VERSION ""

NS_ :

BS_:

BU_: HCM IPMA_ADAS PSCM ABS_ESC PCM ECM_HEV VDM CMR_DSMC SOBDMC_HPCM GWM _delete AWD_DLCM GENERIC TSTR

BO_ 985 IPMA_Data2: 8 IPMA_ADAS
 SG_ LongCtrlBrk_D_Rq : 25|2@0+ (1,0) [0|3] "SED"  SOBDMC_HPCM,PCM,ECM_HEV,GWM
 SG_ LongCtrlEnblDRq_No_Cs : 63|8@0+ (1,0) [0|255] "Unitless"  SOBDMC_HPCM,ECM_HEV,GWM,PCM
 SG_ LongCtrlEnblDRq_No_Cnt : 29|4@0+ (1,0) [0|15] "Unitless"  SOBDMC_HPCM,ECM_HEV,GWM,PCM
 SG_ AdbDrvSide_B_Stat : 35|1@0+ (1,0) [0|1] "SED"  GWM,HCM
 SG_ LcwaMsgTxt_D_Stat : 37|2@0+ (1,0) [0|3] "SED"  GWM
 SG_ AdbDividedRoad_B_Stat : 30|1@0+ (1,0) [0|1] "SED"  HCM,GWM
 SG_ IsaVLimUnit_D_Rq : 15|2@0+ (1,0) [0|3] "SED"  ECM_HEV,GWM,PCM
 SG_ SblmYieldScnr_B_Stat : 31|1@0+ (1,0) [0|1] "SED"  HCM,GWM
 SG_ SblmStopScnr_B_Stat : 8|1@0+ (1,0) [0|1] "SED"  HCM,GWM
 SG_ IsaVLim_D_Rq : 7|8@0+ (1,0) [0|255] "SED"  ECM_HEV,GWM,PCM
 SG_ IaccVLimUnit_D_Rq : 11|2@0+ (1,0) [0|3] "SED"  ECM_HEV,GWM,PCM
 SG_ IaccVLim_D_Rq : 23|8@0+ (1,0) [0|255] "SED"  ECM_HEV,GWM,PCM
 SG_ DasAlrtInfo_D_Dsply : 13|2@0+ (1,0) [0|3] "SED"  GWM
 SG_ SblmRndAbtScnr_B_Stat : 9|1@0+ (1,0) [0|1] "SED"  HCM,GWM
 SG_ PwSustnAdas_B_Rq : 48|1@0+ (1,0) [0|1] "SED"  GWM
 SG_ ClrExitAsstMsgTxt_D_Rq : 52|4@0+ (1,0) [0|15] "SED"  GWM
 SG_ ClrExitAsstChime_D_Rq : 55|3@0+ (1,0) [0|7] "SED"  GWM
 SG_ LongCtrlEnbl_D_Rq : 42|3@0+ (1,0) [0|7] "SED"  SOBDMC_HPCM,GWM,ECM_HEV,PCM
 SG_ SblmPedCrossScnr_B_Stat : 33|1@0+ (1,0) [0|1] "SED"  GWM,HCM
 SG_ TsrRegionTxt_D_Stat : 47|5@0+ (1,0) [0|31] "SED"  GWM
 SG_ LdwChime_B_Rq : 34|1@0+ (1,0) [0|1] "SED"  GWM
 SG_ ClrExitAsst_D_Stat : 39|2@0+ (1,0) [0|3] "SED"  GWM

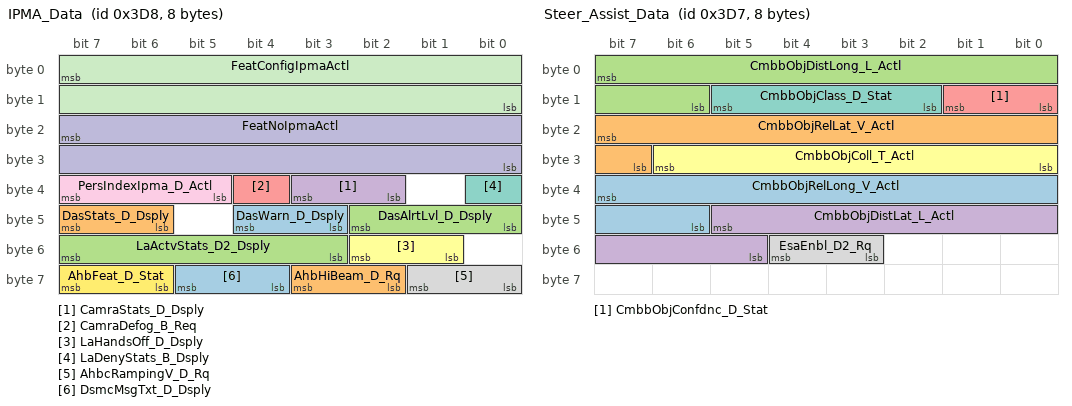
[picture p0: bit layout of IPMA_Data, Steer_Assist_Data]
BO_ 984 IPMA_Data: 8 IPMA_ADAS
 SG_ DasWarn_D_Dsply : 44|2@0+ (1,0) [0|3] "SED"  GWM
 SG_ DasStats_D_Dsply : 47|2@0+ (1,0) [0|3] "SED"  GWM
 SG_ DasAlrtLvl_D_Dsply : 42|3@0+ (1,0) [0|7] "SED"  GWM
 SG_ CamraStats_D_Dsply : 35|2@0+ (1,0) [0|3] "SED"  GWM
 SG_ CamraDefog_B_Req : 36|1@0+ (1,0) [0|1] "SED"  GWM
 SG_ LaHandsOff_D_Dsply : 50|2@0+ (1,0) [0|3] "SED"  GWM
 SG_ LaDenyStats_B_Dsply : 32|1@0+ (1,0) [0|1] "SED"  GWM
 SG_ AhbcRampingV_D_Rq : 57|2@0+ (1,0) [0|3] "SED"  HCM,GWM
 SG_ PersIndexIpma_D_Actl : 39|3@0+ (1,0) [0|7] "SED"  GWM
 SG_ FeatNoIpmaActl : 23|16@0+ (1,0) [0|65535] "Number"  GWM
 SG_ FeatConfigIpmaActl : 7|16@0+ (1,0) [0|65535] "Undefined"  GWM
 SG_ AhbFeat_D_Stat : 63|2@0+ (1,0) [0|3] "SED"  GWM
 SG_ DsmcMsgTxt_D_Dsply : 61|2@0+ (1,0) [0|3] "SED"  GWM
 SG_ AhbHiBeam_D_Rq : 59|2@0+ (1,0) [0|3] "SED"  HCM,GWM
 SG_ LaActvStats_D2_Dsply : 55|5@0+ (1,0) [0|31] "SED"  GWM

BO_ 983 Steer_Assist_Data: 8 IPMA_ADAS
 SG_ CmbbObjRelLong_V_Actl : 39|10@0+ (0.1,-102.1) [-102.1|0] "meters/sec"  PSCM
 SG_ CmbbObjRelLat_V_Actl : 23|9@0+ (0.1,-25.5) [-25.5|25.4] "meters/sec"  PSCM
 SG_ CmbbObjDistLong_L_Actl : 7|10@0+ (0.1,0) [0|102.1] "meter"  PSCM
 SG_ CmbbObjDistLat_L_Actl : 45|9@0+ (0.1,-25.5) [-25.5|25.4] "meter"  PSCM
 SG_ CmbbObjConfdnc_D_Stat : 9|2@0+ (1,0) [0|3] "SED"  PSCM
 SG_ CmbbObjColl_T_Actl : 30|7@0+ (0.05,0) [0|6.25] "second"  PSCM
 SG_ CmbbObjClass_D_Stat : 13|4@0+ (1,0) [0|15] "SED"  PSCM
 SG_ EsaEnbl_D2_Rq : 52|2@0+ (1,0) [0|3] "SED"  PSCM

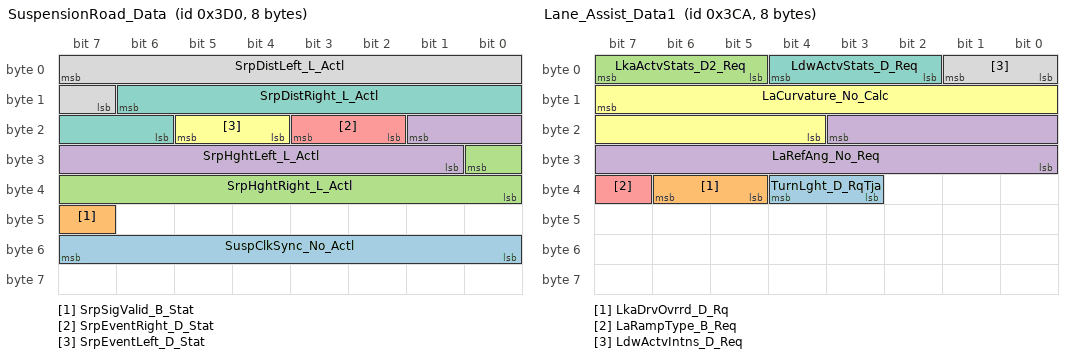
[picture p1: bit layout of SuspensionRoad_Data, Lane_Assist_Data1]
BO_ 976 SuspensionRoad_Data: 8 IPMA_ADAS
 SG_ SuspClkSync_No_Actl : 55|8@0+ (1,0) [0|253] "unitless"  GWM
 SG_ SrpSigValid_B_Stat : 47|1@0+ (1,0) [0|1] "SED"  GWM
 SG_ SrpHghtRight_L_Actl : 24|9@0+ (0.000625,-0.16) [-0.16|0.158125] "meter"  GWM
 SG_ SrpHghtLeft_L_Actl : 17|9@0+ (0.000625,-0.16) [-0.16|0.158125] "meter"  GWM
 SG_ SrpEventRight_D_Stat : 19|2@0+ (1,0) [0|3] "SED"  GWM
 SG_ SrpEventLeft_D_Stat : 21|2@0+ (1,0) [0|3] "SED"  GWM
 SG_ SrpDistRight_L_Actl : 14|9@0+ (0.02,0) [0|10.18] "meter"  GWM
 SG_ SrpDistLeft_L_Actl : 7|9@0+ (0.02,0) [0|10.18] "meter"  GWM

BO_ 973 Traffic_RecognitnData: 8 IPMA_ADAS
 SG_ PersCtaSplitView_D_Stat : 12|2@0+ (1,0) [0|3] "SED"  GWM
 SG_ TsrVl2PrmntMsgTxt_D_Rq : 60|2@0+ (1,0) [0|3] "SED"  GWM
 SG_ TsrVl1PrmntMsgTxt_D_Rq : 41|2@0+ (1,0) [0|3] "SED"  GWM
 SG_ TsrVl2RstrcMsgTxt2_D_Rq : 63|3@0+ (1,0) [0|7] "SED"  GWM
 SG_ TsrVl1RstrcMsgTxt2_D_Rq : 51|3@0+ (1,0) [0|7] "SED"  GWM
 SG_ TsrOvtkMsgTxt2_D_Rq : 55|4@0+ (1,0) [0|15] "SED"  GWM
 SG_ WwaWarn_B_Rq : 48|1@0+ (1,0) [0|1] "SED"  GWM
 SG_ TsrVlUnitMsgTxt_D_Rq : 43|2@0+ (1,0) [0|3] "SED"  GWM
 SG_ TsrVLim2MsgTxt_D_Rq : 39|8@0+ (1,0) [0|255] "SED"  GWM
 SG_ TsrVLim1MsgTxt_D_Rq : 31|8@0+ (1,0) [0|255] "SED"  GWM
 SG_ TsrVl2StatMsgTxt_D_Rq : 47|2@0+ (1,0) [0|3] "SED"  GWM
 SG_ TsrVl2RstrcMsgTxt_D_Rq : 17|2@0+ (1,0) [0|3] "SED"  GWM
 SG_ TsrVl1StatMsgTxt_D_Rq : 21|2@0+ (1,0) [0|3] "SED"  GWM
 SG_ TsrVl1RstrcMsgTxt_D_Rq : 23|2@0+ (1,0) [0|3] "SED"  GWM
 SG_ TsrStatMsgTxt_D_Rq : 10|3@0+ (1,0) [0|7] "SED"  GWM
 SG_ TsrOvtkStatMsgTxt_D_Rq : 1|2@0+ (1,0) [0|3] "SED"  GWM
 SG_ TsrOvtkMsgTxt_D_Rq : 15|3@0+ (1,0) [0|7] "SED"  GWM
 SG_ TsrOswWarnMsgTxt_D_Rq : 3|2@0+ (1,0) [0|3] "SED"  GWM
 SG_ TsrMsgTxt_D_Rq : 7|4@0+ (1,0) [0|15] "SED"  GWM
 SG_ LaSysOffStat_D_Dsply : 58|2@0+ (1,0) [0|3] "SED"  GWM

BO_ 970 Lane_Assist_Data1: 8 IPMA_ADAS
 SG_ TurnLght_D_RqTja : 36|2@0+ (1,0) [0|3] "SED"  GWM
 SG_ LkaDrvOvrrd_D_Rq : 38|2@0+ (1,0) [0|3] "SED"  PSCM
 SG_ LkaActvStats_D2_Req : 7|3@0+ (1,0) [0|7] "SED"  PSCM
 SG_ LaRefAng_No_Req : 19|12@0+ (0.05,-102.4) [-102.4|102.3] "mrad"  PSCM
 SG_ LaRampType_B_Req : 39|1@0+ (1,0) [0|1] "SED"  PSCM
 SG_ LaCurvature_No_Calc : 15|12@0+ (5E-006,-0.01024) [-0.01024|0.01023] "1/m"  PSCM
 SG_ LdwActvStats_D_Req : 4|3@0+ (1,0) [0|7] "SED"  PSCM
 SG_ LdwActvIntns_D_Req : 1|2@0+ (1,0) [0|3] "SED"  PSCM

BO_ 394 ACCDATA_3: 8 IPMA_ADAS
 SG_ AccTrgDist2_D_Dsply : 27|4@0+ (1,0) [0|15] "SED"  GWM
 SG_ AccStopRes_B_Dsply : 54|1@0+ (1,0) [0|1] "SED"  GWM
 SG_ TjaWarn_D_Rq : 50|3@0+ (1,0) [0|7] "SED"  GWM
 SG_ Tja_D_Stat : 44|3@0+ (1,0) [0|7] "SED"  CMR_DSMC,GWM
 SG_ TjaMsgTxt_D_Dsply : 53|3@0+ (1,0) [0|7] "SED"  GWM
 SG_ IaccLamp_D_Rq : 46|2@0+ (1,0) [0|3] "SED"  GWM
 SG_ AccMsgTxt_D2_Rq : 31|4@0+ (1,0) [0|15] "SED"  GWM
 SG_ FcwDeny_B_Dsply : 10|1@0+ (1,0) [0|1] "SED"  GWM
 SG_ FcwMemStat_B_Actl : 13|1@0+ (1,0) [0|1] "SED"  GWM
 SG_ AccTGap_B_Dsply : 35|1@0+ (1,0) [0|1] "SED"  GWM
 SG_ CadsAlignIncplt_B_Actl : 11|1@0+ (1,0) [0|1] "SED"  GWM
 SG_ AccFllwMde_B_Dsply : 17|1@0+ (1,0) [0|1] "SED"  GWM
 SG_ CadsRadrBlck_B_Actl : 22|1@0+ (1,0) [0|1] "SED"  GWM
 SG_ CmbbPostEvnt_B_Dsply : 15|1@0+ (1,0) [0|1] "SED"  GWM
 SG_ AccStopMde_B_Dsply : 0|1@0+ (1,0) [0|1] "SED"  GWM
 SG_ FcwMemSens_D_Actl : 20|2@0+ (1,0) [0|3] "SED"  GWM
 SG_ FcwMsgTxt_D_Rq : 7|3@0+ (1,0) [0|7] "SED"  GWM
 SG_ AccWarn_D_Dsply : 39|2@0+ (1,0) [0|3] "SED"  GWM
 SG_ FcwVisblWarn_B_Rq : 47|1@0+ (1,0) [0|1] "SED"  GWM
 SG_ FcwAudioWarn_B_Rq : 8|1@0+ (1,0) [0|1] "SED"  GWM
 SG_ AccTGap_D_Dsply : 34|3@0+ (1,0) [0|7] "SED"  GWM
 SG_ AccMemEnbl_B_RqDrv : 36|1@0+ (1,0) [0|1] "SED"  GWM
 SG_ AccStopStat_D_Dsply : 41|2@0+ (1,0) [0|3] "SED"  GWM
 SG_ HaDsply_No_Cs : 63|8@0+ (1,0) [0|255] "Unitless"  GWM
 SG_ HaDsply_No_Cnt : 4|4@0+ (1,0) [0|15] "Unitless"  GWM

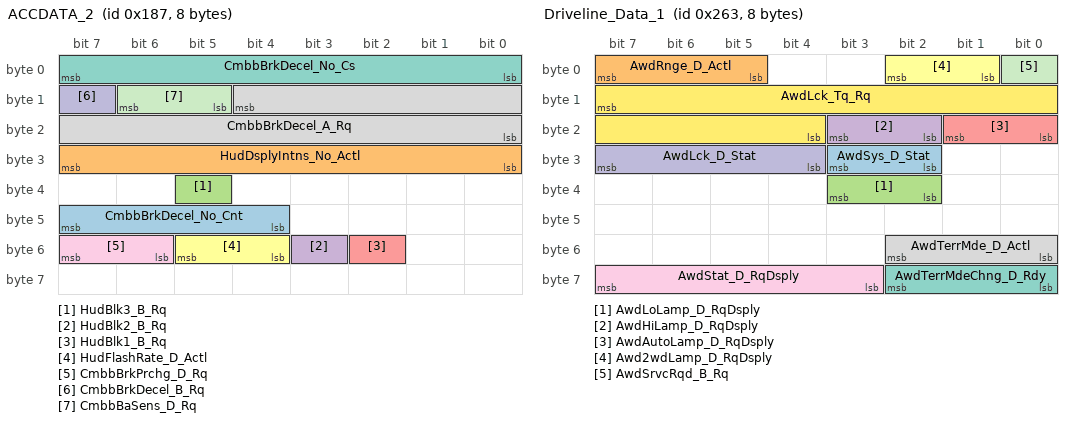
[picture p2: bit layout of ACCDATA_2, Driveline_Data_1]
BO_ 391 ACCDATA_2: 8 IPMA_ADAS
 SG_ CmbbBrkDecel_No_Cnt : 47|4@0+ (1,0) [0|15] "Unitless"  ABS_ESC
 SG_ HudDsplyIntns_No_Actl : 31|8@0+ (0.5,0) [0|100] "%"  GWM
 SG_ HudBlk3_B_Rq : 37|1@0+ (1,0) [0|1] "SED"  GWM
 SG_ HudBlk2_B_Rq : 51|1@0+ (1,0) [0|1] "SED"  GWM
 SG_ HudBlk1_B_Rq : 50|1@0+ (1,0) [0|1] "SED"  GWM
 SG_ HudFlashRate_D_Actl : 53|2@0+ (1,0) [0|3] "SED"  GWM
 SG_ CmbbBrkDecel_No_Cs : 7|8@0+ (1,0) [0|255] "Unitless"  ABS_ESC
 SG_ CmbbBrkDecel_A_Rq : 12|13@0+ (0.0039,-20) [-20|11.9449] "m/s^2"  ABS_ESC,GWM
 SG_ CmbbBrkPrchg_D_Rq : 55|2@0+ (1,0) [0|3] "SED"  ABS_ESC,GWM
 SG_ CmbbBrkDecel_B_Rq : 15|1@0+ (1,0) [0|1] "SED"  ABS_ESC,GWM,CMR_DSMC
 SG_ CmbbBaSens_D_Rq : 14|2@0+ (1,0) [0|3] "SED"  ABS_ESC,GWM

BO_ 390 ACCDATA: 8 IPMA_ADAS
 SG_ AccBrkTot_A_Rq : 4|13@0+ (0.0039,-20) [-20|11.9449] "m/s^2"  ABS_ESC
 SG_ AccPrpl_A_Pred : 17|10@0+ (0.01,-5) [-5|5.23] "m/s^2"  ECM_HEV,PCM
 SG_ AccVeh_V_Trg : 32|9@0+ (0.5,0) [0|255.5] "kph"  PCM
 SG_ AccBrkPrkEl_B_Rq : 38|1@0+ (1,0) [0|1] "SED"  ABS_ESC
 SG_ Cmbb_B_Enbl : 50|1@0+ (1,0) [0|1] "SED"  GWM
 SG_ CmbbOvrrd_B_RqDrv : 51|1@0+ (1,0) [0|1] "SED"  GWM
 SG_ CmbbDeny_B_Actl : 37|1@0+ (1,0) [0|1] "SED"  SOBDMC_HPCM,GWM,ABS_ESC
 SG_ CmbbEngTqMn_B_Rq : 52|1@0+ (1,0) [0|1] "SED"  SOBDMC_HPCM,ECM_HEV,PCM,GWM
 SG_ AccPrpl_A_Rq : 49|10@0+ (0.01,-5) [-5|5.23] "m/s^2"  ECM_HEV,PCM
 SG_ AccDeny_B_Rq : 53|1@0+ (1,0) [0|1] "SED"  ECM_HEV,PCM
 SG_ AccResumEnbl_B_Rq : 33|1@0+ (1,0) [0|1] "SED"  ECM_HEV,PCM
 SG_ AccCancl_B_Rq : 39|1@0+ (1,0) [0|1] "SED"  ECM_HEV,PCM
 SG_ AccBrkPrchg_B_Rq : 54|1@0+ (1,0) [0|1] "SED"  ABS_ESC
 SG_ AccBrkDecel_B_Rq : 55|1@0+ (1,0) [0|1] "SED"  ABS_ESC
 SG_ AccStopStat_B_Rq : 34|1@0+ (1,0) [0|1] "SED"  ECM_HEV,PCM,ABS_ESC
 SG_ AccAutoResum_D_Rq : 7|2@0+ (1,0) [0|3] "SED"  ECM_HEV,PCM
 SG_ AccBrkPulse_B_Rq : 36|1@0+ (1,0) [0|1] "SED"  GWM,ABS_ESC

BO_ 611 Driveline_Data_1: 8 AWD_DLCM
 SG_ AwdSys_D_Stat : 27|2@0+ (1,0) [0|3] "SED"  GWM
 SG_ AwdRnge_D_Actl : 7|3@0+ (1,0) [0|7] "SED"  GWM
 SG_ AwdLoLamp_D_RqDsply : 35|2@0+ (1,0) [0|3] "SED"  GWM
 SG_ AwdHiLamp_D_RqDsply : 19|2@0+ (1,0) [0|3] "SED"  GWM
 SG_ AwdAutoLamp_D_RqDsply : 17|2@0+ (1,0) [0|3] "SED"  GWM
 SG_ Awd2wdLamp_D_RqDsply : 2|2@0+ (1,0) [0|3] "SED"  GWM
 SG_ AwdTerrMdeChng_D_Rdy : 58|3@0+ (1,0) [0|7] "SED"  GWM
 SG_ AwdTerrMde_D_Actl : 50|3@0+ (1,0) [0|7] "SED"  GWM
 SG_ AwdStat_D_RqDsply : 63|5@0+ (1,0) [0|31] "SED"  ABS_ESC,GWM
 SG_ AwdLck_D_Stat : 31|4@0+ (1,0) [0|15] "SED"  ABS_ESC,PSCM,GWM,PCM
 SG_ AwdSrvcRqd_B_Rq : 0|1@0+ (1,0) [0|1] "SED"  ABS_ESC,GWM
 SG_ AwdLck_Tq_Rq : 15|12@0+ (1,0) [0|4093] "Nm"  ABS_ESC,GWM

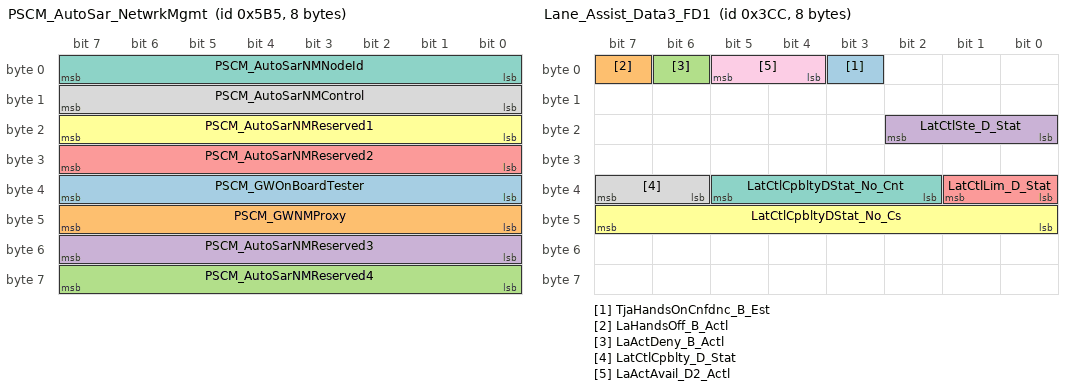
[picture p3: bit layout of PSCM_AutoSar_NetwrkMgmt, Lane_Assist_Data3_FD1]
BO_ 1461 PSCM_AutoSar_NetwrkMgmt: 8 PSCM
 SG_ PSCM_GWOnBoardTester : 39|8@0+ (1,0) [0|255] "unitless"  GENERIC,ABS_ESC
 SG_ PSCM_GWNMProxy : 47|8@0+ (1,0) [0|255] "unitless"  GENERIC,ABS_ESC
 SG_ PSCM_AutoSarNMReserved4 : 63|8@0+ (1,0) [0|255] "unitless"  GENERIC,ABS_ESC
 SG_ PSCM_AutoSarNMReserved3 : 55|8@0+ (1,0) [0|255] "unitless"  GENERIC,ABS_ESC
 SG_ PSCM_AutoSarNMReserved2 : 31|8@0+ (1,0) [0|255] "unitless"  ABS_ESC,GENERIC
 SG_ PSCM_AutoSarNMReserved1 : 23|8@0+ (1,0) [0|255] "unitless"  ABS_ESC,GENERIC
 SG_ PSCM_AutoSarNMNodeId : 7|8@0+ (1,0) [0|255] "unitless"  ABS_ESC,GENERIC
 SG_ PSCM_AutoSarNMControl : 15|8@0+ (1,0) [0|255] "unitless"  ABS_ESC,GENERIC

BO_ 1047 TrailerAid_Data2: 8 PSCM
 SG_ EsaOn_B_Stat : 23|1@0+ (1,0) [0|1] "SED"  GWM
 SG_ SelDrvMdeSte_D_Stat : 17|2@0+ (1,0) [0|3] "SED"  ABS_ESC

BO_ 972 Lane_Assist_Data3_FD1: 8 PSCM
 SG_ TjaHandsOnCnfdnc_B_Est : 3|1@0+ (1,0) [0|1] "SED"  GWM,IPMA_ADAS
 SG_ LaHandsOff_B_Actl : 7|1@0+ (1,0) [0|1] "SED"  IPMA_ADAS,GWM
 SG_ LaActDeny_B_Actl : 6|1@0+ (1,0) [0|1] "SED"  IPMA_ADAS,GWM
 SG_ LatCtlSte_D_Stat : 18|3@0+ (1,0) [0|7] "SED"  IPMA_ADAS,GWM
 SG_ LatCtlLim_D_Stat : 33|2@0+ (1,0) [0|3] "SED"  IPMA_ADAS,GWM
 SG_ LatCtlCpbltyDStat_No_Cs : 47|8@0+ (1,0) [0|255] "Unitless"  GWM,IPMA_ADAS
 SG_ LatCtlCpbltyDStat_No_Cnt : 37|4@0+ (1,0) [0|15] "Unitless"  GWM,IPMA_ADAS
 SG_ LatCtlCpblty_D_Stat : 39|2@0+ (1,0) [0|3] "SED"  GWM,IPMA_ADAS
 SG_ LaActAvail_D2_Actl : 5|2@0+ (1,0) [0|3] "SED"  IPMA_ADAS,GWM

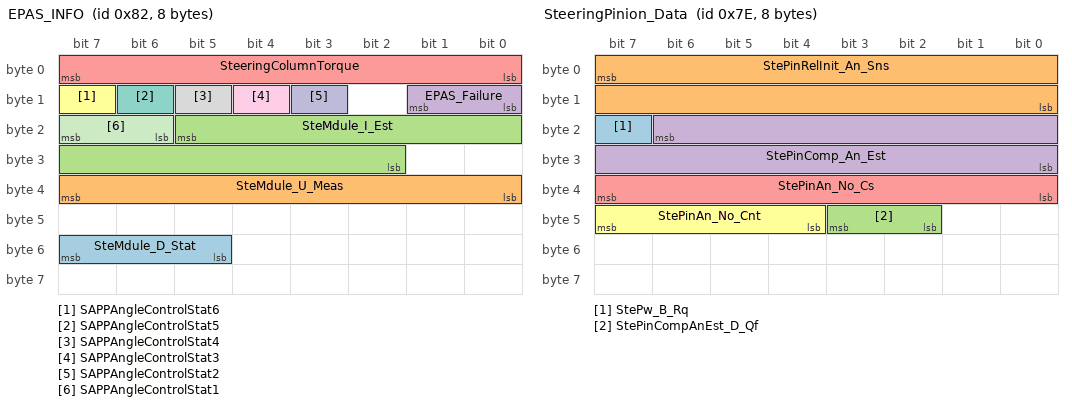
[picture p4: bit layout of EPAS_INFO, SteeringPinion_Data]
BO_ 130 EPAS_INFO: 8 PSCM
 SG_ SteMdule_D_Stat : 55|3@0+ (1,0) [0|7] "SED"  GWM
 SG_ SteMdule_U_Meas : 39|8@0+ (0.05,6) [6|18.7] "Volts"  GWM
 SG_ SteMdule_I_Est : 21|12@0+ (0.05,-64) [-64|140.7] "Amps"  GWM
 SG_ EPAS_Failure : 9|2@0+ (1,0) [0|3] "SED"  IPMA_ADAS,GWM
 SG_ SteeringColumnTorque : 7|8@0+ (0.0625,-8) [-8|7.8125] "Nm"  IPMA_ADAS
 SG_ SAPPAngleControlStat6 : 15|1@0+ (1,0) [0|1] "SED"  IPMA_ADAS
 SG_ SAPPAngleControlStat5 : 14|1@0+ (1,0) [0|1] "SED"  IPMA_ADAS
 SG_ SAPPAngleControlStat4 : 13|1@0+ (1,0) [0|1] "SED"  IPMA_ADAS
 SG_ SAPPAngleControlStat3 : 12|1@0+ (1,0) [0|1] "SED"  IPMA_ADAS
 SG_ SAPPAngleControlStat2 : 11|1@0+ (1,0) [0|1] "SED"  IPMA_ADAS
 SG_ SAPPAngleControlStat1 : 23|2@0+ (1,0) [0|3] "SED"  IPMA_ADAS

BO_ 126 SteeringPinion_Data: 8 PSCM
 SG_ StePw_B_Rq : 23|1@0+ (1,0) [0|1] "SED"  PCM,GWM,ECM_HEV
 SG_ StePinRelInit_An_Sns : 7|16@0+ (0.1,-3200) [-3200|3353.3] "degrees"  PCM,VDM,IPMA_ADAS,GWM,ECM_HEV,ABS_ESC
 SG_ StePinCompAnEst_D_Qf : 43|2@0+ (1,0) [0|3] "SED"  PCM,CMR_DSMC,VDM,SOBDMC_HPCM,HCM,IPMA_ADAS,ECM_HEV,ABS_ESC,AWD_DLCM,GWM
 SG_ StePinComp_An_Est : 22|15@0+ (0.1,-1600) [-1600|1676.7] "degrees"  PCM,CMR_DSMC,VDM,SOBDMC_HPCM,HCM,IPMA_ADAS,ECM_HEV,ABS_ESC,AWD_DLCM,GWM
 SG_ StePinAn_No_Cs : 39|8@0+ (1,0) [0|255] "Unitless"  VDM,ABS_ESC,GWM
 SG_ StePinAn_No_Cnt : 47|4@0+ (1,0) [0|15] "unitless"  VDM,GWM,ABS_ESC

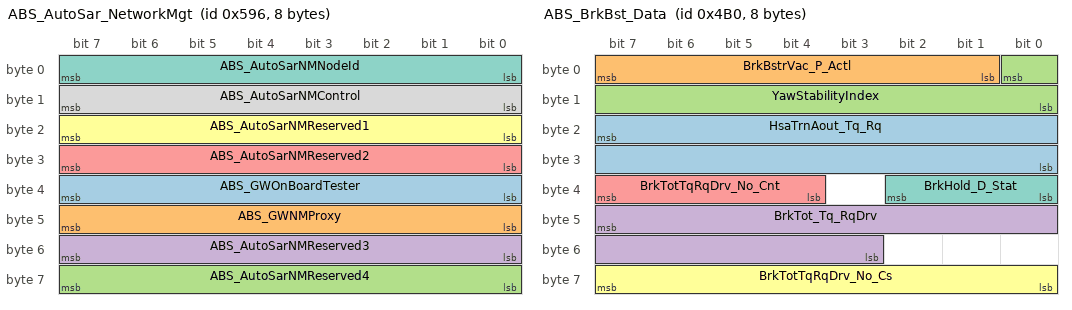
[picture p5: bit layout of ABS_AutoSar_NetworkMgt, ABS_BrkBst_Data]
BO_ 1430 ABS_AutoSar_NetworkMgt: 8 ABS_ESC
 SG_ ABS_GWOnBoardTester : 39|8@0+ (1,0) [0|255] "unitless"  GENERIC
 SG_ ABS_GWNMProxy : 47|8@0+ (1,0) [0|255] "unitless"  GENERIC
 SG_ ABS_AutoSarNMReserved4 : 63|8@0+ (1,0) [0|255] "unitless"  GENERIC
 SG_ ABS_AutoSarNMReserved3 : 55|8@0+ (1,0) [0|255] "unitless"  GENERIC
 SG_ ABS_AutoSarNMReserved2 : 31|8@0+ (1,0) [0|255] "unitless"  GENERIC
 SG_ ABS_AutoSarNMReserved1 : 23|8@0+ (1,0) [0|255] "unitless"  GENERIC
 SG_ ABS_AutoSarNMNodeId : 7|8@0+ (1,0) [0|255] "unitless"  GENERIC
 SG_ ABS_AutoSarNMControl : 15|8@0+ (1,0) [0|255] "unitless"  GENERIC

BO_ 1200 ABS_BrkBst_Data: 8 ABS_ESC
 SG_ HsaTrnAout_Tq_Rq : 23|16@0+ (4,-131072) [-131072|131060] "Nm"  GWM
 SG_ BrkBstrVac_P_Actl : 7|7@0+ (8,0) [0|1008] "Millibar"  ECM_HEV,PCM,GWM
 SG_ YawStabilityIndex : 0|9@0+ (1,-256) [-256|255] "%"  IPMA_ADAS,PSCM,GWM,VDM
 SG_ BrkTot_Tq_RqDrv : 47|13@0+ (4,0) [0|32760] "Nm"  SOBDMC_HPCM,IPMA_ADAS,ECM_HEV,PCM,GWM,AWD_DLCM
 SG_ BrkTotTqRqDrv_No_Cnt : 39|4@0+ (1,0) [0|15] "unitless"  ECM_HEV,PCM,GWM
 SG_ BrkTotTqRqDrv_No_Cs : 63|8@0+ (1,0) [0|255] "unitless"  ECM_HEV,PCM,GWM
 SG_ BrkHold_D_Stat : 34|3@0+ (1,0) [0|7] "SED"  ECM_HEV,IPMA_ADAS,PCM,SOBDMC_HPCM,GWM

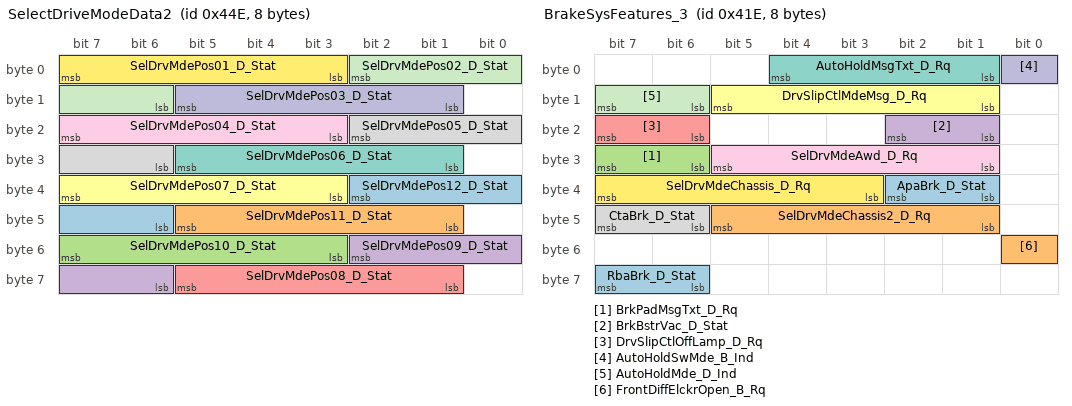
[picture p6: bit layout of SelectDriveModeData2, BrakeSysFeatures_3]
BO_ 1102 SelectDriveModeData2: 8 ABS_ESC
 SG_ SelDrvMdePos12_D_Stat : 34|5@0+ (1,0) [0|31] "SED"  GWM
 SG_ SelDrvMdePos11_D_Stat : 45|5@0+ (1,0) [0|31] "SED"  GWM
 SG_ SelDrvMdePos10_D_Stat : 55|5@0+ (1,0) [0|31] "SED"  GWM
 SG_ SelDrvMdePos09_D_Stat : 50|5@0+ (1,0) [0|31] "SED"  GWM
 SG_ SelDrvMdePos08_D_Stat : 61|5@0+ (1,0) [0|31] "SED"  GWM
 SG_ SelDrvMdePos07_D_Stat : 39|5@0+ (1,0) [0|31] "SED"  GWM
 SG_ SelDrvMdePos06_D_Stat : 29|5@0+ (1,0) [0|31] "SED"  GWM
 SG_ SelDrvMdePos05_D_Stat : 18|5@0+ (1,0) [0|31] "SED"  GWM
 SG_ SelDrvMdePos04_D_Stat : 23|5@0+ (1,0) [0|31] "SED"  GWM
 SG_ SelDrvMdePos03_D_Stat : 13|5@0+ (1,0) [0|31] "SED"  GWM
 SG_ SelDrvMdePos02_D_Stat : 2|5@0+ (1,0) [0|31] "SED"  GWM
 SG_ SelDrvMdePos01_D_Stat : 7|5@0+ (1,0) [0|31] "SED"  GWM

BO_ 1056 SelectDriveModeData: 8 ABS_ESC
 SG_ VehVActlBrk_No_Corr : 0|8@1+ (0.001,0.9) [0.9|1.153] "unitless"  PCM,GWM,ECM_HEV
 SG_ SelDrvMdePos12_B_Avail : 54|1@0+ (1,0) [0|1] "SED"  GWM
 SG_ SelDrvMdePos11_B_Avail : 55|1@0+ (1,0) [0|1] "SED"  GWM
 SG_ SelDrvMdePos10_B_Avail : 40|1@0+ (1,0) [0|1] "SED"  GWM
 SG_ SelDrvMdePos09_B_Avail : 41|1@0+ (1,0) [0|1] "SED"  GWM
 SG_ SelDrvMdePos08_B_Avail : 42|1@0+ (1,0) [0|1] "SED"  GWM
 SG_ SelDrvMdePos07_B_Avail : 43|1@0+ (1,0) [0|1] "SED"  GWM
 SG_ SelDrvMdePos06_B_Avail : 44|1@0+ (1,0) [0|1] "SED"  GWM
 SG_ SelDrvMdePos05_B_Avail : 45|1@0+ (1,0) [0|1] "SED"  GWM
 SG_ SelDrvMdePos04_B_Avail : 46|1@0+ (1,0) [0|1] "SED"  GWM
 SG_ SelDrvMdePos03_B_Avail : 47|1@0+ (1,0) [0|1] "SED"  GWM
 SG_ SelDrvMdePos02_B_Avail : 32|1@0+ (1,0) [0|1] "SED"  GWM
 SG_ SelDrvMdePos01_B_Avail : 24|1@0+ (1,0) [0|1] "SED"  GWM
 SG_ ActvDrvMde_D2_Stat : 53|5@0+ (1,0) [0|31] "SED"  IPMA_ADAS,GWM
 SG_ SelDrvMde_D2_Rq : 63|5@0+ (1,0) [0|31] "SED"  GWM
 SG_ SelDrvMdePt_D_Rq : 31|5@0+ (1,0) [0|31] "SED"  SOBDMC_HPCM,ECM_HEV,PCM,GWM
 SG_ SelDrvMdeMsgTxt_D_Rq : 19|4@0+ (1,0) [0|15] "SED"  AWD_DLCM,GWM
 SG_ SelDrvMde_D_Stat : 26|2@0+ (1,0) [0|3] "SED"  GWM
 SG_ AwdMde_D_RqBrk : 35|3@0+ (1,0) [0|7] "SED"  GWM
 SG_ SelDrvMdeMsgTxt2_D_Rq : 23|4@0+ (1,0) [0|15] "SED"  GWM
 SG_ SelDrvMdeHmi03_D_Rq : 12|5@0+ (1,0) [0|31] "SED"  GWM

BO_ 1054 BrakeSysFeatures_3: 8 ABS_ESC
 SG_ RbaBrk_D_Stat : 63|2@0+ (1,0) [0|3] "SED"  IPMA_ADAS,GWM
 SG_ SelDrvMdeChassis2_D_Rq : 45|5@0+ (1,0) [0|31] "SED"  PSCM,GWM
 SG_ BrkPadMsgTxt_D_Rq : 31|2@0+ (1,0) [0|3] "SED"  GWM
 SG_ BrkBstrVac_D_Stat : 18|2@0+ (1,0) [0|3] "SED"  PCM,GWM
 SG_ DrvSlipCtlOffLamp_D_Rq : 23|2@0+ (1,0) [0|3] "SED"  GWM
 SG_ DrvSlipCtlMdeMsg_D_Rq : 13|5@0+ (1,0) [0|31] "SED"  GWM
 SG_ AutoHoldMsgTxt_D_Rq : 4|4@0+ (1,0) [0|15] "SED"  GWM
 SG_ CtaBrk_D_Stat : 47|2@0+ (1,0) [0|3] "SED"  GWM,IPMA_ADAS
 SG_ SelDrvMdeAwd_D_Rq : 29|5@0+ (1,0) [0|31] "SED"  AWD_DLCM,ECM_HEV,GWM,PCM
 SG_ AutoHoldSwMde_B_Ind : 0|1@0+ (1,0) [0|1] "SED"  GWM
 SG_ AutoHoldMde_D_Ind : 15|2@0+ (1,0) [0|3] "SED"  GWM
 SG_ SelDrvMdeChassis_D_Rq : 39|5@0+ (1,0) [0|31] "SED"  GWM,VDM
 SG_ ApaBrk_D_Stat : 34|2@0+ (1,0) [0|3] "SED"  ECM_HEV,IPMA_ADAS,PCM,GWM
 SG_ FrontDiffElckrOpen_B_Rq : 48|1@0+ (1,0) [0|1] "SED"  GWM

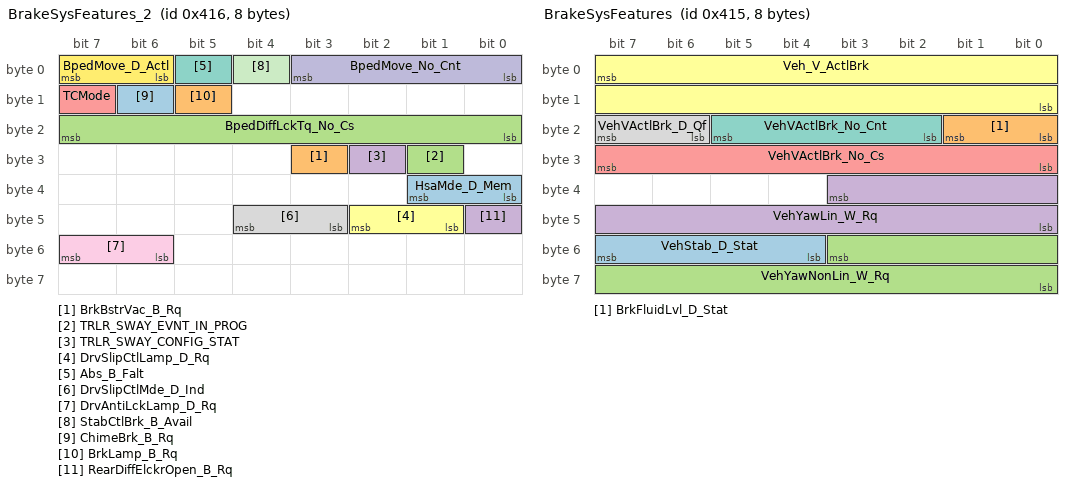
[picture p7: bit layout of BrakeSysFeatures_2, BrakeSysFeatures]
BO_ 1046 BrakeSysFeatures_2: 8 ABS_ESC
 SG_ HsaMde_D_Mem : 33|2@0+ (1,0) [0|3] "SED"  GWM
 SG_ BrkBstrVac_B_Rq : 27|1@0+ (1,0) [0|1] "Discrete"  ECM_HEV,SOBDMC_HPCM,PCM,GWM
 SG_ TRLR_SWAY_EVNT_IN_PROG : 25|1@0+ (1,0) [0|1] "SED"  GWM
 SG_ TRLR_SWAY_CONFIG_STAT : 26|1@0+ (1,0) [0|1] "SED"  GWM
 SG_ TCMode : 15|1@0+ (1,0) [0|1] "SED"  SOBDMC_HPCM,IPMA_ADAS,ECM_HEV,PCM,VDM,GWM,AWD_DLCM
 SG_ DrvSlipCtlLamp_D_Rq : 42|2@0+ (1,0) [0|3] "SED"  IPMA_ADAS,ECM_HEV,PCM,GWM,VDM,AWD_DLCM
 SG_ Abs_B_Falt : 5|1@0+ (1,0) [0|1] "SED"  SOBDMC_HPCM,ECM_HEV,PCM,GWM
 SG_ DrvSlipCtlMde_D_Ind : 44|2@0+ (1,0) [0|3] "SED"  SOBDMC_HPCM,IPMA_ADAS,ECM_HEV,PCM,GWM,AWD_DLCM
 SG_ DrvAntiLckLamp_D_Rq : 55|2@0+ (1,0) [0|3] "SED"  GWM,IPMA_ADAS
 SG_ BpedMove_No_Cnt : 3|4@0+ (1,0) [0|15] "Unitless"  SOBDMC_HPCM,GWM
 SG_ StabCtlBrk_B_Avail : 4|1@0+ (1,0) [0|1] "SED"  GWM,VDM,AWD_DLCM
 SG_ BpedMove_D_Actl : 7|2@0+ (1,0) [0|3] "SED"  SOBDMC_HPCM,GWM
 SG_ ChimeBrk_B_Rq : 14|1@0+ (1,0) [0|1] "SED"  GWM
 SG_ BrkLamp_B_Rq : 13|1@0+ (1,0) [0|1] "SED"  GWM
 SG_ BpedDiffLckTq_No_Cs : 23|8@0+ (1,0) [0|255] "Unitless"  SOBDMC_HPCM,GWM
 SG_ RearDiffElckrOpen_B_Rq : 40|1@0+ (1,0) [0|1] "SED"  GWM

BO_ 1045 BrakeSysFeatures: 8 ABS_ESC
 SG_ VehStab_D_Stat : 55|4@0+ (1,0) [0|15] "SED"  HCM,SOBDMC_HPCM,PCM,ECM_HEV,GWM,AWD_DLCM
 SG_ BrkFluidLvl_D_Stat : 17|2@0+ (1,0) [0|3] "SED"  GWM
 SG_ VehYawNonLin_W_Rq : 51|12@0+ (0.03663,-75) [-75|74.92659] "deg/s"  SOBDMC_HPCM,GWM,AWD_DLCM
 SG_ VehYawLin_W_Rq : 35|12@0+ (0.03663,-75) [-75|74.92659] "deg/s"  SOBDMC_HPCM,GWM,AWD_DLCM
 SG_ VehVActlBrk_No_Cs : 31|8@0+ (1,0) [0|255] "Unitless"  VDM,SOBDMC_HPCM,ECM_HEV,PCM,PSCM,GWM,CMR_DSMC,IPMA_ADAS
 SG_ Veh_V_ActlBrk : 7|16@0+ (0.01,0) [0|655.35] "kph"  VDM,SOBDMC_HPCM,IPMA_ADAS,ECM_HEV,PCM,PSCM,GWM,AWD_DLCM,CMR_DSMC
 SG_ VehVActlBrk_No_Cnt : 21|4@0+ (1,0) [0|15] "Unitless"  VDM,SOBDMC_HPCM,ECM_HEV,PCM,PSCM,GWM,CMR_DSMC,IPMA_ADAS
 SG_ VehVActlBrk_D_Qf : 23|2@0+ (1,0) [0|3] "SED"  SOBDMC_HPCM,IPMA_ADAS,ECM_HEV,PCM,PSCM,GWM,AWD_DLCM,CMR_DSMC,VDM

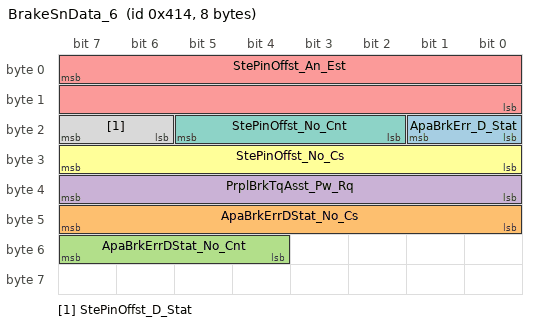
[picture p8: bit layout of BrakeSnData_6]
BO_ 1044 BrakeSnData_6: 8 ABS_ESC
 SG_ ApaBrkErr_D_Stat : 17|2@0+ (1,0) [0|3] "SED"  GWM,PCM,SOBDMC_HPCM
 SG_ ApaBrkErrDStat_No_Cs : 47|8@0+ (1,0) [0|255] "Unitless"  GWM,PCM,SOBDMC_HPCM
 SG_ ApaBrkErrDStat_No_Cnt : 55|4@0+ (1,0) [0|15] "Unitless"  GWM,PCM,SOBDMC_HPCM
 SG_ PrplBrkTqAsst_Pw_Rq : 39|8@0+ (100,0) [0|25500] "watts"  SOBDMC_HPCM,GWM
 SG_ StePinOffst_An_Est : 7|16@0+ (0.1,-3200) [-3200|3353.3] "degrees"  GWM,PSCM
 SG_ StePinOffst_No_Cs : 31|8@0+ (1,0) [0|255] "Unitless"  GWM,PSCM
 SG_ StePinOffst_No_Cnt : 21|4@0+ (1,0) [0|15] "unitless"  GWM,PSCM
 SG_ StePinOffst_D_Stat : 23|2@0+ (1,0) [0|3] "SED"  GWM,PSCM

BO_ 1042 TrailerBrakeData: 8 ABS_ESC
 SG_ VehRol_An_Dsply : 31|7@0+ (1,-64) [-64|61] "degrees"  GWM
 SG_ VehPtch_An_Dsply : 23|7@0+ (1,-64) [-64|61] "degrees"  GWM

BO_TX_BU_ 611 : SOBDMC_HPCM,AWD_DLCM;
CM_ SG_ 985 LongCtrlEnblDRq_No_Cs "Signal not transmitted on gas and diesel variants.";
CM_ SG_ 985 LongCtrlEnblDRq_No_Cnt "Signal not transmitted on gas and diesel variants.";
CM_ SG_ 394 HaDsply_No_Cs "Signal not transmitted on gas variants.";
CM_ SG_ 394 HaDsply_No_Cnt "Signal not transmitted on gas variants.";
CM_ SG_ 390 AccPrpl_A_Rq "PCMGenSigTimeoutTime=1000";
CM_ BO_ 611 "Used on Applications with 4x4 supplied by Motorola.";
CM_ SG_ 611 AwdStat_D_RqDsply "Signal not transmitted on programs that do not have AWD.";
CM_ SG_ 611 AwdSrvcRqd_B_Rq "Signal not transmitted on programs that do not have AWD.";
CM_ SG_ 611 AwdLck_Tq_Rq "Signal not transmitted on programs that do not have AWD.";
CM_ BO_ 130 "drecker 10/23/09 Need SAPP in sync w/Strg Torque for proper PAM interpretation, else fault msg's displayed FP@20ms IPC needs EPAS_Failure for msg to driver.  Not map w/Lane Assist FP@30s FP), save bandwidth if feature not on vehicle ";
CM_ SG_ 130 SteMdule_U_Meas "DCR 1745  to update Tx from GWM to EP100ms. SteMdule_I_Est & SteMdule_U_Meas are used by BMS system & filtered. The filter uses standard periodic rate & changing to EP would adversely affect the filter.(jweinfur)";
CM_ SG_ 130 SteMdule_I_Est "DCR 1745  to update Tx from GWM to EP100ms. SteMdule_I_Est & SteMdule_U_Meas are used by BMS system & filtered. The filter uses standard periodic rate & changing to EP would adversely affect the filter.(jweinfur)";
CM_ SG_ 126 StePinRelInit_An_Sns "SASM will transmit these signals on vehicles with SASM and without PSCM.  SCCM will not Tx this signal when SASM is present.";
CM_ SG_ 126 StePinAn_No_Cs "Signal not transmitted on gas variants.";
CM_ SG_ 1200 BrkTot_Tq_RqDrv "DCR 1836 to update Tx from GWM to EP100ms rejected due MPS6 TCM requires BrkTot_Tq_RqDrv at 20ms (bshu1).";
CM_ SG_ 1046 TCMode "Signal data set to 0x0 for ABS only vehicle option content";
CM_ SG_ 1046 DrvAntiLckLamp_D_Rq "update value table v8.34, not align w/GSDB, need etracker.  ABS & IPC implemented as updated.";
CM_ SG_ 1044 StePinOffst_An_Est "SASM will transmit these signals on vehicles with SASM and without PSCM.  SCCM will not Tx this signal when SASM is present.";
CM_ SG_ 1044 StePinOffst_No_Cs "Signal not transmitted on gas variants.";
BA_DEF_ SG_  "U_CDX706_MY2023_Tx" ENUM  "No","Yes";
BA_DEF_ SG_  "U_CDX706_MY2023_Rx" ENUM  "No","Yes";
BA_DEF_ BO_  "AuthFreshnessCounterSyncAttempt" INT 0 2;
BA_DEF_ BO_  "VFrameFormat" ENUM  "StandardCAN","ExtendedCAN","reserved","reserved","reserved","reserved","reserved","reserved","reserved","reserved","reserved","reserved","reserved","reserved","StandardCAN_FD","ExtendedCAN_FD";
BA_DEF_ SG_  "GenSigSendType" ENUM  "Cyclic","OnWrite","vector_leerstring","OnChange","vector_leerstring","IfActive","vector_leerstring","NoSigSendType";
BA_DEF_ SG_  "GenSigInactiveValue" INT 0 100000;
BA_DEF_ SG_  "WakeupSignal" ENUM  "No","Yes";
BA_DEF_ SG_  "UsedOnPgmDBC" ENUM  "No","Yes";
BA_DEF_ SG_  "GenSigStartValueInteger" INT 0 1000000000;
BA_DEF_ SG_  "ContentDependant" ENUM  "No","Yes";
BA_DEF_ SG_  "MetaData" ENUM  "No","Yes";
BA_DEF_ SG_  "GenSigStartValue" HEX 0 268435455;
BA_DEF_ SG_  "U_CX727_MY2021_Rx" ENUM  "No","Yes";
BA_DEF_ SG_  "U_P702_MY2021_Rx" ENUM  "No","Yes";
BA_DEF_ SG_  "U_T6_MCA_MY2020_Rx" ENUM  "No","Yes";
BA_DEF_ SG_  "ECGUsedRxSignal" ENUM  "No","Yes";
BA_DEF_ SG_  "U_CD542_MY2021_Rx" ENUM  "No","Yes";
BA_DEF_ SG_  "U_U55X_MY2022_Rx" ENUM  "No","Yes";
BA_DEF_ SG_  "U_CD764_MY2022_Rx" ENUM  "No","Yes";
BA_DEF_ SG_  "U_CX727_MY2021_Tx" ENUM  "No","Yes";
BA_DEF_ SG_  "U_P702_MY2021_Tx" ENUM  "No","Yes";
BA_DEF_ SG_  "U_T6_MCA_MY2020_Tx" ENUM  "No","Yes";
BA_DEF_ SG_  "ECGUsedTxSignal" ENUM  "No","Yes";
BA_DEF_ SG_  "U_CD542_MY2021_Tx" ENUM  "No","Yes";
BA_DEF_ SG_  "U_U55X_MY2022_Tx" ENUM  "No","Yes";
BA_DEF_ SG_  "U_CD764_MY2022_Tx" ENUM  "No","Yes";
BA_DEF_ BO_  "GenMsgILSupport" ENUM  "No","Yes";
BA_DEF_ BO_  "DiagResponse" ENUM  "No","Yes";
BA_DEF_ BO_  "DiagRequest" ENUM  "No","Yes";
BA_DEF_ BO_  "TpTxIndex" INT 0 536870911;
BA_DEF_ BO_  "DiagState" ENUM  "No","Yes";
BA_DEF_ BO_  "TpApplType" STRING ;
BA_DEF_ BO_  "NmAsrMessage" ENUM  "No","Yes";
BA_DEF_ BO_  "SCP_AuthInfoTxLength" INT 0 512;
BA_DEF_ BO_  "SCP_FreshnessValueTxLength" INT 0 512;
BA_DEF_ BO_  "SCP_FreshnessValueLength" INT 0 512;
BA_DEF_ BO_  "OvtpPushApplication" ENUM  "FALSE","TRUE";
BA_DEF_ BO_  "GenMsgSendType" ENUM  "FixedPeriodic","Event","EnabledPeriodic","NotUsed","NotUsed","EventPeriodic","NotUsed","NotUsed","NoMsgSendType";
BA_DEF_ BO_  "GenMsgCycleTime" INT 0 100000;
BA_DEF_ BO_  "GenMsgDelayTime" INT 0 1000;
BA_DEF_ BO_  "GenMsgNrOfRepetition" INT 0 100;
BA_DEF_ BO_  "GenMsgStartDelayTime" INT 0 10000;
BA_DEF_ BO_  "EventRateOfChange" INT 10 10000;
BA_DEF_ BO_  "FrameGatewayId" HEX 0 1407;
BA_DEF_ BO_  "NetworkInitialization" ENUM  "No","Yes";
BA_DEF_ BO_  "FrameGatewayNetwork" STRING ;
BA_DEF_ BO_  "FrameRouting" STRING ;
BA_DEF_DEF_  "U_CDX706_MY2023_Tx" "No";
BA_DEF_DEF_  "U_CDX706_MY2023_Rx" "No";
BA_DEF_DEF_  "AuthFreshnessCounterSyncAttempt" 2;
BA_DEF_DEF_  "VFrameFormat" "ExtendedCAN_FD";
BA_DEF_DEF_  "GenSigSendType" "NoSigSendType";
BA_DEF_DEF_  "GenSigInactiveValue" 0;
BA_DEF_DEF_  "WakeupSignal" "No";
BA_DEF_DEF_  "UsedOnPgmDBC" "Yes";
BA_DEF_DEF_  "GenSigStartValueInteger" 0;
BA_DEF_DEF_  "ContentDependant" "No";
BA_DEF_DEF_  "MetaData" "No";
BA_DEF_DEF_  "GenSigStartValue" 0;
BA_DEF_DEF_  "U_CX727_MY2021_Rx" "No";
BA_DEF_DEF_  "U_P702_MY2021_Rx" "No";
BA_DEF_DEF_  "U_T6_MCA_MY2020_Rx" "No";
BA_DEF_DEF_  "ECGUsedRxSignal" "No";
BA_DEF_DEF_  "U_CD542_MY2021_Rx" "No";
BA_DEF_DEF_  "U_U55X_MY2022_Rx" "No";
BA_DEF_DEF_  "U_CD764_MY2022_Rx" "No";
BA_DEF_DEF_  "U_CX727_MY2021_Tx" "No";
BA_DEF_DEF_  "U_P702_MY2021_Tx" "No";
BA_DEF_DEF_  "U_T6_MCA_MY2020_Tx" "No";
BA_DEF_DEF_  "ECGUsedTxSignal" "No";
BA_DEF_DEF_  "U_CD542_MY2021_Tx" "No";
BA_DEF_DEF_  "U_U55X_MY2022_Tx" "No";
BA_DEF_DEF_  "U_CD764_MY2022_Tx" "No";
BA_DEF_DEF_  "GenMsgILSupport" "Yes";
BA_DEF_DEF_  "DiagResponse" "No";
BA_DEF_DEF_  "DiagRequest" "No";
BA_DEF_DEF_  "TpTxIndex" 0;
BA_DEF_DEF_  "DiagState" "No";
BA_DEF_DEF_  "TpApplType" "";
BA_DEF_DEF_  "NmAsrMessage" "No";
BA_DEF_DEF_  "SCP_AuthInfoTxLength" 53;
BA_DEF_DEF_  "SCP_FreshnessValueTxLength" 11;
BA_DEF_DEF_  "SCP_FreshnessValueLength" 64;
BA_DEF_DEF_  "OvtpPushApplication" "FALSE";
BA_DEF_DEF_  "GenMsgSendType" "NoMsgSendType";
BA_DEF_DEF_  "GenMsgCycleTime" 0;
BA_DEF_DEF_  "GenMsgDelayTime" 20;
BA_DEF_DEF_  "GenMsgNrOfRepetition" 1;
BA_DEF_DEF_  "GenMsgStartDelayTime" 0;
BA_DEF_DEF_  "EventRateOfChange" 10000;
BA_DEF_DEF_  "FrameGatewayId" 0;
BA_DEF_DEF_  "NetworkInitialization" "Yes";
BA_DEF_DEF_  "FrameGatewayNetwork" "NONE";
BA_DEF_DEF_  "FrameRouting" "";
BA_ "GenMsgSendType" BO_ 985 5;
BA_ "GenMsgCycleTime" BO_ 985 60;
BA_ "VFrameFormat" BO_ 985 14;
BA_ "GenMsgSendType" BO_ 984 5;
BA_ "GenMsgCycleTime" BO_ 984 1000;
BA_ "VFrameFormat" BO_ 984 14;
BA_ "GenMsgSendType" BO_ 983 0;
BA_ "GenMsgCycleTime" BO_ 983 50;
BA_ "VFrameFormat" BO_ 983 14;
BA_ "GenMsgSendType" BO_ 976 0;
BA_ "GenMsgCycleTime" BO_ 976 20;
BA_ "GenMsgDelayTime" BO_ 976 10;
BA_ "VFrameFormat" BO_ 976 14;
BA_ "GenMsgSendType" BO_ 973 5;
BA_ "GenMsgCycleTime" BO_ 973 1000;
BA_ "VFrameFormat" BO_ 973 14;
BA_ "GenMsgSendType" BO_ 970 0;
BA_ "GenMsgCycleTime" BO_ 970 30;
BA_ "GenMsgDelayTime" BO_ 970 10;
BA_ "VFrameFormat" BO_ 970 14;
BA_ "GenMsgSendType" BO_ 394 5;
BA_ "GenMsgCycleTime" BO_ 394 200;
BA_ "VFrameFormat" BO_ 394 14;
BA_ "GenMsgSendType" BO_ 391 0;
BA_ "GenMsgCycleTime" BO_ 391 20;
BA_ "GenMsgDelayTime" BO_ 391 10;
BA_ "VFrameFormat" BO_ 391 14;
BA_ "GenMsgSendType" BO_ 390 0;
BA_ "GenMsgCycleTime" BO_ 390 20;
BA_ "GenMsgDelayTime" BO_ 390 10;
BA_ "VFrameFormat" BO_ 390 14;
BA_ "GenMsgSendType" BO_ 611 0;
BA_ "GenMsgCycleTime" BO_ 611 100;
BA_ "VFrameFormat" BO_ 611 14;
BA_ "GenMsgILSupport" BO_ 1461 0;
BA_ "NmAsrMessage" BO_ 1461 1;
BA_ "GenMsgSendType" BO_ 1461 0;
BA_ "GenMsgCycleTime" BO_ 1461 1000;
BA_ "NetworkInitialization" BO_ 1461 0;
BA_ "VFrameFormat" BO_ 1461 14;
BA_ "GenMsgSendType" BO_ 1047 5;
BA_ "GenMsgCycleTime" BO_ 1047 1000;
BA_ "VFrameFormat" BO_ 1047 14;
BA_ "GenMsgSendType" BO_ 972 0;
BA_ "GenMsgCycleTime" BO_ 972 30;
BA_ "GenMsgDelayTime" BO_ 972 10;
BA_ "VFrameFormat" BO_ 972 14;
BA_ "GenMsgSendType" BO_ 130 0;
BA_ "GenMsgCycleTime" BO_ 130 20;
BA_ "GenMsgDelayTime" BO_ 130 10;
BA_ "VFrameFormat" BO_ 130 14;
BA_ "GenMsgSendType" BO_ 126 0;
BA_ "GenMsgCycleTime" BO_ 126 10;
BA_ "GenMsgDelayTime" BO_ 126 0;
BA_ "VFrameFormat" BO_ 126 14;
BA_ "GenMsgILSupport" BO_ 1430 0;
BA_ "NmAsrMessage" BO_ 1430 1;
BA_ "GenMsgSendType" BO_ 1430 0;
BA_ "GenMsgCycleTime" BO_ 1430 1000;
BA_ "NetworkInitialization" BO_ 1430 0;
BA_ "VFrameFormat" BO_ 1430 14;
BA_ "GenMsgSendType" BO_ 1200 0;
BA_ "GenMsgCycleTime" BO_ 1200 20;
BA_ "GenMsgDelayTime" BO_ 1200 10;
BA_ "VFrameFormat" BO_ 1200 14;
BA_ "GenMsgSendType" BO_ 1102 5;
BA_ "GenMsgCycleTime" BO_ 1102 100000;
BA_ "GenMsgStartDelayTime" BO_ 1102 1130;
BA_ "VFrameFormat" BO_ 1102 14;
BA_ "GenMsgSendType" BO_ 1056 5;
BA_ "GenMsgCycleTime" BO_ 1056 1000;
BA_ "VFrameFormat" BO_ 1056 14;
BA_ "GenMsgSendType" BO_ 1054 5;
BA_ "GenMsgCycleTime" BO_ 1054 1000;
BA_ "VFrameFormat" BO_ 1054 14;
BA_ "GenMsgSendType" BO_ 1046 0;
BA_ "GenMsgCycleTime" BO_ 1046 100;
BA_ "VFrameFormat" BO_ 1046 14;
BA_ "GenMsgSendType" BO_ 1045 0;
BA_ "GenMsgCycleTime" BO_ 1045 20;
BA_ "GenMsgDelayTime" BO_ 1045 10;
BA_ "VFrameFormat" BO_ 1045 14;
BA_ "GenMsgSendType" BO_ 1044 0;
BA_ "GenMsgCycleTime" BO_ 1044 100;
BA_ "VFrameFormat" BO_ 1044 14;
BA_ "GenMsgSendType" BO_ 1042 0;
BA_ "GenMsgCycleTime" BO_ 1042 50;
BA_ "VFrameFormat" BO_ 1042 14;
BA_ "GenSigSendType" SG_ 985 LongCtrlBrk_D_Rq 3;
BA_ "U_CD764_MY2022_Tx" SG_ 985 LongCtrlBrk_D_Rq 1;
BA_ "ContentDependant" SG_ 985 LongCtrlEnblDRq_No_Cs 1;
BA_ "MetaData" SG_ 985 LongCtrlEnblDRq_No_Cs 1;
BA_ "U_U55X_MY2022_Tx" SG_ 985 LongCtrlEnblDRq_No_Cs 1;
BA_ "U_CD764_MY2022_Tx" SG_ 985 LongCtrlEnblDRq_No_Cs 1;
BA_ "ContentDependant" SG_ 985 LongCtrlEnblDRq_No_Cnt 1;
BA_ "MetaData" SG_ 985 LongCtrlEnblDRq_No_Cnt 1;
BA_ "U_U55X_MY2022_Tx" SG_ 985 LongCtrlEnblDRq_No_Cnt 1;
BA_ "U_CD764_MY2022_Tx" SG_ 985 LongCtrlEnblDRq_No_Cnt 1;
BA_ "GenSigSendType" SG_ 985 AdbDrvSide_B_Stat 3;
BA_ "U_U55X_MY2022_Rx" SG_ 985 AdbDrvSide_B_Stat 1;
BA_ "U_CD764_MY2022_Rx" SG_ 985 AdbDrvSide_B_Stat 1;
BA_ "U_T6_MCA_MY2020_Tx" SG_ 985 AdbDrvSide_B_Stat 1;
BA_ "U_CD542_MY2021_Tx" SG_ 985 AdbDrvSide_B_Stat 1;
BA_ "U_U55X_MY2022_Tx" SG_ 985 AdbDrvSide_B_Stat 1;
BA_ "U_CD764_MY2022_Tx" SG_ 985 AdbDrvSide_B_Stat 1;
BA_ "GenSigSendType" SG_ 985 LcwaMsgTxt_D_Stat 3;
BA_ "U_T6_MCA_MY2020_Tx" SG_ 985 LcwaMsgTxt_D_Stat 1;
BA_ "U_CD542_MY2021_Tx" SG_ 985 LcwaMsgTxt_D_Stat 1;
BA_ "U_U55X_MY2022_Tx" SG_ 985 LcwaMsgTxt_D_Stat 1;
BA_ "U_CD764_MY2022_Tx" SG_ 985 LcwaMsgTxt_D_Stat 1;
BA_ "GenSigSendType" SG_ 985 AdbDividedRoad_B_Stat 3;
BA_ "U_CX727_MY2021_Rx" SG_ 985 AdbDividedRoad_B_Stat 1;
BA_ "U_P702_MY2021_Rx" SG_ 985 AdbDividedRoad_B_Stat 1;
BA_ "U_U55X_MY2022_Rx" SG_ 985 AdbDividedRoad_B_Stat 1;
BA_ "U_CD764_MY2022_Rx" SG_ 985 AdbDividedRoad_B_Stat 1;
BA_ "U_T6_MCA_MY2020_Tx" SG_ 985 AdbDividedRoad_B_Stat 1;
BA_ "U_CD542_MY2021_Tx" SG_ 985 AdbDividedRoad_B_Stat 1;
BA_ "U_U55X_MY2022_Tx" SG_ 985 AdbDividedRoad_B_Stat 1;
BA_ "U_CD764_MY2022_Tx" SG_ 985 AdbDividedRoad_B_Stat 1;
BA_ "GenSigSendType" SG_ 985 IsaVLimUnit_D_Rq 3;
BA_ "U_P702_MY2021_Rx" SG_ 985 IsaVLimUnit_D_Rq 1;
BA_ "U_T6_MCA_MY2020_Rx" SG_ 985 IsaVLimUnit_D_Rq 1;
BA_ "U_CD542_MY2021_Rx" SG_ 985 IsaVLimUnit_D_Rq 1;
BA_ "U_CD764_MY2022_Rx" SG_ 985 IsaVLimUnit_D_Rq 1;
BA_ "U_T6_MCA_MY2020_Tx" SG_ 985 IsaVLimUnit_D_Rq 1;
BA_ "U_CD542_MY2021_Tx" SG_ 985 IsaVLimUnit_D_Rq 1;
BA_ "U_U55X_MY2022_Tx" SG_ 985 IsaVLimUnit_D_Rq 1;
BA_ "U_CD764_MY2022_Tx" SG_ 985 IsaVLimUnit_D_Rq 1;
BA_ "GenSigSendType" SG_ 985 SblmYieldScnr_B_Stat 3;
BA_ "U_CX727_MY2021_Rx" SG_ 985 SblmYieldScnr_B_Stat 1;
BA_ "U_P702_MY2021_Rx" SG_ 985 SblmYieldScnr_B_Stat 1;
BA_ "U_U55X_MY2022_Rx" SG_ 985 SblmYieldScnr_B_Stat 1;
BA_ "U_CD764_MY2022_Rx" SG_ 985 SblmYieldScnr_B_Stat 1;
BA_ "U_T6_MCA_MY2020_Tx" SG_ 985 SblmYieldScnr_B_Stat 1;
BA_ "U_CD542_MY2021_Tx" SG_ 985 SblmYieldScnr_B_Stat 1;
BA_ "U_U55X_MY2022_Tx" SG_ 985 SblmYieldScnr_B_Stat 1;
BA_ "U_CD764_MY2022_Tx" SG_ 985 SblmYieldScnr_B_Stat 1;
BA_ "GenSigSendType" SG_ 985 SblmStopScnr_B_Stat 3;
BA_ "U_CX727_MY2021_Rx" SG_ 985 SblmStopScnr_B_Stat 1;
BA_ "U_P702_MY2021_Rx" SG_ 985 SblmStopScnr_B_Stat 1;
BA_ "U_U55X_MY2022_Rx" SG_ 985 SblmStopScnr_B_Stat 1;
BA_ "U_CD764_MY2022_Rx" SG_ 985 SblmStopScnr_B_Stat 1;
BA_ "U_T6_MCA_MY2020_Tx" SG_ 985 SblmStopScnr_B_Stat 1;
BA_ "U_CD542_MY2021_Tx" SG_ 985 SblmStopScnr_B_Stat 1;
BA_ "U_U55X_MY2022_Tx" SG_ 985 SblmStopScnr_B_Stat 1;
BA_ "U_CD764_MY2022_Tx" SG_ 985 SblmStopScnr_B_Stat 1;
BA_ "GenSigSendType" SG_ 985 IsaVLim_D_Rq 3;
BA_ "GenSigStartValueInteger" SG_ 985 IsaVLim_D_Rq 254;
BA_ "GenSigStartValue" SG_ 985 IsaVLim_D_Rq 254;
BA_ "U_P702_MY2021_Rx" SG_ 985 IsaVLim_D_Rq 1;
BA_ "U_T6_MCA_MY2020_Rx" SG_ 985 IsaVLim_D_Rq 1;
BA_ "U_CD542_MY2021_Rx" SG_ 985 IsaVLim_D_Rq 1;
BA_ "U_CD764_MY2022_Rx" SG_ 985 IsaVLim_D_Rq 1;
BA_ "U_T6_MCA_MY2020_Tx" SG_ 985 IsaVLim_D_Rq 1;
BA_ "U_CD542_MY2021_Tx" SG_ 985 IsaVLim_D_Rq 1;
BA_ "U_U55X_MY2022_Tx" SG_ 985 IsaVLim_D_Rq 1;
BA_ "U_CD764_MY2022_Tx" SG_ 985 IsaVLim_D_Rq 1;
BA_ "GenSigSendType" SG_ 985 IaccVLimUnit_D_Rq 3;
BA_ "GenSigStartValueInteger" SG_ 985 IaccVLimUnit_D_Rq 3;
BA_ "GenSigStartValue" SG_ 985 IaccVLimUnit_D_Rq 3;
BA_ "U_P702_MY2021_Rx" SG_ 985 IaccVLimUnit_D_Rq 1;
BA_ "U_T6_MCA_MY2020_Rx" SG_ 985 IaccVLimUnit_D_Rq 1;
BA_ "U_CD542_MY2021_Rx" SG_ 985 IaccVLimUnit_D_Rq 1;
BA_ "U_CD764_MY2022_Rx" SG_ 985 IaccVLimUnit_D_Rq 1;
BA_ "U_T6_MCA_MY2020_Tx" SG_ 985 IaccVLimUnit_D_Rq 1;
BA_ "U_CD542_MY2021_Tx" SG_ 985 IaccVLimUnit_D_Rq 1;
BA_ "U_U55X_MY2022_Tx" SG_ 985 IaccVLimUnit_D_Rq 1;
BA_ "U_CD764_MY2022_Tx" SG_ 985 IaccVLimUnit_D_Rq 1;
BA_ "GenSigSendType" SG_ 985 IaccVLim_D_Rq 3;
BA_ "GenSigStartValueInteger" SG_ 985 IaccVLim_D_Rq 254;
BA_ "GenSigStartValue" SG_ 985 IaccVLim_D_Rq 254;
BA_ "U_P702_MY2021_Rx" SG_ 985 IaccVLim_D_Rq 1;
BA_ "U_T6_MCA_MY2020_Rx" SG_ 985 IaccVLim_D_Rq 1;
BA_ "U_CD542_MY2021_Rx" SG_ 985 IaccVLim_D_Rq 1;
BA_ "U_CD764_MY2022_Rx" SG_ 985 IaccVLim_D_Rq 1;
BA_ "U_T6_MCA_MY2020_Tx" SG_ 985 IaccVLim_D_Rq 1;
BA_ "U_CD542_MY2021_Tx" SG_ 985 IaccVLim_D_Rq 1;
BA_ "U_U55X_MY2022_Tx" SG_ 985 IaccVLim_D_Rq 1;
BA_ "U_CD764_MY2022_Tx" SG_ 985 IaccVLim_D_Rq 1;
BA_ "GenSigSendType" SG_ 985 DasAlrtInfo_D_Dsply 3;
BA_ "U_T6_MCA_MY2020_Tx" SG_ 985 DasAlrtInfo_D_Dsply 1;
BA_ "U_CD542_MY2021_Tx" SG_ 985 DasAlrtInfo_D_Dsply 1;
BA_ "U_U55X_MY2022_Tx" SG_ 985 DasAlrtInfo_D_Dsply 1;
BA_ "U_CD764_MY2022_Tx" SG_ 985 DasAlrtInfo_D_Dsply 1;
BA_ "GenSigSendType" SG_ 985 SblmRndAbtScnr_B_Stat 3;
BA_ "U_CX727_MY2021_Rx" SG_ 985 SblmRndAbtScnr_B_Stat 1;
BA_ "U_P702_MY2021_Rx" SG_ 985 SblmRndAbtScnr_B_Stat 1;
BA_ "U_U55X_MY2022_Rx" SG_ 985 SblmRndAbtScnr_B_Stat 1;
BA_ "U_CD764_MY2022_Rx" SG_ 985 SblmRndAbtScnr_B_Stat 1;
BA_ "U_T6_MCA_MY2020_Tx" SG_ 985 SblmRndAbtScnr_B_Stat 1;
BA_ "U_CD542_MY2021_Tx" SG_ 985 SblmRndAbtScnr_B_Stat 1;
BA_ "U_U55X_MY2022_Tx" SG_ 985 SblmRndAbtScnr_B_Stat 1;
BA_ "U_CD764_MY2022_Tx" SG_ 985 SblmRndAbtScnr_B_Stat 1;
BA_ "GenSigSendType" SG_ 985 PwSustnAdas_B_Rq 3;
BA_ "U_U55X_MY2022_Tx" SG_ 985 PwSustnAdas_B_Rq 1;
BA_ "GenSigSendType" SG_ 985 ClrExitAsstMsgTxt_D_Rq 3;
BA_ "U_U55X_MY2022_Tx" SG_ 985 ClrExitAsstMsgTxt_D_Rq 1;
BA_ "U_CD764_MY2022_Tx" SG_ 985 ClrExitAsstMsgTxt_D_Rq 1;
BA_ "GenSigSendType" SG_ 985 ClrExitAsstChime_D_Rq 3;
BA_ "U_U55X_MY2022_Tx" SG_ 985 ClrExitAsstChime_D_Rq 1;
BA_ "U_CD764_MY2022_Tx" SG_ 985 ClrExitAsstChime_D_Rq 1;
BA_ "GenSigSendType" SG_ 985 LongCtrlEnbl_D_Rq 3;
BA_ "U_T6_MCA_MY2020_Rx" SG_ 985 LongCtrlEnbl_D_Rq 1;
BA_ "U_T6_MCA_MY2020_Tx" SG_ 985 LongCtrlEnbl_D_Rq 1;
BA_ "U_CD542_MY2021_Tx" SG_ 985 LongCtrlEnbl_D_Rq 1;
BA_ "U_U55X_MY2022_Tx" SG_ 985 LongCtrlEnbl_D_Rq 1;
BA_ "U_CD764_MY2022_Tx" SG_ 985 LongCtrlEnbl_D_Rq 1;
BA_ "GenSigSendType" SG_ 985 SblmPedCrossScnr_B_Stat 3;
BA_ "U_U55X_MY2022_Rx" SG_ 985 SblmPedCrossScnr_B_Stat 1;
BA_ "U_CD764_MY2022_Rx" SG_ 985 SblmPedCrossScnr_B_Stat 1;
BA_ "U_T6_MCA_MY2020_Tx" SG_ 985 SblmPedCrossScnr_B_Stat 1;
BA_ "U_CD542_MY2021_Tx" SG_ 985 SblmPedCrossScnr_B_Stat 1;
BA_ "U_U55X_MY2022_Tx" SG_ 985 SblmPedCrossScnr_B_Stat 1;
BA_ "U_CD764_MY2022_Tx" SG_ 985 SblmPedCrossScnr_B_Stat 1;
BA_ "GenSigSendType" SG_ 985 TsrRegionTxt_D_Stat 3;
BA_ "U_T6_MCA_MY2020_Tx" SG_ 985 TsrRegionTxt_D_Stat 1;
BA_ "U_CD542_MY2021_Tx" SG_ 985 TsrRegionTxt_D_Stat 1;
BA_ "U_U55X_MY2022_Tx" SG_ 985 TsrRegionTxt_D_Stat 1;
BA_ "U_CD764_MY2022_Tx" SG_ 985 TsrRegionTxt_D_Stat 1;
BA_ "GenSigSendType" SG_ 985 LdwChime_B_Rq 3;
BA_ "U_T6_MCA_MY2020_Tx" SG_ 985 LdwChime_B_Rq 1;
BA_ "U_CD542_MY2021_Tx" SG_ 985 LdwChime_B_Rq 1;
BA_ "U_U55X_MY2022_Tx" SG_ 985 LdwChime_B_Rq 1;
BA_ "U_CD764_MY2022_Tx" SG_ 985 LdwChime_B_Rq 1;
BA_ "GenSigSendType" SG_ 985 ClrExitAsst_D_Stat 3;
BA_ "U_U55X_MY2022_Tx" SG_ 985 ClrExitAsst_D_Stat 1;
BA_ "U_CD764_MY2022_Tx" SG_ 985 ClrExitAsst_D_Stat 1;
BA_ "GenSigSendType" SG_ 984 DasWarn_D_Dsply 3;
BA_ "U_T6_MCA_MY2020_Tx" SG_ 984 DasWarn_D_Dsply 1;
BA_ "U_CD542_MY2021_Tx" SG_ 984 DasWarn_D_Dsply 1;
BA_ "U_U55X_MY2022_Tx" SG_ 984 DasWarn_D_Dsply 1;
BA_ "U_CD764_MY2022_Tx" SG_ 984 DasWarn_D_Dsply 1;
BA_ "GenSigSendType" SG_ 984 DasStats_D_Dsply 3;
BA_ "U_T6_MCA_MY2020_Tx" SG_ 984 DasStats_D_Dsply 1;
BA_ "U_CD542_MY2021_Tx" SG_ 984 DasStats_D_Dsply 1;
BA_ "U_U55X_MY2022_Tx" SG_ 984 DasStats_D_Dsply 1;
BA_ "U_CD764_MY2022_Tx" SG_ 984 DasStats_D_Dsply 1;
BA_ "GenSigSendType" SG_ 984 DasAlrtLvl_D_Dsply 3;
BA_ "U_T6_MCA_MY2020_Tx" SG_ 984 DasAlrtLvl_D_Dsply 1;
BA_ "U_CD542_MY2021_Tx" SG_ 984 DasAlrtLvl_D_Dsply 1;
BA_ "U_U55X_MY2022_Tx" SG_ 984 DasAlrtLvl_D_Dsply 1;
BA_ "U_CD764_MY2022_Tx" SG_ 984 DasAlrtLvl_D_Dsply 1;
BA_ "GenSigSendType" SG_ 984 CamraStats_D_Dsply 3;
BA_ "U_T6_MCA_MY2020_Tx" SG_ 984 CamraStats_D_Dsply 1;
BA_ "U_CD542_MY2021_Tx" SG_ 984 CamraStats_D_Dsply 1;
BA_ "U_U55X_MY2022_Tx" SG_ 984 CamraStats_D_Dsply 1;
BA_ "U_CD764_MY2022_Tx" SG_ 984 CamraStats_D_Dsply 1;
BA_ "GenSigSendType" SG_ 984 CamraDefog_B_Req 3;
BA_ "U_T6_MCA_MY2020_Tx" SG_ 984 CamraDefog_B_Req 1;
BA_ "U_CD542_MY2021_Tx" SG_ 984 CamraDefog_B_Req 1;
BA_ "U_U55X_MY2022_Tx" SG_ 984 CamraDefog_B_Req 1;
BA_ "U_CD764_MY2022_Tx" SG_ 984 CamraDefog_B_Req 1;
BA_ "GenSigSendType" SG_ 984 LaHandsOff_D_Dsply 3;
BA_ "U_T6_MCA_MY2020_Tx" SG_ 984 LaHandsOff_D_Dsply 1;
BA_ "U_CD542_MY2021_Tx" SG_ 984 LaHandsOff_D_Dsply 1;
BA_ "U_U55X_MY2022_Tx" SG_ 984 LaHandsOff_D_Dsply 1;
BA_ "U_CD764_MY2022_Tx" SG_ 984 LaHandsOff_D_Dsply 1;
BA_ "GenSigSendType" SG_ 984 LaDenyStats_B_Dsply 3;
BA_ "U_T6_MCA_MY2020_Tx" SG_ 984 LaDenyStats_B_Dsply 1;
BA_ "U_CD542_MY2021_Tx" SG_ 984 LaDenyStats_B_Dsply 1;
BA_ "U_U55X_MY2022_Tx" SG_ 984 LaDenyStats_B_Dsply 1;
BA_ "U_CD764_MY2022_Tx" SG_ 984 LaDenyStats_B_Dsply 1;
BA_ "GenSigSendType" SG_ 984 AhbcRampingV_D_Rq 3;
BA_ "U_CX727_MY2021_Rx" SG_ 984 AhbcRampingV_D_Rq 1;
BA_ "U_P702_MY2021_Rx" SG_ 984 AhbcRampingV_D_Rq 1;
BA_ "U_U55X_MY2022_Rx" SG_ 984 AhbcRampingV_D_Rq 1;
BA_ "U_CD764_MY2022_Rx" SG_ 984 AhbcRampingV_D_Rq 1;
BA_ "U_T6_MCA_MY2020_Tx" SG_ 984 AhbcRampingV_D_Rq 1;
BA_ "U_CD542_MY2021_Tx" SG_ 984 AhbcRampingV_D_Rq 1;
BA_ "U_U55X_MY2022_Tx" SG_ 984 AhbcRampingV_D_Rq 1;
BA_ "U_CD764_MY2022_Tx" SG_ 984 AhbcRampingV_D_Rq 1;
BA_ "GenSigSendType" SG_ 984 PersIndexIpma_D_Actl 3;
BA_ "GenSigStartValueInteger" SG_ 984 PersIndexIpma_D_Actl 4;
BA_ "GenSigStartValue" SG_ 984 PersIndexIpma_D_Actl 4;
BA_ "U_T6_MCA_MY2020_Tx" SG_ 984 PersIndexIpma_D_Actl 1;
BA_ "U_CD542_MY2021_Tx" SG_ 984 PersIndexIpma_D_Actl 1;
BA_ "U_U55X_MY2022_Tx" SG_ 984 PersIndexIpma_D_Actl 1;
BA_ "U_CD764_MY2022_Tx" SG_ 984 PersIndexIpma_D_Actl 1;
BA_ "GenSigSendType" SG_ 984 FeatNoIpmaActl 3;
BA_ "U_T6_MCA_MY2020_Tx" SG_ 984 FeatNoIpmaActl 1;
BA_ "U_CD542_MY2021_Tx" SG_ 984 FeatNoIpmaActl 1;
BA_ "U_U55X_MY2022_Tx" SG_ 984 FeatNoIpmaActl 1;
BA_ "U_CD764_MY2022_Tx" SG_ 984 FeatNoIpmaActl 1;
BA_ "GenSigSendType" SG_ 984 FeatConfigIpmaActl 3;
BA_ "U_T6_MCA_MY2020_Tx" SG_ 984 FeatConfigIpmaActl 1;
BA_ "U_CD542_MY2021_Tx" SG_ 984 FeatConfigIpmaActl 1;
BA_ "U_U55X_MY2022_Tx" SG_ 984 FeatConfigIpmaActl 1;
BA_ "U_CD764_MY2022_Tx" SG_ 984 FeatConfigIpmaActl 1;
BA_ "GenSigSendType" SG_ 984 AhbFeat_D_Stat 3;
BA_ "GenSigSendType" SG_ 984 DsmcMsgTxt_D_Dsply 3;
BA_ "U_T6_MCA_MY2020_Tx" SG_ 984 DsmcMsgTxt_D_Dsply 1;
BA_ "U_U55X_MY2022_Tx" SG_ 984 DsmcMsgTxt_D_Dsply 1;
BA_ "GenSigSendType" SG_ 984 AhbHiBeam_D_Rq 3;
BA_ "U_T6_MCA_MY2020_Tx" SG_ 984 AhbHiBeam_D_Rq 1;
BA_ "U_U55X_MY2022_Tx" SG_ 984 AhbHiBeam_D_Rq 1;
BA_ "U_CD764_MY2022_Tx" SG_ 984 AhbHiBeam_D_Rq 1;
BA_ "GenSigSendType" SG_ 984 LaActvStats_D2_Dsply 3;
BA_ "GenSigStartValueInteger" SG_ 983 CmbbObjRelLong_V_Actl 1022;
BA_ "U_CX727_MY2021_Rx" SG_ 983 CmbbObjRelLong_V_Actl 1;
BA_ "U_P702_MY2021_Rx" SG_ 983 CmbbObjRelLong_V_Actl 1;
BA_ "U_T6_MCA_MY2020_Rx" SG_ 983 CmbbObjRelLong_V_Actl 1;
BA_ "U_CD542_MY2021_Rx" SG_ 983 CmbbObjRelLong_V_Actl 1;
BA_ "U_U55X_MY2022_Rx" SG_ 983 CmbbObjRelLong_V_Actl 1;
BA_ "U_CD764_MY2022_Rx" SG_ 983 CmbbObjRelLong_V_Actl 1;
BA_ "U_T6_MCA_MY2020_Tx" SG_ 983 CmbbObjRelLong_V_Actl 1;
BA_ "U_CD542_MY2021_Tx" SG_ 983 CmbbObjRelLong_V_Actl 1;
BA_ "U_U55X_MY2022_Tx" SG_ 983 CmbbObjRelLong_V_Actl 1;
BA_ "U_CD764_MY2022_Tx" SG_ 983 CmbbObjRelLong_V_Actl 1;
BA_ "GenSigStartValueInteger" SG_ 983 CmbbObjRelLat_V_Actl 510;
BA_ "GenSigStartValue" SG_ 983 CmbbObjRelLat_V_Actl 510;
BA_ "U_CX727_MY2021_Rx" SG_ 983 CmbbObjRelLat_V_Actl 1;
BA_ "U_P702_MY2021_Rx" SG_ 983 CmbbObjRelLat_V_Actl 1;
BA_ "U_T6_MCA_MY2020_Rx" SG_ 983 CmbbObjRelLat_V_Actl 1;
BA_ "U_CD542_MY2021_Rx" SG_ 983 CmbbObjRelLat_V_Actl 1;
BA_ "U_U55X_MY2022_Rx" SG_ 983 CmbbObjRelLat_V_Actl 1;
BA_ "U_CD764_MY2022_Rx" SG_ 983 CmbbObjRelLat_V_Actl 1;
BA_ "U_T6_MCA_MY2020_Tx" SG_ 983 CmbbObjRelLat_V_Actl 1;
BA_ "U_CD542_MY2021_Tx" SG_ 983 CmbbObjRelLat_V_Actl 1;
BA_ "U_U55X_MY2022_Tx" SG_ 983 CmbbObjRelLat_V_Actl 1;
BA_ "U_CD764_MY2022_Tx" SG_ 983 CmbbObjRelLat_V_Actl 1;
BA_ "GenSigStartValueInteger" SG_ 983 CmbbObjDistLong_L_Actl 1022;
BA_ "GenSigStartValue" SG_ 983 CmbbObjDistLong_L_Actl 1022;
BA_ "U_CX727_MY2021_Rx" SG_ 983 CmbbObjDistLong_L_Actl 1;
BA_ "U_P702_MY2021_Rx" SG_ 983 CmbbObjDistLong_L_Actl 1;
BA_ "U_T6_MCA_MY2020_Rx" SG_ 983 CmbbObjDistLong_L_Actl 1;
BA_ "U_CD542_MY2021_Rx" SG_ 983 CmbbObjDistLong_L_Actl 1;
BA_ "U_U55X_MY2022_Rx" SG_ 983 CmbbObjDistLong_L_Actl 1;
BA_ "U_CD764_MY2022_Rx" SG_ 983 CmbbObjDistLong_L_Actl 1;
BA_ "U_T6_MCA_MY2020_Tx" SG_ 983 CmbbObjDistLong_L_Actl 1;
BA_ "U_CD542_MY2021_Tx" SG_ 983 CmbbObjDistLong_L_Actl 1;
BA_ "U_U55X_MY2022_Tx" SG_ 983 CmbbObjDistLong_L_Actl 1;
BA_ "U_CD764_MY2022_Tx" SG_ 983 CmbbObjDistLong_L_Actl 1;
BA_ "GenSigStartValueInteger" SG_ 983 CmbbObjDistLat_L_Actl 510;
BA_ "GenSigStartValue" SG_ 983 CmbbObjDistLat_L_Actl 510;
BA_ "U_CX727_MY2021_Rx" SG_ 983 CmbbObjDistLat_L_Actl 1;
BA_ "U_P702_MY2021_Rx" SG_ 983 CmbbObjDistLat_L_Actl 1;
BA_ "U_T6_MCA_MY2020_Rx" SG_ 983 CmbbObjDistLat_L_Actl 1;
BA_ "U_CD542_MY2021_Rx" SG_ 983 CmbbObjDistLat_L_Actl 1;
BA_ "U_U55X_MY2022_Rx" SG_ 983 CmbbObjDistLat_L_Actl 1;
BA_ "U_CD764_MY2022_Rx" SG_ 983 CmbbObjDistLat_L_Actl 1;
BA_ "U_T6_MCA_MY2020_Tx" SG_ 983 CmbbObjDistLat_L_Actl 1;
BA_ "U_CD542_MY2021_Tx" SG_ 983 CmbbObjDistLat_L_Actl 1;
BA_ "U_U55X_MY2022_Tx" SG_ 983 CmbbObjDistLat_L_Actl 1;
BA_ "U_CD764_MY2022_Tx" SG_ 983 CmbbObjDistLat_L_Actl 1;
BA_ "U_CX727_MY2021_Rx" SG_ 983 CmbbObjConfdnc_D_Stat 1;
BA_ "U_P702_MY2021_Rx" SG_ 983 CmbbObjConfdnc_D_Stat 1;
BA_ "U_T6_MCA_MY2020_Rx" SG_ 983 CmbbObjConfdnc_D_Stat 1;
BA_ "U_CD542_MY2021_Rx" SG_ 983 CmbbObjConfdnc_D_Stat 1;
BA_ "U_U55X_MY2022_Rx" SG_ 983 CmbbObjConfdnc_D_Stat 1;
BA_ "U_CD764_MY2022_Rx" SG_ 983 CmbbObjConfdnc_D_Stat 1;
BA_ "U_T6_MCA_MY2020_Tx" SG_ 983 CmbbObjConfdnc_D_Stat 1;
BA_ "U_CD542_MY2021_Tx" SG_ 983 CmbbObjConfdnc_D_Stat 1;
BA_ "U_U55X_MY2022_Tx" SG_ 983 CmbbObjConfdnc_D_Stat 1;
BA_ "U_CD764_MY2022_Tx" SG_ 983 CmbbObjConfdnc_D_Stat 1;
BA_ "GenSigStartValueInteger" SG_ 983 CmbbObjColl_T_Actl 126;
BA_ "GenSigStartValue" SG_ 983 CmbbObjColl_T_Actl 125;
BA_ "U_CX727_MY2021_Rx" SG_ 983 CmbbObjColl_T_Actl 1;
BA_ "U_P702_MY2021_Rx" SG_ 983 CmbbObjColl_T_Actl 1;
BA_ "U_T6_MCA_MY2020_Rx" SG_ 983 CmbbObjColl_T_Actl 1;
BA_ "U_CD542_MY2021_Rx" SG_ 983 CmbbObjColl_T_Actl 1;
BA_ "U_U55X_MY2022_Rx" SG_ 983 CmbbObjColl_T_Actl 1;
BA_ "U_CD764_MY2022_Rx" SG_ 983 CmbbObjColl_T_Actl 1;
BA_ "U_T6_MCA_MY2020_Tx" SG_ 983 CmbbObjColl_T_Actl 1;
BA_ "U_CD542_MY2021_Tx" SG_ 983 CmbbObjColl_T_Actl 1;
BA_ "U_U55X_MY2022_Tx" SG_ 983 CmbbObjColl_T_Actl 1;
BA_ "U_CD764_MY2022_Tx" SG_ 983 CmbbObjColl_T_Actl 1;
BA_ "U_CX727_MY2021_Rx" SG_ 983 CmbbObjClass_D_Stat 1;
BA_ "U_P702_MY2021_Rx" SG_ 983 CmbbObjClass_D_Stat 1;
BA_ "U_T6_MCA_MY2020_Rx" SG_ 983 CmbbObjClass_D_Stat 1;
BA_ "U_CD542_MY2021_Rx" SG_ 983 CmbbObjClass_D_Stat 1;
BA_ "U_U55X_MY2022_Rx" SG_ 983 CmbbObjClass_D_Stat 1;
BA_ "U_CD764_MY2022_Rx" SG_ 983 CmbbObjClass_D_Stat 1;
BA_ "U_T6_MCA_MY2020_Tx" SG_ 983 CmbbObjClass_D_Stat 1;
BA_ "U_CD542_MY2021_Tx" SG_ 983 CmbbObjClass_D_Stat 1;
BA_ "U_U55X_MY2022_Tx" SG_ 983 CmbbObjClass_D_Stat 1;
BA_ "U_CD764_MY2022_Tx" SG_ 983 CmbbObjClass_D_Stat 1;
BA_ "U_CX727_MY2021_Rx" SG_ 983 EsaEnbl_D2_Rq 1;
BA_ "U_P702_MY2021_Rx" SG_ 983 EsaEnbl_D2_Rq 1;
BA_ "U_T6_MCA_MY2020_Rx" SG_ 983 EsaEnbl_D2_Rq 1;
BA_ "U_CD542_MY2021_Rx" SG_ 983 EsaEnbl_D2_Rq 1;
BA_ "U_U55X_MY2022_Rx" SG_ 983 EsaEnbl_D2_Rq 1;
BA_ "U_CD764_MY2022_Rx" SG_ 983 EsaEnbl_D2_Rq 1;
BA_ "U_T6_MCA_MY2020_Tx" SG_ 983 EsaEnbl_D2_Rq 1;
BA_ "U_CD542_MY2021_Tx" SG_ 983 EsaEnbl_D2_Rq 1;
BA_ "U_U55X_MY2022_Tx" SG_ 983 EsaEnbl_D2_Rq 1;
BA_ "U_CD764_MY2022_Tx" SG_ 983 EsaEnbl_D2_Rq 1;
BA_ "U_U55X_MY2022_Rx" SG_ 976 SuspClkSync_No_Actl 1;
BA_ "U_T6_MCA_MY2020_Tx" SG_ 976 SuspClkSync_No_Actl 1;
BA_ "U_CD542_MY2021_Tx" SG_ 976 SuspClkSync_No_Actl 1;
BA_ "U_U55X_MY2022_Tx" SG_ 976 SuspClkSync_No_Actl 1;
BA_ "U_CD764_MY2022_Tx" SG_ 976 SuspClkSync_No_Actl 1;
BA_ "U_U55X_MY2022_Rx" SG_ 976 SrpSigValid_B_Stat 1;
BA_ "U_T6_MCA_MY2020_Tx" SG_ 976 SrpSigValid_B_Stat 1;
BA_ "U_CD542_MY2021_Tx" SG_ 976 SrpSigValid_B_Stat 1;
BA_ "U_U55X_MY2022_Tx" SG_ 976 SrpSigValid_B_Stat 1;
BA_ "U_CD764_MY2022_Tx" SG_ 976 SrpSigValid_B_Stat 1;
BA_ "GenSigStartValueInteger" SG_ 976 SrpHghtRight_L_Actl 256;
BA_ "U_U55X_MY2022_Rx" SG_ 976 SrpHghtRight_L_Actl 1;
BA_ "U_T6_MCA_MY2020_Tx" SG_ 976 SrpHghtRight_L_Actl 1;
BA_ "U_CD542_MY2021_Tx" SG_ 976 SrpHghtRight_L_Actl 1;
BA_ "U_U55X_MY2022_Tx" SG_ 976 SrpHghtRight_L_Actl 1;
BA_ "U_CD764_MY2022_Tx" SG_ 976 SrpHghtRight_L_Actl 1;
BA_ "GenSigStartValueInteger" SG_ 976 SrpHghtLeft_L_Actl 256;
BA_ "U_U55X_MY2022_Rx" SG_ 976 SrpHghtLeft_L_Actl 1;
BA_ "U_T6_MCA_MY2020_Tx" SG_ 976 SrpHghtLeft_L_Actl 1;
BA_ "U_CD542_MY2021_Tx" SG_ 976 SrpHghtLeft_L_Actl 1;
BA_ "U_U55X_MY2022_Tx" SG_ 976 SrpHghtLeft_L_Actl 1;
BA_ "U_CD764_MY2022_Tx" SG_ 976 SrpHghtLeft_L_Actl 1;
BA_ "U_U55X_MY2022_Rx" SG_ 976 SrpEventRight_D_Stat 1;
BA_ "U_T6_MCA_MY2020_Tx" SG_ 976 SrpEventRight_D_Stat 1;
BA_ "U_CD542_MY2021_Tx" SG_ 976 SrpEventRight_D_Stat 1;
BA_ "U_U55X_MY2022_Tx" SG_ 976 SrpEventRight_D_Stat 1;
BA_ "U_CD764_MY2022_Tx" SG_ 976 SrpEventRight_D_Stat 1;
BA_ "U_U55X_MY2022_Rx" SG_ 976 SrpEventLeft_D_Stat 1;
BA_ "U_T6_MCA_MY2020_Tx" SG_ 976 SrpEventLeft_D_Stat 1;
BA_ "U_CD542_MY2021_Tx" SG_ 976 SrpEventLeft_D_Stat 1;
BA_ "U_U55X_MY2022_Tx" SG_ 976 SrpEventLeft_D_Stat 1;
BA_ "U_CD764_MY2022_Tx" SG_ 976 SrpEventLeft_D_Stat 1;
BA_ "U_U55X_MY2022_Rx" SG_ 976 SrpDistRight_L_Actl 1;
BA_ "U_T6_MCA_MY2020_Tx" SG_ 976 SrpDistRight_L_Actl 1;
BA_ "U_CD542_MY2021_Tx" SG_ 976 SrpDistRight_L_Actl 1;
BA_ "U_U55X_MY2022_Tx" SG_ 976 SrpDistRight_L_Actl 1;
BA_ "U_CD764_MY2022_Tx" SG_ 976 SrpDistRight_L_Actl 1;
BA_ "U_U55X_MY2022_Rx" SG_ 976 SrpDistLeft_L_Actl 1;
BA_ "U_T6_MCA_MY2020_Tx" SG_ 976 SrpDistLeft_L_Actl 1;
BA_ "U_CD542_MY2021_Tx" SG_ 976 SrpDistLeft_L_Actl 1;
BA_ "U_U55X_MY2022_Tx" SG_ 976 SrpDistLeft_L_Actl 1;
BA_ "U_CD764_MY2022_Tx" SG_ 976 SrpDistLeft_L_Actl 1;
BA_ "GenSigSendType" SG_ 973 PersCtaSplitView_D_Stat 3;
BA_ "GenSigSendType" SG_ 973 TsrVl2PrmntMsgTxt_D_Rq 3;
BA_ "U_T6_MCA_MY2020_Tx" SG_ 973 TsrVl2PrmntMsgTxt_D_Rq 1;
BA_ "U_CD542_MY2021_Tx" SG_ 973 TsrVl2PrmntMsgTxt_D_Rq 1;
BA_ "U_U55X_MY2022_Tx" SG_ 973 TsrVl2PrmntMsgTxt_D_Rq 1;
BA_ "U_CD764_MY2022_Tx" SG_ 973 TsrVl2PrmntMsgTxt_D_Rq 1;
BA_ "GenSigSendType" SG_ 973 TsrVl1PrmntMsgTxt_D_Rq 3;
BA_ "U_T6_MCA_MY2020_Tx" SG_ 973 TsrVl1PrmntMsgTxt_D_Rq 1;
BA_ "U_CD542_MY2021_Tx" SG_ 973 TsrVl1PrmntMsgTxt_D_Rq 1;
BA_ "U_U55X_MY2022_Tx" SG_ 973 TsrVl1PrmntMsgTxt_D_Rq 1;
BA_ "U_CD764_MY2022_Tx" SG_ 973 TsrVl1PrmntMsgTxt_D_Rq 1;
BA_ "GenSigSendType" SG_ 973 TsrVl2RstrcMsgTxt2_D_Rq 3;
BA_ "GenSigStartValueInteger" SG_ 973 TsrVl2RstrcMsgTxt2_D_Rq 1;
BA_ "GenSigStartValue" SG_ 973 TsrVl2RstrcMsgTxt2_D_Rq 1;
BA_ "U_T6_MCA_MY2020_Tx" SG_ 973 TsrVl2RstrcMsgTxt2_D_Rq 1;
BA_ "U_CD542_MY2021_Tx" SG_ 973 TsrVl2RstrcMsgTxt2_D_Rq 1;
BA_ "U_U55X_MY2022_Tx" SG_ 973 TsrVl2RstrcMsgTxt2_D_Rq 1;
BA_ "U_CD764_MY2022_Tx" SG_ 973 TsrVl2RstrcMsgTxt2_D_Rq 1;
BA_ "GenSigSendType" SG_ 973 TsrVl1RstrcMsgTxt2_D_Rq 3;
BA_ "GenSigStartValueInteger" SG_ 973 TsrVl1RstrcMsgTxt2_D_Rq 1;
BA_ "GenSigStartValue" SG_ 973 TsrVl1RstrcMsgTxt2_D_Rq 1;
BA_ "U_T6_MCA_MY2020_Tx" SG_ 973 TsrVl1RstrcMsgTxt2_D_Rq 1;
BA_ "U_CD542_MY2021_Tx" SG_ 973 TsrVl1RstrcMsgTxt2_D_Rq 1;
BA_ "U_U55X_MY2022_Tx" SG_ 973 TsrVl1RstrcMsgTxt2_D_Rq 1;
BA_ "U_CD764_MY2022_Tx" SG_ 973 TsrVl1RstrcMsgTxt2_D_Rq 1;
BA_ "GenSigSendType" SG_ 973 TsrOvtkMsgTxt2_D_Rq 3;
BA_ "U_T6_MCA_MY2020_Tx" SG_ 973 TsrOvtkMsgTxt2_D_Rq 1;
BA_ "U_CD542_MY2021_Tx" SG_ 973 TsrOvtkMsgTxt2_D_Rq 1;
BA_ "U_U55X_MY2022_Tx" SG_ 973 TsrOvtkMsgTxt2_D_Rq 1;
BA_ "U_CD764_MY2022_Tx" SG_ 973 TsrOvtkMsgTxt2_D_Rq 1;
BA_ "GenSigSendType" SG_ 973 WwaWarn_B_Rq 3;
BA_ "U_T6_MCA_MY2020_Tx" SG_ 973 WwaWarn_B_Rq 1;
BA_ "U_CD542_MY2021_Tx" SG_ 973 WwaWarn_B_Rq 1;
BA_ "U_U55X_MY2022_Tx" SG_ 973 WwaWarn_B_Rq 1;
BA_ "U_CD764_MY2022_Tx" SG_ 973 WwaWarn_B_Rq 1;
BA_ "GenSigSendType" SG_ 973 TsrVlUnitMsgTxt_D_Rq 3;
BA_ "GenSigStartValueInteger" SG_ 973 TsrVlUnitMsgTxt_D_Rq 2;
BA_ "GenSigStartValue" SG_ 973 TsrVlUnitMsgTxt_D_Rq 2;
BA_ "U_T6_MCA_MY2020_Tx" SG_ 973 TsrVlUnitMsgTxt_D_Rq 1;
BA_ "U_CD542_MY2021_Tx" SG_ 973 TsrVlUnitMsgTxt_D_Rq 1;
BA_ "U_U55X_MY2022_Tx" SG_ 973 TsrVlUnitMsgTxt_D_Rq 1;
BA_ "U_CD764_MY2022_Tx" SG_ 973 TsrVlUnitMsgTxt_D_Rq 1;
BA_ "GenSigSendType" SG_ 973 TsrVLim2MsgTxt_D_Rq 3;
BA_ "GenSigStartValueInteger" SG_ 973 TsrVLim2MsgTxt_D_Rq 255;
BA_ "GenSigStartValue" SG_ 973 TsrVLim2MsgTxt_D_Rq 255;
BA_ "U_T6_MCA_MY2020_Tx" SG_ 973 TsrVLim2MsgTxt_D_Rq 1;
BA_ "U_CD542_MY2021_Tx" SG_ 973 TsrVLim2MsgTxt_D_Rq 1;
BA_ "U_U55X_MY2022_Tx" SG_ 973 TsrVLim2MsgTxt_D_Rq 1;
BA_ "U_CD764_MY2022_Tx" SG_ 973 TsrVLim2MsgTxt_D_Rq 1;
BA_ "GenSigSendType" SG_ 973 TsrVLim1MsgTxt_D_Rq 3;
BA_ "GenSigStartValueInteger" SG_ 973 TsrVLim1MsgTxt_D_Rq 255;
BA_ "GenSigStartValue" SG_ 973 TsrVLim1MsgTxt_D_Rq 255;
BA_ "U_T6_MCA_MY2020_Tx" SG_ 973 TsrVLim1MsgTxt_D_Rq 1;
BA_ "U_CD542_MY2021_Tx" SG_ 973 TsrVLim1MsgTxt_D_Rq 1;
BA_ "U_U55X_MY2022_Tx" SG_ 973 TsrVLim1MsgTxt_D_Rq 1;
BA_ "U_CD764_MY2022_Tx" SG_ 973 TsrVLim1MsgTxt_D_Rq 1;
BA_ "GenSigSendType" SG_ 973 TsrVl2StatMsgTxt_D_Rq 3;
BA_ "U_T6_MCA_MY2020_Tx" SG_ 973 TsrVl2StatMsgTxt_D_Rq 1;
BA_ "U_CD542_MY2021_Tx" SG_ 973 TsrVl2StatMsgTxt_D_Rq 1;
BA_ "U_U55X_MY2022_Tx" SG_ 973 TsrVl2StatMsgTxt_D_Rq 1;
BA_ "U_CD764_MY2022_Tx" SG_ 973 TsrVl2StatMsgTxt_D_Rq 1;
BA_ "GenSigSendType" SG_ 973 TsrVl2RstrcMsgTxt_D_Rq 3;
BA_ "U_T6_MCA_MY2020_Tx" SG_ 973 TsrVl2RstrcMsgTxt_D_Rq 1;
BA_ "U_CD542_MY2021_Tx" SG_ 973 TsrVl2RstrcMsgTxt_D_Rq 1;
BA_ "U_U55X_MY2022_Tx" SG_ 973 TsrVl2RstrcMsgTxt_D_Rq 1;
BA_ "U_CD764_MY2022_Tx" SG_ 973 TsrVl2RstrcMsgTxt_D_Rq 1;
BA_ "GenSigSendType" SG_ 973 TsrVl1StatMsgTxt_D_Rq 3;
BA_ "U_T6_MCA_MY2020_Tx" SG_ 973 TsrVl1StatMsgTxt_D_Rq 1;
BA_ "U_CD542_MY2021_Tx" SG_ 973 TsrVl1StatMsgTxt_D_Rq 1;
BA_ "U_U55X_MY2022_Tx" SG_ 973 TsrVl1StatMsgTxt_D_Rq 1;
BA_ "U_CD764_MY2022_Tx" SG_ 973 TsrVl1StatMsgTxt_D_Rq 1;
BA_ "GenSigSendType" SG_ 973 TsrVl1RstrcMsgTxt_D_Rq 3;
BA_ "U_T6_MCA_MY2020_Tx" SG_ 973 TsrVl1RstrcMsgTxt_D_Rq 1;
BA_ "U_CD542_MY2021_Tx" SG_ 973 TsrVl1RstrcMsgTxt_D_Rq 1;
BA_ "U_U55X_MY2022_Tx" SG_ 973 TsrVl1RstrcMsgTxt_D_Rq 1;
BA_ "U_CD764_MY2022_Tx" SG_ 973 TsrVl1RstrcMsgTxt_D_Rq 1;
BA_ "GenSigSendType" SG_ 973 TsrStatMsgTxt_D_Rq 3;
BA_ "U_T6_MCA_MY2020_Tx" SG_ 973 TsrStatMsgTxt_D_Rq 1;
BA_ "U_CD542_MY2021_Tx" SG_ 973 TsrStatMsgTxt_D_Rq 1;
BA_ "U_U55X_MY2022_Tx" SG_ 973 TsrStatMsgTxt_D_Rq 1;
BA_ "U_CD764_MY2022_Tx" SG_ 973 TsrStatMsgTxt_D_Rq 1;
BA_ "GenSigSendType" SG_ 973 TsrOvtkStatMsgTxt_D_Rq 3;
BA_ "U_T6_MCA_MY2020_Tx" SG_ 973 TsrOvtkStatMsgTxt_D_Rq 1;
BA_ "U_CD542_MY2021_Tx" SG_ 973 TsrOvtkStatMsgTxt_D_Rq 1;
BA_ "U_U55X_MY2022_Tx" SG_ 973 TsrOvtkStatMsgTxt_D_Rq 1;
BA_ "U_CD764_MY2022_Tx" SG_ 973 TsrOvtkStatMsgTxt_D_Rq 1;
BA_ "GenSigSendType" SG_ 973 TsrOvtkMsgTxt_D_Rq 3;
BA_ "GenSigStartValueInteger" SG_ 973 TsrOvtkMsgTxt_D_Rq 1;
BA_ "GenSigStartValue" SG_ 973 TsrOvtkMsgTxt_D_Rq 1;
BA_ "U_T6_MCA_MY2020_Tx" SG_ 973 TsrOvtkMsgTxt_D_Rq 1;
BA_ "U_CD542_MY2021_Tx" SG_ 973 TsrOvtkMsgTxt_D_Rq 1;
BA_ "U_U55X_MY2022_Tx" SG_ 973 TsrOvtkMsgTxt_D_Rq 1;
BA_ "U_CD764_MY2022_Tx" SG_ 973 TsrOvtkMsgTxt_D_Rq 1;
BA_ "GenSigSendType" SG_ 973 TsrOswWarnMsgTxt_D_Rq 3;
BA_ "GenSigStartValueInteger" SG_ 973 TsrOswWarnMsgTxt_D_Rq 1;
BA_ "GenSigStartValue" SG_ 973 TsrOswWarnMsgTxt_D_Rq 1;
BA_ "U_T6_MCA_MY2020_Tx" SG_ 973 TsrOswWarnMsgTxt_D_Rq 1;
BA_ "U_CD542_MY2021_Tx" SG_ 973 TsrOswWarnMsgTxt_D_Rq 1;
BA_ "U_U55X_MY2022_Tx" SG_ 973 TsrOswWarnMsgTxt_D_Rq 1;
BA_ "U_CD764_MY2022_Tx" SG_ 973 TsrOswWarnMsgTxt_D_Rq 1;
BA_ "GenSigSendType" SG_ 973 TsrMsgTxt_D_Rq 3;
BA_ "GenSigStartValueInteger" SG_ 973 TsrMsgTxt_D_Rq 1;
BA_ "GenSigStartValue" SG_ 973 TsrMsgTxt_D_Rq 1;
BA_ "U_T6_MCA_MY2020_Tx" SG_ 973 TsrMsgTxt_D_Rq 1;
BA_ "U_CD542_MY2021_Tx" SG_ 973 TsrMsgTxt_D_Rq 1;
BA_ "U_U55X_MY2022_Tx" SG_ 973 TsrMsgTxt_D_Rq 1;
BA_ "U_CD764_MY2022_Tx" SG_ 973 TsrMsgTxt_D_Rq 1;
BA_ "GenSigSendType" SG_ 973 LaSysOffStat_D_Dsply 3;
BA_ "U_T6_MCA_MY2020_Tx" SG_ 973 LaSysOffStat_D_Dsply 1;
BA_ "U_U55X_MY2022_Tx" SG_ 973 LaSysOffStat_D_Dsply 1;
BA_ "U_CD764_MY2022_Tx" SG_ 973 LaSysOffStat_D_Dsply 1;
BA_ "U_CX727_MY2021_Rx" SG_ 970 LkaDrvOvrrd_D_Rq 1;
BA_ "U_P702_MY2021_Rx" SG_ 970 LkaDrvOvrrd_D_Rq 1;
BA_ "U_T6_MCA_MY2020_Rx" SG_ 970 LkaDrvOvrrd_D_Rq 1;
BA_ "U_CD542_MY2021_Rx" SG_ 970 LkaDrvOvrrd_D_Rq 1;
BA_ "U_U55X_MY2022_Rx" SG_ 970 LkaDrvOvrrd_D_Rq 1;
BA_ "U_CD764_MY2022_Rx" SG_ 970 LkaDrvOvrrd_D_Rq 1;
BA_ "U_T6_MCA_MY2020_Tx" SG_ 970 LkaDrvOvrrd_D_Rq 1;
BA_ "U_CD542_MY2021_Tx" SG_ 970 LkaDrvOvrrd_D_Rq 1;
BA_ "U_U55X_MY2022_Tx" SG_ 970 LkaDrvOvrrd_D_Rq 1;
BA_ "U_CX727_MY2021_Rx" SG_ 970 LkaActvStats_D2_Req 1;
BA_ "U_P702_MY2021_Rx" SG_ 970 LkaActvStats_D2_Req 1;
BA_ "U_T6_MCA_MY2020_Rx" SG_ 970 LkaActvStats_D2_Req 1;
BA_ "U_CD542_MY2021_Rx" SG_ 970 LkaActvStats_D2_Req 1;
BA_ "U_U55X_MY2022_Rx" SG_ 970 LkaActvStats_D2_Req 1;
BA_ "U_CD764_MY2022_Rx" SG_ 970 LkaActvStats_D2_Req 1;
BA_ "U_T6_MCA_MY2020_Tx" SG_ 970 LkaActvStats_D2_Req 1;
BA_ "U_CD542_MY2021_Tx" SG_ 970 LkaActvStats_D2_Req 1;
BA_ "U_U55X_MY2022_Tx" SG_ 970 LkaActvStats_D2_Req 1;
BA_ "U_CD764_MY2022_Tx" SG_ 970 LkaActvStats_D2_Req 1;
BA_ "GenSigStartValueInteger" SG_ 970 LaRefAng_No_Req 2048;
BA_ "U_CX727_MY2021_Rx" SG_ 970 LaRefAng_No_Req 1;
BA_ "U_P702_MY2021_Rx" SG_ 970 LaRefAng_No_Req 1;
BA_ "U_T6_MCA_MY2020_Rx" SG_ 970 LaRefAng_No_Req 1;
BA_ "U_CD542_MY2021_Rx" SG_ 970 LaRefAng_No_Req 1;
BA_ "U_U55X_MY2022_Rx" SG_ 970 LaRefAng_No_Req 1;
BA_ "U_CD764_MY2022_Rx" SG_ 970 LaRefAng_No_Req 1;
BA_ "U_T6_MCA_MY2020_Tx" SG_ 970 LaRefAng_No_Req 1;
BA_ "U_CD542_MY2021_Tx" SG_ 970 LaRefAng_No_Req 1;
BA_ "U_U55X_MY2022_Tx" SG_ 970 LaRefAng_No_Req 1;
BA_ "U_CD764_MY2022_Tx" SG_ 970 LaRefAng_No_Req 1;
BA_ "U_CX727_MY2021_Rx" SG_ 970 LaRampType_B_Req 1;
BA_ "U_P702_MY2021_Rx" SG_ 970 LaRampType_B_Req 1;
BA_ "U_T6_MCA_MY2020_Rx" SG_ 970 LaRampType_B_Req 1;
BA_ "U_CD542_MY2021_Rx" SG_ 970 LaRampType_B_Req 1;
BA_ "U_U55X_MY2022_Rx" SG_ 970 LaRampType_B_Req 1;
BA_ "U_CD764_MY2022_Rx" SG_ 970 LaRampType_B_Req 1;
BA_ "U_T6_MCA_MY2020_Tx" SG_ 970 LaRampType_B_Req 1;
BA_ "U_CD542_MY2021_Tx" SG_ 970 LaRampType_B_Req 1;
BA_ "U_U55X_MY2022_Tx" SG_ 970 LaRampType_B_Req 1;
BA_ "U_CD764_MY2022_Tx" SG_ 970 LaRampType_B_Req 1;
BA_ "GenSigStartValueInteger" SG_ 970 LaCurvature_No_Calc 2048;
BA_ "U_CX727_MY2021_Rx" SG_ 970 LaCurvature_No_Calc 1;
BA_ "U_P702_MY2021_Rx" SG_ 970 LaCurvature_No_Calc 1;
BA_ "U_T6_MCA_MY2020_Rx" SG_ 970 LaCurvature_No_Calc 1;
BA_ "U_CD542_MY2021_Rx" SG_ 970 LaCurvature_No_Calc 1;
BA_ "U_U55X_MY2022_Rx" SG_ 970 LaCurvature_No_Calc 1;
BA_ "U_CD764_MY2022_Rx" SG_ 970 LaCurvature_No_Calc 1;
BA_ "U_T6_MCA_MY2020_Tx" SG_ 970 LaCurvature_No_Calc 1;
BA_ "U_CD542_MY2021_Tx" SG_ 970 LaCurvature_No_Calc 1;
BA_ "U_U55X_MY2022_Tx" SG_ 970 LaCurvature_No_Calc 1;
BA_ "U_CD764_MY2022_Tx" SG_ 970 LaCurvature_No_Calc 1;
BA_ "U_CX727_MY2021_Rx" SG_ 970 LdwActvStats_D_Req 1;
BA_ "U_P702_MY2021_Rx" SG_ 970 LdwActvStats_D_Req 1;
BA_ "U_T6_MCA_MY2020_Rx" SG_ 970 LdwActvStats_D_Req 1;
BA_ "U_CD542_MY2021_Rx" SG_ 970 LdwActvStats_D_Req 1;
BA_ "U_U55X_MY2022_Rx" SG_ 970 LdwActvStats_D_Req 1;
BA_ "U_CD764_MY2022_Rx" SG_ 970 LdwActvStats_D_Req 1;
BA_ "U_T6_MCA_MY2020_Tx" SG_ 970 LdwActvStats_D_Req 1;
BA_ "U_CD542_MY2021_Tx" SG_ 970 LdwActvStats_D_Req 1;
BA_ "U_U55X_MY2022_Tx" SG_ 970 LdwActvStats_D_Req 1;
BA_ "U_CD764_MY2022_Tx" SG_ 970 LdwActvStats_D_Req 1;
BA_ "U_CX727_MY2021_Rx" SG_ 970 LdwActvIntns_D_Req 1;
BA_ "U_P702_MY2021_Rx" SG_ 970 LdwActvIntns_D_Req 1;
BA_ "U_T6_MCA_MY2020_Rx" SG_ 970 LdwActvIntns_D_Req 1;
BA_ "U_CD542_MY2021_Rx" SG_ 970 LdwActvIntns_D_Req 1;
BA_ "U_U55X_MY2022_Rx" SG_ 970 LdwActvIntns_D_Req 1;
BA_ "U_CD764_MY2022_Rx" SG_ 970 LdwActvIntns_D_Req 1;
BA_ "U_T6_MCA_MY2020_Tx" SG_ 970 LdwActvIntns_D_Req 1;
BA_ "U_CD542_MY2021_Tx" SG_ 970 LdwActvIntns_D_Req 1;
BA_ "U_U55X_MY2022_Tx" SG_ 970 LdwActvIntns_D_Req 1;
BA_ "U_CD764_MY2022_Tx" SG_ 970 LdwActvIntns_D_Req 1;
BA_ "GenSigSendType" SG_ 394 AccTrgDist2_D_Dsply 3;
BA_ "U_T6_MCA_MY2020_Tx" SG_ 394 AccTrgDist2_D_Dsply 1;
BA_ "U_CD542_MY2021_Tx" SG_ 394 AccTrgDist2_D_Dsply 1;
BA_ "U_U55X_MY2022_Tx" SG_ 394 AccTrgDist2_D_Dsply 1;
BA_ "U_CD764_MY2022_Tx" SG_ 394 AccTrgDist2_D_Dsply 1;
BA_ "GenSigSendType" SG_ 394 AccStopRes_B_Dsply 3;
BA_ "U_T6_MCA_MY2020_Tx" SG_ 394 AccStopRes_B_Dsply 1;
BA_ "U_CD542_MY2021_Tx" SG_ 394 AccStopRes_B_Dsply 1;
BA_ "U_U55X_MY2022_Tx" SG_ 394 AccStopRes_B_Dsply 1;
BA_ "U_CD764_MY2022_Tx" SG_ 394 AccStopRes_B_Dsply 1;
BA_ "GenSigSendType" SG_ 394 TjaWarn_D_Rq 3;
BA_ "U_T6_MCA_MY2020_Tx" SG_ 394 TjaWarn_D_Rq 1;
BA_ "U_CD542_MY2021_Tx" SG_ 394 TjaWarn_D_Rq 1;
BA_ "U_U55X_MY2022_Tx" SG_ 394 TjaWarn_D_Rq 1;
BA_ "U_CD764_MY2022_Tx" SG_ 394 TjaWarn_D_Rq 1;
BA_ "GenSigSendType" SG_ 394 Tja_D_Stat 3;
BA_ "U_T6_MCA_MY2020_Rx" SG_ 394 Tja_D_Stat 1;
BA_ "U_CD542_MY2021_Rx" SG_ 394 Tja_D_Stat 1;
BA_ "U_U55X_MY2022_Rx" SG_ 394 Tja_D_Stat 1;
BA_ "U_CD764_MY2022_Rx" SG_ 394 Tja_D_Stat 1;
BA_ "U_T6_MCA_MY2020_Tx" SG_ 394 Tja_D_Stat 1;
BA_ "U_CD542_MY2021_Tx" SG_ 394 Tja_D_Stat 1;
BA_ "U_U55X_MY2022_Tx" SG_ 394 Tja_D_Stat 1;
BA_ "U_CD764_MY2022_Tx" SG_ 394 Tja_D_Stat 1;
BA_ "GenSigSendType" SG_ 394 TjaMsgTxt_D_Dsply 3;
BA_ "U_T6_MCA_MY2020_Tx" SG_ 394 TjaMsgTxt_D_Dsply 1;
BA_ "U_CD542_MY2021_Tx" SG_ 394 TjaMsgTxt_D_Dsply 1;
BA_ "U_U55X_MY2022_Tx" SG_ 394 TjaMsgTxt_D_Dsply 1;
BA_ "U_CD764_MY2022_Tx" SG_ 394 TjaMsgTxt_D_Dsply 1;
BA_ "GenSigSendType" SG_ 394 IaccLamp_D_Rq 3;
BA_ "U_T6_MCA_MY2020_Tx" SG_ 394 IaccLamp_D_Rq 1;
BA_ "U_CD542_MY2021_Tx" SG_ 394 IaccLamp_D_Rq 1;
BA_ "U_U55X_MY2022_Tx" SG_ 394 IaccLamp_D_Rq 1;
BA_ "U_CD764_MY2022_Tx" SG_ 394 IaccLamp_D_Rq 1;
BA_ "GenSigSendType" SG_ 394 AccMsgTxt_D2_Rq 3;
BA_ "U_T6_MCA_MY2020_Tx" SG_ 394 AccMsgTxt_D2_Rq 1;
BA_ "U_CD542_MY2021_Tx" SG_ 394 AccMsgTxt_D2_Rq 1;
BA_ "U_U55X_MY2022_Tx" SG_ 394 AccMsgTxt_D2_Rq 1;
BA_ "U_CD764_MY2022_Tx" SG_ 394 AccMsgTxt_D2_Rq 1;
BA_ "GenSigSendType" SG_ 394 FcwDeny_B_Dsply 3;
BA_ "U_T6_MCA_MY2020_Tx" SG_ 394 FcwDeny_B_Dsply 1;
BA_ "U_CD542_MY2021_Tx" SG_ 394 FcwDeny_B_Dsply 1;
BA_ "U_U55X_MY2022_Tx" SG_ 394 FcwDeny_B_Dsply 1;
BA_ "U_CD764_MY2022_Tx" SG_ 394 FcwDeny_B_Dsply 1;
BA_ "GenSigSendType" SG_ 394 FcwMemStat_B_Actl 3;
BA_ "U_T6_MCA_MY2020_Rx" SG_ 394 FcwMemStat_B_Actl 1;
BA_ "ECGUsedRxSignal" SG_ 394 FcwMemStat_B_Actl 1;
BA_ "U_CD542_MY2021_Rx" SG_ 394 FcwMemStat_B_Actl 1;
BA_ "U_U55X_MY2022_Rx" SG_ 394 FcwMemStat_B_Actl 1;
BA_ "U_CD764_MY2022_Rx" SG_ 394 FcwMemStat_B_Actl 1;
BA_ "U_T6_MCA_MY2020_Tx" SG_ 394 FcwMemStat_B_Actl 1;
BA_ "U_CD542_MY2021_Tx" SG_ 394 FcwMemStat_B_Actl 1;
BA_ "U_U55X_MY2022_Tx" SG_ 394 FcwMemStat_B_Actl 1;
BA_ "U_CD764_MY2022_Tx" SG_ 394 FcwMemStat_B_Actl 1;
BA_ "GenSigSendType" SG_ 394 AccTGap_B_Dsply 3;
BA_ "U_T6_MCA_MY2020_Tx" SG_ 394 AccTGap_B_Dsply 1;
BA_ "U_CD542_MY2021_Tx" SG_ 394 AccTGap_B_Dsply 1;
BA_ "U_U55X_MY2022_Tx" SG_ 394 AccTGap_B_Dsply 1;
BA_ "U_CD764_MY2022_Tx" SG_ 394 AccTGap_B_Dsply 1;
BA_ "GenSigSendType" SG_ 394 CadsAlignIncplt_B_Actl 3;
BA_ "U_T6_MCA_MY2020_Tx" SG_ 394 CadsAlignIncplt_B_Actl 1;
BA_ "U_CD542_MY2021_Tx" SG_ 394 CadsAlignIncplt_B_Actl 1;
BA_ "U_U55X_MY2022_Tx" SG_ 394 CadsAlignIncplt_B_Actl 1;
BA_ "U_CD764_MY2022_Tx" SG_ 394 CadsAlignIncplt_B_Actl 1;
BA_ "GenSigSendType" SG_ 394 AccFllwMde_B_Dsply 3;
BA_ "U_T6_MCA_MY2020_Tx" SG_ 394 AccFllwMde_B_Dsply 1;
BA_ "U_CD542_MY2021_Tx" SG_ 394 AccFllwMde_B_Dsply 1;
BA_ "U_U55X_MY2022_Tx" SG_ 394 AccFllwMde_B_Dsply 1;
BA_ "U_CD764_MY2022_Tx" SG_ 394 AccFllwMde_B_Dsply 1;
BA_ "GenSigSendType" SG_ 394 CadsRadrBlck_B_Actl 3;
BA_ "U_T6_MCA_MY2020_Tx" SG_ 394 CadsRadrBlck_B_Actl 1;
BA_ "U_CD542_MY2021_Tx" SG_ 394 CadsRadrBlck_B_Actl 1;
BA_ "U_U55X_MY2022_Tx" SG_ 394 CadsRadrBlck_B_Actl 1;
BA_ "U_CD764_MY2022_Tx" SG_ 394 CadsRadrBlck_B_Actl 1;
BA_ "GenSigSendType" SG_ 394 CmbbPostEvnt_B_Dsply 3;
BA_ "U_T6_MCA_MY2020_Tx" SG_ 394 CmbbPostEvnt_B_Dsply 1;
BA_ "U_CD542_MY2021_Tx" SG_ 394 CmbbPostEvnt_B_Dsply 1;
BA_ "U_U55X_MY2022_Tx" SG_ 394 CmbbPostEvnt_B_Dsply 1;
BA_ "U_CD764_MY2022_Tx" SG_ 394 CmbbPostEvnt_B_Dsply 1;
BA_ "GenSigSendType" SG_ 394 AccStopMde_B_Dsply 3;
BA_ "U_T6_MCA_MY2020_Tx" SG_ 394 AccStopMde_B_Dsply 1;
BA_ "U_CD542_MY2021_Tx" SG_ 394 AccStopMde_B_Dsply 1;
BA_ "U_U55X_MY2022_Tx" SG_ 394 AccStopMde_B_Dsply 1;
BA_ "U_CD764_MY2022_Tx" SG_ 394 AccStopMde_B_Dsply 1;
BA_ "GenSigSendType" SG_ 394 FcwMemSens_D_Actl 3;
BA_ "U_T6_MCA_MY2020_Rx" SG_ 394 FcwMemSens_D_Actl 1;
BA_ "ECGUsedRxSignal" SG_ 394 FcwMemSens_D_Actl 1;
BA_ "U_CD542_MY2021_Rx" SG_ 394 FcwMemSens_D_Actl 1;
BA_ "U_U55X_MY2022_Rx" SG_ 394 FcwMemSens_D_Actl 1;
BA_ "U_CD764_MY2022_Rx" SG_ 394 FcwMemSens_D_Actl 1;
BA_ "U_T6_MCA_MY2020_Tx" SG_ 394 FcwMemSens_D_Actl 1;
BA_ "U_CD542_MY2021_Tx" SG_ 394 FcwMemSens_D_Actl 1;
BA_ "U_U55X_MY2022_Tx" SG_ 394 FcwMemSens_D_Actl 1;
BA_ "U_CD764_MY2022_Tx" SG_ 394 FcwMemSens_D_Actl 1;
BA_ "GenSigSendType" SG_ 394 FcwMsgTxt_D_Rq 3;
BA_ "U_T6_MCA_MY2020_Tx" SG_ 394 FcwMsgTxt_D_Rq 1;
BA_ "U_CD542_MY2021_Tx" SG_ 394 FcwMsgTxt_D_Rq 1;
BA_ "U_U55X_MY2022_Tx" SG_ 394 FcwMsgTxt_D_Rq 1;
BA_ "U_CD764_MY2022_Tx" SG_ 394 FcwMsgTxt_D_Rq 1;
BA_ "GenSigSendType" SG_ 394 AccWarn_D_Dsply 3;
BA_ "U_T6_MCA_MY2020_Tx" SG_ 394 AccWarn_D_Dsply 1;
BA_ "U_CD542_MY2021_Tx" SG_ 394 AccWarn_D_Dsply 1;
BA_ "U_U55X_MY2022_Tx" SG_ 394 AccWarn_D_Dsply 1;
BA_ "U_CD764_MY2022_Tx" SG_ 394 AccWarn_D_Dsply 1;
BA_ "GenSigSendType" SG_ 394 FcwVisblWarn_B_Rq 3;
BA_ "U_T6_MCA_MY2020_Tx" SG_ 394 FcwVisblWarn_B_Rq 1;
BA_ "U_CD542_MY2021_Tx" SG_ 394 FcwVisblWarn_B_Rq 1;
BA_ "U_U55X_MY2022_Tx" SG_ 394 FcwVisblWarn_B_Rq 1;
BA_ "U_CD764_MY2022_Tx" SG_ 394 FcwVisblWarn_B_Rq 1;
BA_ "GenSigSendType" SG_ 394 FcwAudioWarn_B_Rq 3;
BA_ "U_T6_MCA_MY2020_Rx" SG_ 394 FcwAudioWarn_B_Rq 1;
BA_ "ECGUsedRxSignal" SG_ 394 FcwAudioWarn_B_Rq 1;
BA_ "U_CD542_MY2021_Rx" SG_ 394 FcwAudioWarn_B_Rq 1;
BA_ "U_U55X_MY2022_Rx" SG_ 394 FcwAudioWarn_B_Rq 1;
BA_ "U_CD764_MY2022_Rx" SG_ 394 FcwAudioWarn_B_Rq 1;
BA_ "U_T6_MCA_MY2020_Tx" SG_ 394 FcwAudioWarn_B_Rq 1;
BA_ "U_CD542_MY2021_Tx" SG_ 394 FcwAudioWarn_B_Rq 1;
BA_ "U_U55X_MY2022_Tx" SG_ 394 FcwAudioWarn_B_Rq 1;
BA_ "U_CD764_MY2022_Tx" SG_ 394 FcwAudioWarn_B_Rq 1;
BA_ "GenSigSendType" SG_ 394 AccTGap_D_Dsply 3;
BA_ "GenSigStartValueInteger" SG_ 394 AccTGap_D_Dsply 3;
BA_ "GenSigStartValue" SG_ 394 AccTGap_D_Dsply 3;
BA_ "U_T6_MCA_MY2020_Tx" SG_ 394 AccTGap_D_Dsply 1;
BA_ "U_CD542_MY2021_Tx" SG_ 394 AccTGap_D_Dsply 1;
BA_ "U_U55X_MY2022_Tx" SG_ 394 AccTGap_D_Dsply 1;
BA_ "U_CD764_MY2022_Tx" SG_ 394 AccTGap_D_Dsply 1;
BA_ "GenSigSendType" SG_ 394 AccMemEnbl_B_RqDrv 3;
BA_ "GenSigStartValueInteger" SG_ 394 AccMemEnbl_B_RqDrv 1;
BA_ "GenSigStartValue" SG_ 394 AccMemEnbl_B_RqDrv 1;
BA_ "U_T6_MCA_MY2020_Tx" SG_ 394 AccMemEnbl_B_RqDrv 1;
BA_ "U_CD542_MY2021_Tx" SG_ 394 AccMemEnbl_B_RqDrv 1;
BA_ "U_U55X_MY2022_Tx" SG_ 394 AccMemEnbl_B_RqDrv 1;
BA_ "U_CD764_MY2022_Tx" SG_ 394 AccMemEnbl_B_RqDrv 1;
BA_ "GenSigSendType" SG_ 394 AccStopStat_D_Dsply 3;
BA_ "U_T6_MCA_MY2020_Tx" SG_ 394 AccStopStat_D_Dsply 1;
BA_ "U_CD542_MY2021_Tx" SG_ 394 AccStopStat_D_Dsply 1;
BA_ "U_U55X_MY2022_Tx" SG_ 394 AccStopStat_D_Dsply 1;
BA_ "U_CD764_MY2022_Tx" SG_ 394 AccStopStat_D_Dsply 1;
BA_ "GenSigSendType" SG_ 394 HaDsply_No_Cs 3;
BA_ "ContentDependant" SG_ 394 HaDsply_No_Cs 1;
BA_ "MetaData" SG_ 394 HaDsply_No_Cs 1;
BA_ "U_T6_MCA_MY2020_Tx" SG_ 394 HaDsply_No_Cs 1;
BA_ "U_U55X_MY2022_Tx" SG_ 394 HaDsply_No_Cs 1;
BA_ "U_CD764_MY2022_Tx" SG_ 394 HaDsply_No_Cs 1;
BA_ "GenSigSendType" SG_ 394 HaDsply_No_Cnt 3;
BA_ "ContentDependant" SG_ 394 HaDsply_No_Cnt 1;
BA_ "MetaData" SG_ 394 HaDsply_No_Cnt 1;
BA_ "U_T6_MCA_MY2020_Tx" SG_ 394 HaDsply_No_Cnt 1;
BA_ "U_U55X_MY2022_Tx" SG_ 394 HaDsply_No_Cnt 1;
BA_ "U_CD764_MY2022_Tx" SG_ 394 HaDsply_No_Cnt 1;
BA_ "MetaData" SG_ 391 CmbbBrkDecel_No_Cnt 1;
BA_ "U_CX727_MY2021_Rx" SG_ 391 CmbbBrkDecel_No_Cnt 1;
BA_ "U_P702_MY2021_Rx" SG_ 391 CmbbBrkDecel_No_Cnt 1;
BA_ "U_T6_MCA_MY2020_Rx" SG_ 391 CmbbBrkDecel_No_Cnt 1;
BA_ "U_CD542_MY2021_Rx" SG_ 391 CmbbBrkDecel_No_Cnt 1;
BA_ "U_U55X_MY2022_Rx" SG_ 391 CmbbBrkDecel_No_Cnt 1;
BA_ "U_CD764_MY2022_Rx" SG_ 391 CmbbBrkDecel_No_Cnt 1;
BA_ "U_T6_MCA_MY2020_Tx" SG_ 391 CmbbBrkDecel_No_Cnt 1;
BA_ "U_CD542_MY2021_Tx" SG_ 391 CmbbBrkDecel_No_Cnt 1;
BA_ "U_U55X_MY2022_Tx" SG_ 391 CmbbBrkDecel_No_Cnt 1;
BA_ "U_CD764_MY2022_Tx" SG_ 391 CmbbBrkDecel_No_Cnt 1;
BA_ "U_T6_MCA_MY2020_Tx" SG_ 391 HudDsplyIntns_No_Actl 1;
BA_ "U_CD542_MY2021_Tx" SG_ 391 HudDsplyIntns_No_Actl 1;
BA_ "U_U55X_MY2022_Tx" SG_ 391 HudDsplyIntns_No_Actl 1;
BA_ "U_CD764_MY2022_Tx" SG_ 391 HudDsplyIntns_No_Actl 1;
BA_ "U_T6_MCA_MY2020_Tx" SG_ 391 HudBlk3_B_Rq 1;
BA_ "U_CD542_MY2021_Tx" SG_ 391 HudBlk3_B_Rq 1;
BA_ "U_U55X_MY2022_Tx" SG_ 391 HudBlk3_B_Rq 1;
BA_ "U_CD764_MY2022_Tx" SG_ 391 HudBlk3_B_Rq 1;
BA_ "U_T6_MCA_MY2020_Tx" SG_ 391 HudBlk2_B_Rq 1;
BA_ "U_CD542_MY2021_Tx" SG_ 391 HudBlk2_B_Rq 1;
BA_ "U_U55X_MY2022_Tx" SG_ 391 HudBlk2_B_Rq 1;
BA_ "U_CD764_MY2022_Tx" SG_ 391 HudBlk2_B_Rq 1;
BA_ "U_T6_MCA_MY2020_Tx" SG_ 391 HudBlk1_B_Rq 1;
BA_ "U_CD542_MY2021_Tx" SG_ 391 HudBlk1_B_Rq 1;
BA_ "U_U55X_MY2022_Tx" SG_ 391 HudBlk1_B_Rq 1;
BA_ "U_CD764_MY2022_Tx" SG_ 391 HudBlk1_B_Rq 1;
BA_ "U_T6_MCA_MY2020_Tx" SG_ 391 HudFlashRate_D_Actl 1;
BA_ "U_CD542_MY2021_Tx" SG_ 391 HudFlashRate_D_Actl 1;
BA_ "U_U55X_MY2022_Tx" SG_ 391 HudFlashRate_D_Actl 1;
BA_ "U_CD764_MY2022_Tx" SG_ 391 HudFlashRate_D_Actl 1;
BA_ "MetaData" SG_ 391 CmbbBrkDecel_No_Cs 1;
BA_ "U_CX727_MY2021_Rx" SG_ 391 CmbbBrkDecel_No_Cs 1;
BA_ "U_P702_MY2021_Rx" SG_ 391 CmbbBrkDecel_No_Cs 1;
BA_ "U_T6_MCA_MY2020_Rx" SG_ 391 CmbbBrkDecel_No_Cs 1;
BA_ "U_CD542_MY2021_Rx" SG_ 391 CmbbBrkDecel_No_Cs 1;
BA_ "U_U55X_MY2022_Rx" SG_ 391 CmbbBrkDecel_No_Cs 1;
BA_ "U_CD764_MY2022_Rx" SG_ 391 CmbbBrkDecel_No_Cs 1;
BA_ "U_T6_MCA_MY2020_Tx" SG_ 391 CmbbBrkDecel_No_Cs 1;
BA_ "U_CD542_MY2021_Tx" SG_ 391 CmbbBrkDecel_No_Cs 1;
BA_ "U_U55X_MY2022_Tx" SG_ 391 CmbbBrkDecel_No_Cs 1;
BA_ "U_CD764_MY2022_Tx" SG_ 391 CmbbBrkDecel_No_Cs 1;
BA_ "GenSigStartValueInteger" SG_ 391 CmbbBrkDecel_A_Rq 5129;
BA_ "U_CX727_MY2021_Rx" SG_ 391 CmbbBrkDecel_A_Rq 1;
BA_ "U_P702_MY2021_Rx" SG_ 391 CmbbBrkDecel_A_Rq 1;
BA_ "U_T6_MCA_MY2020_Rx" SG_ 391 CmbbBrkDecel_A_Rq 1;
BA_ "U_CD542_MY2021_Rx" SG_ 391 CmbbBrkDecel_A_Rq 1;
BA_ "U_U55X_MY2022_Rx" SG_ 391 CmbbBrkDecel_A_Rq 1;
BA_ "U_CD764_MY2022_Rx" SG_ 391 CmbbBrkDecel_A_Rq 1;
BA_ "U_T6_MCA_MY2020_Tx" SG_ 391 CmbbBrkDecel_A_Rq 1;
BA_ "U_CD542_MY2021_Tx" SG_ 391 CmbbBrkDecel_A_Rq 1;
BA_ "U_U55X_MY2022_Tx" SG_ 391 CmbbBrkDecel_A_Rq 1;
BA_ "U_CD764_MY2022_Tx" SG_ 391 CmbbBrkDecel_A_Rq 1;
BA_ "U_CX727_MY2021_Rx" SG_ 391 CmbbBrkPrchg_D_Rq 1;
BA_ "U_P702_MY2021_Rx" SG_ 391 CmbbBrkPrchg_D_Rq 1;
BA_ "U_T6_MCA_MY2020_Rx" SG_ 391 CmbbBrkPrchg_D_Rq 1;
BA_ "ECGUsedRxSignal" SG_ 391 CmbbBrkPrchg_D_Rq 1;
BA_ "U_CD542_MY2021_Rx" SG_ 391 CmbbBrkPrchg_D_Rq 1;
BA_ "U_U55X_MY2022_Rx" SG_ 391 CmbbBrkPrchg_D_Rq 1;
BA_ "U_CD764_MY2022_Rx" SG_ 391 CmbbBrkPrchg_D_Rq 1;
BA_ "U_T6_MCA_MY2020_Tx" SG_ 391 CmbbBrkPrchg_D_Rq 1;
BA_ "U_CD542_MY2021_Tx" SG_ 391 CmbbBrkPrchg_D_Rq 1;
BA_ "U_U55X_MY2022_Tx" SG_ 391 CmbbBrkPrchg_D_Rq 1;
BA_ "U_CD764_MY2022_Tx" SG_ 391 CmbbBrkPrchg_D_Rq 1;
BA_ "U_CX727_MY2021_Rx" SG_ 391 CmbbBrkDecel_B_Rq 1;
BA_ "U_P702_MY2021_Rx" SG_ 391 CmbbBrkDecel_B_Rq 1;
BA_ "U_T6_MCA_MY2020_Rx" SG_ 391 CmbbBrkDecel_B_Rq 1;
BA_ "ECGUsedRxSignal" SG_ 391 CmbbBrkDecel_B_Rq 1;
BA_ "U_CD542_MY2021_Rx" SG_ 391 CmbbBrkDecel_B_Rq 1;
BA_ "U_U55X_MY2022_Rx" SG_ 391 CmbbBrkDecel_B_Rq 1;
BA_ "U_CD764_MY2022_Rx" SG_ 391 CmbbBrkDecel_B_Rq 1;
BA_ "U_T6_MCA_MY2020_Tx" SG_ 391 CmbbBrkDecel_B_Rq 1;
BA_ "U_CD542_MY2021_Tx" SG_ 391 CmbbBrkDecel_B_Rq 1;
BA_ "U_U55X_MY2022_Tx" SG_ 391 CmbbBrkDecel_B_Rq 1;
BA_ "U_CD764_MY2022_Tx" SG_ 391 CmbbBrkDecel_B_Rq 1;
BA_ "U_CX727_MY2021_Rx" SG_ 391 CmbbBaSens_D_Rq 1;
BA_ "U_P702_MY2021_Rx" SG_ 391 CmbbBaSens_D_Rq 1;
BA_ "U_T6_MCA_MY2020_Rx" SG_ 391 CmbbBaSens_D_Rq 1;
BA_ "U_CD542_MY2021_Rx" SG_ 391 CmbbBaSens_D_Rq 1;
BA_ "U_U55X_MY2022_Rx" SG_ 391 CmbbBaSens_D_Rq 1;
BA_ "U_CD764_MY2022_Rx" SG_ 391 CmbbBaSens_D_Rq 1;
BA_ "U_T6_MCA_MY2020_Tx" SG_ 391 CmbbBaSens_D_Rq 1;
BA_ "U_CD542_MY2021_Tx" SG_ 391 CmbbBaSens_D_Rq 1;
BA_ "U_U55X_MY2022_Tx" SG_ 391 CmbbBaSens_D_Rq 1;
BA_ "U_CD764_MY2022_Tx" SG_ 391 CmbbBaSens_D_Rq 1;
BA_ "GenSigStartValueInteger" SG_ 390 AccBrkTot_A_Rq 5129;
BA_ "U_CX727_MY2021_Rx" SG_ 390 AccBrkTot_A_Rq 1;
BA_ "U_P702_MY2021_Rx" SG_ 390 AccBrkTot_A_Rq 1;
BA_ "U_T6_MCA_MY2020_Rx" SG_ 390 AccBrkTot_A_Rq 1;
BA_ "U_CD542_MY2021_Rx" SG_ 390 AccBrkTot_A_Rq 1;
BA_ "U_U55X_MY2022_Rx" SG_ 390 AccBrkTot_A_Rq 1;
BA_ "U_CD764_MY2022_Rx" SG_ 390 AccBrkTot_A_Rq 1;
BA_ "U_T6_MCA_MY2020_Tx" SG_ 390 AccBrkTot_A_Rq 1;
BA_ "U_CD542_MY2021_Tx" SG_ 390 AccBrkTot_A_Rq 1;
BA_ "U_U55X_MY2022_Tx" SG_ 390 AccBrkTot_A_Rq 1;
BA_ "U_CD764_MY2022_Tx" SG_ 390 AccBrkTot_A_Rq 1;
BA_ "U_CX727_MY2021_Rx" SG_ 390 AccPrpl_A_Pred 1;
BA_ "U_P702_MY2021_Rx" SG_ 390 AccPrpl_A_Pred 1;
BA_ "U_T6_MCA_MY2020_Rx" SG_ 390 AccPrpl_A_Pred 1;
BA_ "U_CD542_MY2021_Rx" SG_ 390 AccPrpl_A_Pred 1;
BA_ "U_U55X_MY2022_Rx" SG_ 390 AccPrpl_A_Pred 1;
BA_ "U_CD764_MY2022_Rx" SG_ 390 AccPrpl_A_Pred 1;
BA_ "U_T6_MCA_MY2020_Tx" SG_ 390 AccPrpl_A_Pred 1;
BA_ "U_CD542_MY2021_Tx" SG_ 390 AccPrpl_A_Pred 1;
BA_ "U_U55X_MY2022_Tx" SG_ 390 AccPrpl_A_Pred 1;
BA_ "U_CD764_MY2022_Tx" SG_ 390 AccPrpl_A_Pred 1;
BA_ "U_P702_MY2021_Rx" SG_ 390 AccVeh_V_Trg 1;
BA_ "U_T6_MCA_MY2020_Rx" SG_ 390 AccVeh_V_Trg 1;
BA_ "U_CD542_MY2021_Rx" SG_ 390 AccVeh_V_Trg 1;
BA_ "U_U55X_MY2022_Rx" SG_ 390 AccVeh_V_Trg 1;
BA_ "U_CD764_MY2022_Rx" SG_ 390 AccVeh_V_Trg 1;
BA_ "U_T6_MCA_MY2020_Tx" SG_ 390 AccVeh_V_Trg 1;
BA_ "U_CD542_MY2021_Tx" SG_ 390 AccVeh_V_Trg 1;
BA_ "U_U55X_MY2022_Tx" SG_ 390 AccVeh_V_Trg 1;
BA_ "U_CD764_MY2022_Tx" SG_ 390 AccVeh_V_Trg 1;
BA_ "U_CX727_MY2021_Rx" SG_ 390 AccBrkPrkEl_B_Rq 1;
BA_ "U_P702_MY2021_Rx" SG_ 390 AccBrkPrkEl_B_Rq 1;
BA_ "U_T6_MCA_MY2020_Rx" SG_ 390 AccBrkPrkEl_B_Rq 1;
BA_ "U_CD542_MY2021_Rx" SG_ 390 AccBrkPrkEl_B_Rq 1;
BA_ "U_U55X_MY2022_Rx" SG_ 390 AccBrkPrkEl_B_Rq 1;
BA_ "U_CD764_MY2022_Rx" SG_ 390 AccBrkPrkEl_B_Rq 1;
BA_ "U_T6_MCA_MY2020_Tx" SG_ 390 AccBrkPrkEl_B_Rq 1;
BA_ "U_CD542_MY2021_Tx" SG_ 390 AccBrkPrkEl_B_Rq 1;
BA_ "U_U55X_MY2022_Tx" SG_ 390 AccBrkPrkEl_B_Rq 1;
BA_ "U_CD764_MY2022_Tx" SG_ 390 AccBrkPrkEl_B_Rq 1;
BA_ "U_T6_MCA_MY2020_Tx" SG_ 390 Cmbb_B_Enbl 1;
BA_ "U_CD542_MY2021_Tx" SG_ 390 Cmbb_B_Enbl 1;
BA_ "U_U55X_MY2022_Tx" SG_ 390 Cmbb_B_Enbl 1;
BA_ "U_CD764_MY2022_Tx" SG_ 390 Cmbb_B_Enbl 1;
BA_ "U_T6_MCA_MY2020_Tx" SG_ 390 CmbbOvrrd_B_RqDrv 1;
BA_ "U_CD542_MY2021_Tx" SG_ 390 CmbbOvrrd_B_RqDrv 1;
BA_ "U_U55X_MY2022_Tx" SG_ 390 CmbbOvrrd_B_RqDrv 1;
BA_ "U_CD764_MY2022_Tx" SG_ 390 CmbbOvrrd_B_RqDrv 1;
BA_ "U_CX727_MY2021_Rx" SG_ 390 CmbbDeny_B_Actl 1;
BA_ "U_P702_MY2021_Rx" SG_ 390 CmbbDeny_B_Actl 1;
BA_ "U_T6_MCA_MY2020_Rx" SG_ 390 CmbbDeny_B_Actl 1;
BA_ "U_CD542_MY2021_Rx" SG_ 390 CmbbDeny_B_Actl 1;
BA_ "U_U55X_MY2022_Rx" SG_ 390 CmbbDeny_B_Actl 1;
BA_ "U_CD764_MY2022_Rx" SG_ 390 CmbbDeny_B_Actl 1;
BA_ "U_T6_MCA_MY2020_Tx" SG_ 390 CmbbDeny_B_Actl 1;
BA_ "U_CD542_MY2021_Tx" SG_ 390 CmbbDeny_B_Actl 1;
BA_ "U_U55X_MY2022_Tx" SG_ 390 CmbbDeny_B_Actl 1;
BA_ "U_CD764_MY2022_Tx" SG_ 390 CmbbDeny_B_Actl 1;
BA_ "U_CX727_MY2021_Rx" SG_ 390 CmbbEngTqMn_B_Rq 1;
BA_ "U_P702_MY2021_Rx" SG_ 390 CmbbEngTqMn_B_Rq 1;
BA_ "U_T6_MCA_MY2020_Rx" SG_ 390 CmbbEngTqMn_B_Rq 1;
BA_ "U_CD542_MY2021_Rx" SG_ 390 CmbbEngTqMn_B_Rq 1;
BA_ "U_U55X_MY2022_Rx" SG_ 390 CmbbEngTqMn_B_Rq 1;
BA_ "U_CD764_MY2022_Rx" SG_ 390 CmbbEngTqMn_B_Rq 1;
BA_ "U_T6_MCA_MY2020_Tx" SG_ 390 CmbbEngTqMn_B_Rq 1;
BA_ "U_CD542_MY2021_Tx" SG_ 390 CmbbEngTqMn_B_Rq 1;
BA_ "U_U55X_MY2022_Tx" SG_ 390 CmbbEngTqMn_B_Rq 1;
BA_ "U_CD764_MY2022_Tx" SG_ 390 CmbbEngTqMn_B_Rq 1;
BA_ "U_CX727_MY2021_Rx" SG_ 390 AccPrpl_A_Rq 1;
BA_ "U_P702_MY2021_Rx" SG_ 390 AccPrpl_A_Rq 1;
BA_ "U_T6_MCA_MY2020_Rx" SG_ 390 AccPrpl_A_Rq 1;
BA_ "U_CD542_MY2021_Rx" SG_ 390 AccPrpl_A_Rq 1;
BA_ "U_U55X_MY2022_Rx" SG_ 390 AccPrpl_A_Rq 1;
BA_ "U_CD764_MY2022_Rx" SG_ 390 AccPrpl_A_Rq 1;
BA_ "U_T6_MCA_MY2020_Tx" SG_ 390 AccPrpl_A_Rq 1;
BA_ "U_CD542_MY2021_Tx" SG_ 390 AccPrpl_A_Rq 1;
BA_ "U_U55X_MY2022_Tx" SG_ 390 AccPrpl_A_Rq 1;
BA_ "U_CD764_MY2022_Tx" SG_ 390 AccPrpl_A_Rq 1;
BA_ "U_CX727_MY2021_Rx" SG_ 390 AccDeny_B_Rq 1;
BA_ "U_P702_MY2021_Rx" SG_ 390 AccDeny_B_Rq 1;
BA_ "U_T6_MCA_MY2020_Rx" SG_ 390 AccDeny_B_Rq 1;
BA_ "U_CD542_MY2021_Rx" SG_ 390 AccDeny_B_Rq 1;
BA_ "U_U55X_MY2022_Rx" SG_ 390 AccDeny_B_Rq 1;
BA_ "U_CD764_MY2022_Rx" SG_ 390 AccDeny_B_Rq 1;
BA_ "U_T6_MCA_MY2020_Tx" SG_ 390 AccDeny_B_Rq 1;
BA_ "U_CD542_MY2021_Tx" SG_ 390 AccDeny_B_Rq 1;
BA_ "U_U55X_MY2022_Tx" SG_ 390 AccDeny_B_Rq 1;
BA_ "U_CD764_MY2022_Tx" SG_ 390 AccDeny_B_Rq 1;
BA_ "WakeupSignal" SG_ 390 AccResumEnbl_B_Rq 1;
BA_ "U_CX727_MY2021_Rx" SG_ 390 AccResumEnbl_B_Rq 1;
BA_ "U_P702_MY2021_Rx" SG_ 390 AccResumEnbl_B_Rq 1;
BA_ "U_T6_MCA_MY2020_Rx" SG_ 390 AccResumEnbl_B_Rq 1;
BA_ "U_CD542_MY2021_Rx" SG_ 390 AccResumEnbl_B_Rq 1;
BA_ "U_U55X_MY2022_Rx" SG_ 390 AccResumEnbl_B_Rq 1;
BA_ "U_CD764_MY2022_Rx" SG_ 390 AccResumEnbl_B_Rq 1;
BA_ "U_T6_MCA_MY2020_Tx" SG_ 390 AccResumEnbl_B_Rq 1;
BA_ "U_CD542_MY2021_Tx" SG_ 390 AccResumEnbl_B_Rq 1;
BA_ "U_U55X_MY2022_Tx" SG_ 390 AccResumEnbl_B_Rq 1;
BA_ "U_CD764_MY2022_Tx" SG_ 390 AccResumEnbl_B_Rq 1;
BA_ "U_CX727_MY2021_Rx" SG_ 390 AccCancl_B_Rq 1;
BA_ "U_P702_MY2021_Rx" SG_ 390 AccCancl_B_Rq 1;
BA_ "U_T6_MCA_MY2020_Rx" SG_ 390 AccCancl_B_Rq 1;
BA_ "U_CD542_MY2021_Rx" SG_ 390 AccCancl_B_Rq 1;
BA_ "U_U55X_MY2022_Rx" SG_ 390 AccCancl_B_Rq 1;
BA_ "U_CD764_MY2022_Rx" SG_ 390 AccCancl_B_Rq 1;
BA_ "U_T6_MCA_MY2020_Tx" SG_ 390 AccCancl_B_Rq 1;
BA_ "U_CD542_MY2021_Tx" SG_ 390 AccCancl_B_Rq 1;
BA_ "U_U55X_MY2022_Tx" SG_ 390 AccCancl_B_Rq 1;
BA_ "U_CD764_MY2022_Tx" SG_ 390 AccCancl_B_Rq 1;
BA_ "U_CX727_MY2021_Rx" SG_ 390 AccBrkPrchg_B_Rq 1;
BA_ "U_P702_MY2021_Rx" SG_ 390 AccBrkPrchg_B_Rq 1;
BA_ "U_T6_MCA_MY2020_Rx" SG_ 390 AccBrkPrchg_B_Rq 1;
BA_ "U_CD542_MY2021_Rx" SG_ 390 AccBrkPrchg_B_Rq 1;
BA_ "U_U55X_MY2022_Rx" SG_ 390 AccBrkPrchg_B_Rq 1;
BA_ "U_CD764_MY2022_Rx" SG_ 390 AccBrkPrchg_B_Rq 1;
BA_ "U_T6_MCA_MY2020_Tx" SG_ 390 AccBrkPrchg_B_Rq 1;
BA_ "U_CD542_MY2021_Tx" SG_ 390 AccBrkPrchg_B_Rq 1;
BA_ "U_U55X_MY2022_Tx" SG_ 390 AccBrkPrchg_B_Rq 1;
BA_ "U_CD764_MY2022_Tx" SG_ 390 AccBrkPrchg_B_Rq 1;
BA_ "U_CX727_MY2021_Rx" SG_ 390 AccBrkDecel_B_Rq 1;
BA_ "U_P702_MY2021_Rx" SG_ 390 AccBrkDecel_B_Rq 1;
BA_ "U_T6_MCA_MY2020_Rx" SG_ 390 AccBrkDecel_B_Rq 1;
BA_ "U_CD542_MY2021_Rx" SG_ 390 AccBrkDecel_B_Rq 1;
BA_ "U_U55X_MY2022_Rx" SG_ 390 AccBrkDecel_B_Rq 1;
BA_ "U_CD764_MY2022_Rx" SG_ 390 AccBrkDecel_B_Rq 1;
BA_ "U_T6_MCA_MY2020_Tx" SG_ 390 AccBrkDecel_B_Rq 1;
BA_ "U_CD542_MY2021_Tx" SG_ 390 AccBrkDecel_B_Rq 1;
BA_ "U_U55X_MY2022_Tx" SG_ 390 AccBrkDecel_B_Rq 1;
BA_ "U_CD764_MY2022_Tx" SG_ 390 AccBrkDecel_B_Rq 1;
BA_ "U_CX727_MY2021_Rx" SG_ 390 AccStopStat_B_Rq 1;
BA_ "U_P702_MY2021_Rx" SG_ 390 AccStopStat_B_Rq 1;
BA_ "U_T6_MCA_MY2020_Rx" SG_ 390 AccStopStat_B_Rq 1;
BA_ "U_CD542_MY2021_Rx" SG_ 390 AccStopStat_B_Rq 1;
BA_ "U_U55X_MY2022_Rx" SG_ 390 AccStopStat_B_Rq 1;
BA_ "U_CD764_MY2022_Rx" SG_ 390 AccStopStat_B_Rq 1;
BA_ "U_T6_MCA_MY2020_Tx" SG_ 390 AccStopStat_B_Rq 1;
BA_ "U_CD542_MY2021_Tx" SG_ 390 AccStopStat_B_Rq 1;
BA_ "U_U55X_MY2022_Tx" SG_ 390 AccStopStat_B_Rq 1;
BA_ "U_CD764_MY2022_Tx" SG_ 390 AccStopStat_B_Rq 1;
BA_ "U_T6_MCA_MY2020_Rx" SG_ 390 AccAutoResum_D_Rq 1;
BA_ "U_U55X_MY2022_Rx" SG_ 390 AccAutoResum_D_Rq 1;
BA_ "U_CD764_MY2022_Rx" SG_ 390 AccAutoResum_D_Rq 1;
BA_ "U_T6_MCA_MY2020_Tx" SG_ 390 AccAutoResum_D_Rq 1;
BA_ "U_CD542_MY2021_Tx" SG_ 390 AccAutoResum_D_Rq 1;
BA_ "U_U55X_MY2022_Tx" SG_ 390 AccAutoResum_D_Rq 1;
BA_ "U_CD764_MY2022_Tx" SG_ 390 AccAutoResum_D_Rq 1;
BA_ "U_T6_MCA_MY2020_Rx" SG_ 390 AccBrkPulse_B_Rq 1;
BA_ "U_CD542_MY2021_Rx" SG_ 390 AccBrkPulse_B_Rq 1;
BA_ "U_U55X_MY2022_Rx" SG_ 390 AccBrkPulse_B_Rq 1;
BA_ "U_CD764_MY2022_Rx" SG_ 390 AccBrkPulse_B_Rq 1;
BA_ "U_T6_MCA_MY2020_Tx" SG_ 390 AccBrkPulse_B_Rq 1;
BA_ "U_CD542_MY2021_Tx" SG_ 390 AccBrkPulse_B_Rq 1;
BA_ "U_U55X_MY2022_Tx" SG_ 390 AccBrkPulse_B_Rq 1;
BA_ "U_CD764_MY2022_Tx" SG_ 390 AccBrkPulse_B_Rq 1;
BA_ "U_U55X_MY2022_Tx" SG_ 611 AwdSys_D_Stat 1;
BA_ "U_T6_MCA_MY2020_Tx" SG_ 611 AwdSys_D_Stat 1;
BA_ "U_P702_MY2021_Tx" SG_ 611 AwdSys_D_Stat 1;
BA_ "U_CDX706_MY2023_Rx" SG_ 611 AwdSys_D_Stat 1;
BA_ "U_U55X_MY2022_Rx" SG_ 611 AwdSys_D_Stat 1;
BA_ "U_T6_MCA_MY2020_Rx" SG_ 611 AwdSys_D_Stat 1;
BA_ "U_P702_MY2021_Rx" SG_ 611 AwdSys_D_Stat 1;
BA_ "GenSigStartValueInteger" SG_ 611 AwdRnge_D_Actl 7;
BA_ "GenSigStartValue" SG_ 611 AwdRnge_D_Actl 7;
BA_ "U_P702_MY2021_Rx" SG_ 611 AwdRnge_D_Actl 1;
BA_ "U_T6_MCA_MY2020_Rx" SG_ 611 AwdRnge_D_Actl 1;
BA_ "ECGUsedRxSignal" SG_ 611 AwdRnge_D_Actl 1;
BA_ "U_CD542_MY2021_Rx" SG_ 611 AwdRnge_D_Actl 1;
BA_ "U_U55X_MY2022_Rx" SG_ 611 AwdRnge_D_Actl 1;
BA_ "U_CD764_MY2022_Rx" SG_ 611 AwdRnge_D_Actl 1;
BA_ "U_P702_MY2021_Tx" SG_ 611 AwdRnge_D_Actl 1;
BA_ "U_T6_MCA_MY2020_Tx" SG_ 611 AwdRnge_D_Actl 1;
BA_ "U_U55X_MY2022_Tx" SG_ 611 AwdRnge_D_Actl 1;
BA_ "U_P702_MY2021_Tx" SG_ 611 AwdLoLamp_D_RqDsply 1;
BA_ "U_T6_MCA_MY2020_Tx" SG_ 611 AwdLoLamp_D_RqDsply 1;
BA_ "U_U55X_MY2022_Tx" SG_ 611 AwdLoLamp_D_RqDsply 1;
BA_ "U_P702_MY2021_Rx" SG_ 611 AwdHiLamp_D_RqDsply 1;
BA_ "U_T6_MCA_MY2020_Rx" SG_ 611 AwdHiLamp_D_RqDsply 1;
BA_ "U_U55X_MY2022_Rx" SG_ 611 AwdHiLamp_D_RqDsply 1;
BA_ "U_P702_MY2021_Tx" SG_ 611 AwdHiLamp_D_RqDsply 1;
BA_ "U_T6_MCA_MY2020_Tx" SG_ 611 AwdHiLamp_D_RqDsply 1;
BA_ "U_U55X_MY2022_Tx" SG_ 611 AwdHiLamp_D_RqDsply 1;
BA_ "U_P702_MY2021_Rx" SG_ 611 AwdAutoLamp_D_RqDsply 1;
BA_ "U_T6_MCA_MY2020_Rx" SG_ 611 AwdAutoLamp_D_RqDsply 1;
BA_ "U_U55X_MY2022_Rx" SG_ 611 AwdAutoLamp_D_RqDsply 1;
BA_ "U_P702_MY2021_Tx" SG_ 611 AwdAutoLamp_D_RqDsply 1;
BA_ "U_T6_MCA_MY2020_Tx" SG_ 611 AwdAutoLamp_D_RqDsply 1;
BA_ "U_U55X_MY2022_Tx" SG_ 611 AwdAutoLamp_D_RqDsply 1;
BA_ "U_P702_MY2021_Tx" SG_ 611 Awd2wdLamp_D_RqDsply 1;
BA_ "U_T6_MCA_MY2020_Tx" SG_ 611 Awd2wdLamp_D_RqDsply 1;
BA_ "U_U55X_MY2022_Tx" SG_ 611 Awd2wdLamp_D_RqDsply 1;
BA_ "U_T6_MCA_MY2020_Tx" SG_ 611 AwdTerrMdeChng_D_Rdy 1;
BA_ "U_T6_MCA_MY2020_Tx" SG_ 611 AwdTerrMde_D_Actl 1;
BA_ "ContentDependant" SG_ 611 AwdStat_D_RqDsply 1;
BA_ "U_P702_MY2021_Rx" SG_ 611 AwdStat_D_RqDsply 1;
BA_ "U_T6_MCA_MY2020_Rx" SG_ 611 AwdStat_D_RqDsply 1;
BA_ "U_U55X_MY2022_Rx" SG_ 611 AwdStat_D_RqDsply 1;
BA_ "U_CX727_MY2021_Tx" SG_ 611 AwdStat_D_RqDsply 1;
BA_ "U_P702_MY2021_Tx" SG_ 611 AwdStat_D_RqDsply 1;
BA_ "U_T6_MCA_MY2020_Tx" SG_ 611 AwdStat_D_RqDsply 1;
BA_ "U_U55X_MY2022_Tx" SG_ 611 AwdStat_D_RqDsply 1;
BA_ "U_CX727_MY2021_Rx" SG_ 611 AwdLck_D_Stat 1;
BA_ "U_P702_MY2021_Rx" SG_ 611 AwdLck_D_Stat 1;
BA_ "U_T6_MCA_MY2020_Rx" SG_ 611 AwdLck_D_Stat 1;
BA_ "U_CD542_MY2021_Rx" SG_ 611 AwdLck_D_Stat 1;
BA_ "U_U55X_MY2022_Rx" SG_ 611 AwdLck_D_Stat 1;
BA_ "U_CD764_MY2022_Rx" SG_ 611 AwdLck_D_Stat 1;
BA_ "U_CX727_MY2021_Tx" SG_ 611 AwdLck_D_Stat 1;
BA_ "U_P702_MY2021_Tx" SG_ 611 AwdLck_D_Stat 1;
BA_ "U_T6_MCA_MY2020_Tx" SG_ 611 AwdLck_D_Stat 1;
BA_ "U_U55X_MY2022_Tx" SG_ 611 AwdLck_D_Stat 1;
BA_ "ContentDependant" SG_ 611 AwdSrvcRqd_B_Rq 1;
BA_ "U_P702_MY2021_Rx" SG_ 611 AwdSrvcRqd_B_Rq 1;
BA_ "U_T6_MCA_MY2020_Rx" SG_ 611 AwdSrvcRqd_B_Rq 1;
BA_ "U_U55X_MY2022_Rx" SG_ 611 AwdSrvcRqd_B_Rq 1;
BA_ "U_CX727_MY2021_Tx" SG_ 611 AwdSrvcRqd_B_Rq 1;
BA_ "U_P702_MY2021_Tx" SG_ 611 AwdSrvcRqd_B_Rq 1;
BA_ "U_T6_MCA_MY2020_Tx" SG_ 611 AwdSrvcRqd_B_Rq 1;
BA_ "U_U55X_MY2022_Tx" SG_ 611 AwdSrvcRqd_B_Rq 1;
BA_ "ContentDependant" SG_ 611 AwdLck_Tq_Rq 1;
BA_ "U_P702_MY2021_Rx" SG_ 611 AwdLck_Tq_Rq 1;
BA_ "U_T6_MCA_MY2020_Rx" SG_ 611 AwdLck_Tq_Rq 1;
BA_ "U_U55X_MY2022_Rx" SG_ 611 AwdLck_Tq_Rq 1;
BA_ "U_CX727_MY2021_Tx" SG_ 611 AwdLck_Tq_Rq 1;
BA_ "U_P702_MY2021_Tx" SG_ 611 AwdLck_Tq_Rq 1;
BA_ "U_T6_MCA_MY2020_Tx" SG_ 611 AwdLck_Tq_Rq 1;
BA_ "U_U55X_MY2022_Tx" SG_ 611 AwdLck_Tq_Rq 1;
BA_ "GenSigStartValueInteger" SG_ 1461 PSCM_GWOnBoardTester 255;
BA_ "ContentDependant" SG_ 1461 PSCM_GWOnBoardTester 1;
BA_ "GenSigStartValue" SG_ 1461 PSCM_GWOnBoardTester 255;
BA_ "U_P702_MY2021_Rx" SG_ 1461 PSCM_GWOnBoardTester 1;
BA_ "U_T6_MCA_MY2020_Rx" SG_ 1461 PSCM_GWOnBoardTester 1;
BA_ "U_CD542_MY2021_Rx" SG_ 1461 PSCM_GWOnBoardTester 1;
BA_ "U_U55X_MY2022_Rx" SG_ 1461 PSCM_GWOnBoardTester 1;
BA_ "U_CD764_MY2022_Rx" SG_ 1461 PSCM_GWOnBoardTester 1;
BA_ "U_CX727_MY2021_Tx" SG_ 1461 PSCM_GWOnBoardTester 1;
BA_ "U_P702_MY2021_Tx" SG_ 1461 PSCM_GWOnBoardTester 1;
BA_ "U_T6_MCA_MY2020_Tx" SG_ 1461 PSCM_GWOnBoardTester 1;
BA_ "U_CD542_MY2021_Tx" SG_ 1461 PSCM_GWOnBoardTester 1;
BA_ "U_U55X_MY2022_Tx" SG_ 1461 PSCM_GWOnBoardTester 1;
BA_ "U_CD764_MY2022_Tx" SG_ 1461 PSCM_GWOnBoardTester 1;
BA_ "GenSigStartValueInteger" SG_ 1461 PSCM_GWNMProxy 255;
BA_ "ContentDependant" SG_ 1461 PSCM_GWNMProxy 1;
BA_ "GenSigStartValue" SG_ 1461 PSCM_GWNMProxy 255;
BA_ "U_P702_MY2021_Rx" SG_ 1461 PSCM_GWNMProxy 1;
BA_ "U_T6_MCA_MY2020_Rx" SG_ 1461 PSCM_GWNMProxy 1;
BA_ "U_CD542_MY2021_Rx" SG_ 1461 PSCM_GWNMProxy 1;
BA_ "U_U55X_MY2022_Rx" SG_ 1461 PSCM_GWNMProxy 1;
BA_ "U_CD764_MY2022_Rx" SG_ 1461 PSCM_GWNMProxy 1;
BA_ "U_CX727_MY2021_Tx" SG_ 1461 PSCM_GWNMProxy 1;
BA_ "U_P702_MY2021_Tx" SG_ 1461 PSCM_GWNMProxy 1;
BA_ "U_T6_MCA_MY2020_Tx" SG_ 1461 PSCM_GWNMProxy 1;
BA_ "U_CD542_MY2021_Tx" SG_ 1461 PSCM_GWNMProxy 1;
BA_ "U_U55X_MY2022_Tx" SG_ 1461 PSCM_GWNMProxy 1;
BA_ "U_CD764_MY2022_Tx" SG_ 1461 PSCM_GWNMProxy 1;
BA_ "GenSigStartValueInteger" SG_ 1461 PSCM_AutoSarNMReserved4 255;
BA_ "ContentDependant" SG_ 1461 PSCM_AutoSarNMReserved4 1;
BA_ "GenSigStartValue" SG_ 1461 PSCM_AutoSarNMReserved4 255;
BA_ "U_P702_MY2021_Rx" SG_ 1461 PSCM_AutoSarNMReserved4 1;
BA_ "U_T6_MCA_MY2020_Rx" SG_ 1461 PSCM_AutoSarNMReserved4 1;
BA_ "U_CD542_MY2021_Rx" SG_ 1461 PSCM_AutoSarNMReserved4 1;
BA_ "U_U55X_MY2022_Rx" SG_ 1461 PSCM_AutoSarNMReserved4 1;
BA_ "U_CD764_MY2022_Rx" SG_ 1461 PSCM_AutoSarNMReserved4 1;
BA_ "U_CX727_MY2021_Tx" SG_ 1461 PSCM_AutoSarNMReserved4 1;
BA_ "U_P702_MY2021_Tx" SG_ 1461 PSCM_AutoSarNMReserved4 1;
BA_ "U_T6_MCA_MY2020_Tx" SG_ 1461 PSCM_AutoSarNMReserved4 1;
BA_ "U_CD542_MY2021_Tx" SG_ 1461 PSCM_AutoSarNMReserved4 1;
BA_ "U_U55X_MY2022_Tx" SG_ 1461 PSCM_AutoSarNMReserved4 1;
BA_ "U_CD764_MY2022_Tx" SG_ 1461 PSCM_AutoSarNMReserved4 1;
BA_ "GenSigStartValueInteger" SG_ 1461 PSCM_AutoSarNMReserved3 255;
BA_ "ContentDependant" SG_ 1461 PSCM_AutoSarNMReserved3 1;
BA_ "GenSigStartValue" SG_ 1461 PSCM_AutoSarNMReserved3 255;
BA_ "U_P702_MY2021_Rx" SG_ 1461 PSCM_AutoSarNMReserved3 1;
BA_ "U_T6_MCA_MY2020_Rx" SG_ 1461 PSCM_AutoSarNMReserved3 1;
BA_ "U_CD542_MY2021_Rx" SG_ 1461 PSCM_AutoSarNMReserved3 1;
BA_ "U_U55X_MY2022_Rx" SG_ 1461 PSCM_AutoSarNMReserved3 1;
BA_ "U_CD764_MY2022_Rx" SG_ 1461 PSCM_AutoSarNMReserved3 1;
BA_ "U_CX727_MY2021_Tx" SG_ 1461 PSCM_AutoSarNMReserved3 1;
BA_ "U_P702_MY2021_Tx" SG_ 1461 PSCM_AutoSarNMReserved3 1;
BA_ "U_T6_MCA_MY2020_Tx" SG_ 1461 PSCM_AutoSarNMReserved3 1;
BA_ "U_CD542_MY2021_Tx" SG_ 1461 PSCM_AutoSarNMReserved3 1;
BA_ "U_U55X_MY2022_Tx" SG_ 1461 PSCM_AutoSarNMReserved3 1;
BA_ "U_CD764_MY2022_Tx" SG_ 1461 PSCM_AutoSarNMReserved3 1;
BA_ "GenSigStartValueInteger" SG_ 1461 PSCM_AutoSarNMReserved2 255;
BA_ "ContentDependant" SG_ 1461 PSCM_AutoSarNMReserved2 1;
BA_ "GenSigStartValue" SG_ 1461 PSCM_AutoSarNMReserved2 255;
BA_ "U_T6_MCA_MY2020_Rx" SG_ 1461 PSCM_AutoSarNMReserved2 1;
BA_ "U_CD542_MY2021_Rx" SG_ 1461 PSCM_AutoSarNMReserved2 1;
BA_ "U_U55X_MY2022_Rx" SG_ 1461 PSCM_AutoSarNMReserved2 1;
BA_ "U_CD764_MY2022_Rx" SG_ 1461 PSCM_AutoSarNMReserved2 1;
BA_ "U_CX727_MY2021_Tx" SG_ 1461 PSCM_AutoSarNMReserved2 1;
BA_ "U_P702_MY2021_Tx" SG_ 1461 PSCM_AutoSarNMReserved2 1;
BA_ "U_T6_MCA_MY2020_Tx" SG_ 1461 PSCM_AutoSarNMReserved2 1;
BA_ "U_CD542_MY2021_Tx" SG_ 1461 PSCM_AutoSarNMReserved2 1;
BA_ "U_U55X_MY2022_Tx" SG_ 1461 PSCM_AutoSarNMReserved2 1;
BA_ "U_CD764_MY2022_Tx" SG_ 1461 PSCM_AutoSarNMReserved2 1;
BA_ "GenSigStartValueInteger" SG_ 1461 PSCM_AutoSarNMReserved1 255;
BA_ "ContentDependant" SG_ 1461 PSCM_AutoSarNMReserved1 1;
BA_ "GenSigStartValue" SG_ 1461 PSCM_AutoSarNMReserved1 255;
BA_ "U_T6_MCA_MY2020_Rx" SG_ 1461 PSCM_AutoSarNMReserved1 1;
BA_ "U_CD542_MY2021_Rx" SG_ 1461 PSCM_AutoSarNMReserved1 1;
BA_ "U_U55X_MY2022_Rx" SG_ 1461 PSCM_AutoSarNMReserved1 1;
BA_ "U_CD764_MY2022_Rx" SG_ 1461 PSCM_AutoSarNMReserved1 1;
BA_ "U_CX727_MY2021_Tx" SG_ 1461 PSCM_AutoSarNMReserved1 1;
BA_ "U_P702_MY2021_Tx" SG_ 1461 PSCM_AutoSarNMReserved1 1;
BA_ "U_T6_MCA_MY2020_Tx" SG_ 1461 PSCM_AutoSarNMReserved1 1;
BA_ "U_CD542_MY2021_Tx" SG_ 1461 PSCM_AutoSarNMReserved1 1;
BA_ "U_U55X_MY2022_Tx" SG_ 1461 PSCM_AutoSarNMReserved1 1;
BA_ "U_CD764_MY2022_Tx" SG_ 1461 PSCM_AutoSarNMReserved1 1;
BA_ "GenSigStartValueInteger" SG_ 1461 PSCM_AutoSarNMNodeId 181;
BA_ "ContentDependant" SG_ 1461 PSCM_AutoSarNMNodeId 1;
BA_ "GenSigStartValue" SG_ 1461 PSCM_AutoSarNMNodeId 181;
BA_ "U_T6_MCA_MY2020_Rx" SG_ 1461 PSCM_AutoSarNMNodeId 1;
BA_ "U_CD542_MY2021_Rx" SG_ 1461 PSCM_AutoSarNMNodeId 1;
BA_ "U_U55X_MY2022_Rx" SG_ 1461 PSCM_AutoSarNMNodeId 1;
BA_ "U_CD764_MY2022_Rx" SG_ 1461 PSCM_AutoSarNMNodeId 1;
BA_ "U_CX727_MY2021_Tx" SG_ 1461 PSCM_AutoSarNMNodeId 1;
BA_ "U_P702_MY2021_Tx" SG_ 1461 PSCM_AutoSarNMNodeId 1;
BA_ "U_T6_MCA_MY2020_Tx" SG_ 1461 PSCM_AutoSarNMNodeId 1;
BA_ "U_CD542_MY2021_Tx" SG_ 1461 PSCM_AutoSarNMNodeId 1;
BA_ "U_U55X_MY2022_Tx" SG_ 1461 PSCM_AutoSarNMNodeId 1;
BA_ "U_CD764_MY2022_Tx" SG_ 1461 PSCM_AutoSarNMNodeId 1;
BA_ "ContentDependant" SG_ 1461 PSCM_AutoSarNMControl 1;
BA_ "U_T6_MCA_MY2020_Rx" SG_ 1461 PSCM_AutoSarNMControl 1;
BA_ "U_CD542_MY2021_Rx" SG_ 1461 PSCM_AutoSarNMControl 1;
BA_ "U_U55X_MY2022_Rx" SG_ 1461 PSCM_AutoSarNMControl 1;
BA_ "U_CD764_MY2022_Rx" SG_ 1461 PSCM_AutoSarNMControl 1;
BA_ "U_CX727_MY2021_Tx" SG_ 1461 PSCM_AutoSarNMControl 1;
BA_ "U_P702_MY2021_Tx" SG_ 1461 PSCM_AutoSarNMControl 1;
BA_ "U_T6_MCA_MY2020_Tx" SG_ 1461 PSCM_AutoSarNMControl 1;
BA_ "U_CD542_MY2021_Tx" SG_ 1461 PSCM_AutoSarNMControl 1;
BA_ "U_U55X_MY2022_Tx" SG_ 1461 PSCM_AutoSarNMControl 1;
BA_ "U_CD764_MY2022_Tx" SG_ 1461 PSCM_AutoSarNMControl 1;
BA_ "GenSigSendType" SG_ 1047 EsaOn_B_Stat 3;
BA_ "GenSigStartValueInteger" SG_ 1047 EsaOn_B_Stat 1;
BA_ "GenSigStartValue" SG_ 1047 EsaOn_B_Stat 1;
BA_ "U_CX727_MY2021_Tx" SG_ 1047 EsaOn_B_Stat 1;
BA_ "U_P702_MY2021_Tx" SG_ 1047 EsaOn_B_Stat 1;
BA_ "U_T6_MCA_MY2020_Tx" SG_ 1047 EsaOn_B_Stat 1;
BA_ "U_CD542_MY2021_Tx" SG_ 1047 EsaOn_B_Stat 1;
BA_ "U_CD764_MY2022_Tx" SG_ 1047 EsaOn_B_Stat 1;
BA_ "GenSigSendType" SG_ 1047 SelDrvMdeSte_D_Stat 3;
BA_ "U_CX727_MY2021_Rx" SG_ 1047 SelDrvMdeSte_D_Stat 1;
BA_ "U_P702_MY2021_Rx" SG_ 1047 SelDrvMdeSte_D_Stat 1;
BA_ "U_T6_MCA_MY2020_Rx" SG_ 1047 SelDrvMdeSte_D_Stat 1;
BA_ "U_CD542_MY2021_Rx" SG_ 1047 SelDrvMdeSte_D_Stat 1;
BA_ "U_U55X_MY2022_Rx" SG_ 1047 SelDrvMdeSte_D_Stat 1;
BA_ "U_CD764_MY2022_Rx" SG_ 1047 SelDrvMdeSte_D_Stat 1;
BA_ "U_CX727_MY2021_Tx" SG_ 1047 SelDrvMdeSte_D_Stat 1;
BA_ "U_P702_MY2021_Tx" SG_ 1047 SelDrvMdeSte_D_Stat 1;
BA_ "U_T6_MCA_MY2020_Tx" SG_ 1047 SelDrvMdeSte_D_Stat 1;
BA_ "U_CD542_MY2021_Tx" SG_ 1047 SelDrvMdeSte_D_Stat 1;
BA_ "U_CD764_MY2022_Tx" SG_ 1047 SelDrvMdeSte_D_Stat 1;
BA_ "GenSigStartValueInteger" SG_ 972 TjaHandsOnCnfdnc_B_Est 1;
BA_ "GenSigStartValue" SG_ 972 TjaHandsOnCnfdnc_B_Est 1;
BA_ "U_T6_MCA_MY2020_Rx" SG_ 972 TjaHandsOnCnfdnc_B_Est 1;
BA_ "U_CD542_MY2021_Rx" SG_ 972 TjaHandsOnCnfdnc_B_Est 1;
BA_ "U_U55X_MY2022_Rx" SG_ 972 TjaHandsOnCnfdnc_B_Est 1;
BA_ "U_CD764_MY2022_Rx" SG_ 972 TjaHandsOnCnfdnc_B_Est 1;
BA_ "U_CX727_MY2021_Tx" SG_ 972 TjaHandsOnCnfdnc_B_Est 1;
BA_ "U_P702_MY2021_Tx" SG_ 972 TjaHandsOnCnfdnc_B_Est 1;
BA_ "U_T6_MCA_MY2020_Tx" SG_ 972 TjaHandsOnCnfdnc_B_Est 1;
BA_ "U_CD542_MY2021_Tx" SG_ 972 TjaHandsOnCnfdnc_B_Est 1;
BA_ "U_U55X_MY2022_Tx" SG_ 972 TjaHandsOnCnfdnc_B_Est 1;
BA_ "U_CD764_MY2022_Tx" SG_ 972 TjaHandsOnCnfdnc_B_Est 1;
BA_ "GenSigStartValueInteger" SG_ 972 LaHandsOff_B_Actl 1;
BA_ "GenSigStartValue" SG_ 972 LaHandsOff_B_Actl 1;
BA_ "U_T6_MCA_MY2020_Rx" SG_ 972 LaHandsOff_B_Actl 1;
BA_ "U_CD542_MY2021_Rx" SG_ 972 LaHandsOff_B_Actl 1;
BA_ "U_U55X_MY2022_Rx" SG_ 972 LaHandsOff_B_Actl 1;
BA_ "U_CD764_MY2022_Rx" SG_ 972 LaHandsOff_B_Actl 1;
BA_ "U_CX727_MY2021_Tx" SG_ 972 LaHandsOff_B_Actl 1;
BA_ "U_P702_MY2021_Tx" SG_ 972 LaHandsOff_B_Actl 1;
BA_ "U_T6_MCA_MY2020_Tx" SG_ 972 LaHandsOff_B_Actl 1;
BA_ "U_CD542_MY2021_Tx" SG_ 972 LaHandsOff_B_Actl 1;
BA_ "U_U55X_MY2022_Tx" SG_ 972 LaHandsOff_B_Actl 1;
BA_ "U_CD764_MY2022_Tx" SG_ 972 LaHandsOff_B_Actl 1;
BA_ "U_T6_MCA_MY2020_Rx" SG_ 972 LaActDeny_B_Actl 1;
BA_ "U_CD542_MY2021_Rx" SG_ 972 LaActDeny_B_Actl 1;
BA_ "U_U55X_MY2022_Rx" SG_ 972 LaActDeny_B_Actl 1;
BA_ "U_CD764_MY2022_Rx" SG_ 972 LaActDeny_B_Actl 1;
BA_ "U_CX727_MY2021_Tx" SG_ 972 LaActDeny_B_Actl 1;
BA_ "U_P702_MY2021_Tx" SG_ 972 LaActDeny_B_Actl 1;
BA_ "U_T6_MCA_MY2020_Tx" SG_ 972 LaActDeny_B_Actl 1;
BA_ "U_CD542_MY2021_Tx" SG_ 972 LaActDeny_B_Actl 1;
BA_ "U_U55X_MY2022_Tx" SG_ 972 LaActDeny_B_Actl 1;
BA_ "U_CD764_MY2022_Tx" SG_ 972 LaActDeny_B_Actl 1;
BA_ "U_T6_MCA_MY2020_Rx" SG_ 972 LatCtlSte_D_Stat 1;
BA_ "U_CD542_MY2021_Rx" SG_ 972 LatCtlSte_D_Stat 1;
BA_ "U_U55X_MY2022_Rx" SG_ 972 LatCtlSte_D_Stat 1;
BA_ "U_CD764_MY2022_Rx" SG_ 972 LatCtlSte_D_Stat 1;
BA_ "U_T6_MCA_MY2020_Tx" SG_ 972 LatCtlSte_D_Stat 1;
BA_ "U_CD542_MY2021_Tx" SG_ 972 LatCtlSte_D_Stat 1;
BA_ "U_U55X_MY2022_Tx" SG_ 972 LatCtlSte_D_Stat 1;
BA_ "U_CD764_MY2022_Tx" SG_ 972 LatCtlSte_D_Stat 1;
BA_ "U_T6_MCA_MY2020_Rx" SG_ 972 LatCtlLim_D_Stat 1;
BA_ "U_CD542_MY2021_Rx" SG_ 972 LatCtlLim_D_Stat 1;
BA_ "U_U55X_MY2022_Rx" SG_ 972 LatCtlLim_D_Stat 1;
BA_ "U_CD764_MY2022_Rx" SG_ 972 LatCtlLim_D_Stat 1;
BA_ "U_T6_MCA_MY2020_Tx" SG_ 972 LatCtlLim_D_Stat 1;
BA_ "U_CD542_MY2021_Tx" SG_ 972 LatCtlLim_D_Stat 1;
BA_ "U_U55X_MY2022_Tx" SG_ 972 LatCtlLim_D_Stat 1;
BA_ "U_CD764_MY2022_Tx" SG_ 972 LatCtlLim_D_Stat 1;
BA_ "MetaData" SG_ 972 LatCtlCpbltyDStat_No_Cs 1;
BA_ "U_T6_MCA_MY2020_Rx" SG_ 972 LatCtlCpbltyDStat_No_Cs 1;
BA_ "U_CD542_MY2021_Rx" SG_ 972 LatCtlCpbltyDStat_No_Cs 1;
BA_ "U_U55X_MY2022_Rx" SG_ 972 LatCtlCpbltyDStat_No_Cs 1;
BA_ "U_CD764_MY2022_Rx" SG_ 972 LatCtlCpbltyDStat_No_Cs 1;
BA_ "U_T6_MCA_MY2020_Tx" SG_ 972 LatCtlCpbltyDStat_No_Cs 1;
BA_ "U_U55X_MY2022_Tx" SG_ 972 LatCtlCpbltyDStat_No_Cs 1;
BA_ "U_CD764_MY2022_Tx" SG_ 972 LatCtlCpbltyDStat_No_Cs 1;
BA_ "MetaData" SG_ 972 LatCtlCpbltyDStat_No_Cnt 1;
BA_ "U_T6_MCA_MY2020_Rx" SG_ 972 LatCtlCpbltyDStat_No_Cnt 1;
BA_ "U_CD542_MY2021_Rx" SG_ 972 LatCtlCpbltyDStat_No_Cnt 1;
BA_ "U_U55X_MY2022_Rx" SG_ 972 LatCtlCpbltyDStat_No_Cnt 1;
BA_ "U_CD764_MY2022_Rx" SG_ 972 LatCtlCpbltyDStat_No_Cnt 1;
BA_ "U_T6_MCA_MY2020_Tx" SG_ 972 LatCtlCpbltyDStat_No_Cnt 1;
BA_ "U_U55X_MY2022_Tx" SG_ 972 LatCtlCpbltyDStat_No_Cnt 1;
BA_ "U_CD764_MY2022_Tx" SG_ 972 LatCtlCpbltyDStat_No_Cnt 1;
BA_ "U_T6_MCA_MY2020_Rx" SG_ 972 LatCtlCpblty_D_Stat 1;
BA_ "U_CD542_MY2021_Rx" SG_ 972 LatCtlCpblty_D_Stat 1;
BA_ "U_U55X_MY2022_Rx" SG_ 972 LatCtlCpblty_D_Stat 1;
BA_ "U_CD764_MY2022_Rx" SG_ 972 LatCtlCpblty_D_Stat 1;
BA_ "U_T6_MCA_MY2020_Tx" SG_ 972 LatCtlCpblty_D_Stat 1;
BA_ "U_U55X_MY2022_Tx" SG_ 972 LatCtlCpblty_D_Stat 1;
BA_ "U_CD764_MY2022_Tx" SG_ 972 LatCtlCpblty_D_Stat 1;
BA_ "U_CX727_MY2021_Tx" SG_ 130 SteMdule_D_Stat 1;
BA_ "U_P702_MY2021_Tx" SG_ 130 SteMdule_D_Stat 1;
BA_ "U_T6_MCA_MY2020_Tx" SG_ 130 SteMdule_D_Stat 1;
BA_ "U_CD542_MY2021_Tx" SG_ 130 SteMdule_D_Stat 1;
BA_ "U_U55X_MY2022_Tx" SG_ 130 SteMdule_D_Stat 1;
BA_ "U_CD764_MY2022_Tx" SG_ 130 SteMdule_D_Stat 1;
BA_ "GenSigStartValueInteger" SG_ 130 SteMdule_U_Meas 255;
BA_ "GenSigStartValue" SG_ 130 SteMdule_U_Meas 255;
BA_ "U_CX727_MY2021_Tx" SG_ 130 SteMdule_U_Meas 1;
BA_ "U_P702_MY2021_Tx" SG_ 130 SteMdule_U_Meas 1;
BA_ "U_T6_MCA_MY2020_Tx" SG_ 130 SteMdule_U_Meas 1;
BA_ "U_CD542_MY2021_Tx" SG_ 130 SteMdule_U_Meas 1;
BA_ "U_U55X_MY2022_Tx" SG_ 130 SteMdule_U_Meas 1;
BA_ "U_CD764_MY2022_Tx" SG_ 130 SteMdule_U_Meas 1;
BA_ "GenSigStartValueInteger" SG_ 130 SteMdule_I_Est 4095;
BA_ "GenSigStartValue" SG_ 130 SteMdule_I_Est 4095;
BA_ "U_CX727_MY2021_Tx" SG_ 130 SteMdule_I_Est 1;
BA_ "U_P702_MY2021_Tx" SG_ 130 SteMdule_I_Est 1;
BA_ "U_T6_MCA_MY2020_Tx" SG_ 130 SteMdule_I_Est 1;
BA_ "U_CD542_MY2021_Tx" SG_ 130 SteMdule_I_Est 1;
BA_ "U_U55X_MY2022_Tx" SG_ 130 SteMdule_I_Est 1;
BA_ "U_CD764_MY2022_Tx" SG_ 130 SteMdule_I_Est 1;
BA_ "U_T6_MCA_MY2020_Rx" SG_ 130 EPAS_Failure 1;
BA_ "U_CD542_MY2021_Rx" SG_ 130 EPAS_Failure 1;
BA_ "U_U55X_MY2022_Rx" SG_ 130 EPAS_Failure 1;
BA_ "U_CD764_MY2022_Rx" SG_ 130 EPAS_Failure 1;
BA_ "U_CX727_MY2021_Tx" SG_ 130 EPAS_Failure 1;
BA_ "U_P702_MY2021_Tx" SG_ 130 EPAS_Failure 1;
BA_ "U_T6_MCA_MY2020_Tx" SG_ 130 EPAS_Failure 1;
BA_ "U_CD542_MY2021_Tx" SG_ 130 EPAS_Failure 1;
BA_ "U_U55X_MY2022_Tx" SG_ 130 EPAS_Failure 1;
BA_ "U_CD764_MY2022_Tx" SG_ 130 EPAS_Failure 1;
BA_ "GenSigStartValueInteger" SG_ 130 SteeringColumnTorque 254;
BA_ "GenSigStartValue" SG_ 130 SteeringColumnTorque 254;
BA_ "U_CX727_MY2021_Rx" SG_ 130 SteeringColumnTorque 1;
BA_ "U_P702_MY2021_Rx" SG_ 130 SteeringColumnTorque 1;
BA_ "U_T6_MCA_MY2020_Rx" SG_ 130 SteeringColumnTorque 1;
BA_ "U_CD542_MY2021_Rx" SG_ 130 SteeringColumnTorque 1;
BA_ "U_U55X_MY2022_Rx" SG_ 130 SteeringColumnTorque 1;
BA_ "U_CD764_MY2022_Rx" SG_ 130 SteeringColumnTorque 1;
BA_ "U_CX727_MY2021_Tx" SG_ 130 SteeringColumnTorque 1;
BA_ "U_P702_MY2021_Tx" SG_ 130 SteeringColumnTorque 1;
BA_ "U_T6_MCA_MY2020_Tx" SG_ 130 SteeringColumnTorque 1;
BA_ "U_CD542_MY2021_Tx" SG_ 130 SteeringColumnTorque 1;
BA_ "U_U55X_MY2022_Tx" SG_ 130 SteeringColumnTorque 1;
BA_ "U_CD764_MY2022_Tx" SG_ 130 SteeringColumnTorque 1;
BA_ "U_T6_MCA_MY2020_Rx" SG_ 130 SAPPAngleControlStat6 1;
BA_ "U_CD542_MY2021_Rx" SG_ 130 SAPPAngleControlStat6 1;
BA_ "U_U55X_MY2022_Rx" SG_ 130 SAPPAngleControlStat6 1;
BA_ "U_CD764_MY2022_Rx" SG_ 130 SAPPAngleControlStat6 1;
BA_ "U_CX727_MY2021_Tx" SG_ 130 SAPPAngleControlStat6 1;
BA_ "U_P702_MY2021_Tx" SG_ 130 SAPPAngleControlStat6 1;
BA_ "U_T6_MCA_MY2020_Tx" SG_ 130 SAPPAngleControlStat6 1;
BA_ "U_CD542_MY2021_Tx" SG_ 130 SAPPAngleControlStat6 1;
BA_ "U_U55X_MY2022_Tx" SG_ 130 SAPPAngleControlStat6 1;
BA_ "U_CD764_MY2022_Tx" SG_ 130 SAPPAngleControlStat6 1;
BA_ "U_T6_MCA_MY2020_Rx" SG_ 130 SAPPAngleControlStat5 1;
BA_ "U_CD542_MY2021_Rx" SG_ 130 SAPPAngleControlStat5 1;
BA_ "U_U55X_MY2022_Rx" SG_ 130 SAPPAngleControlStat5 1;
BA_ "U_CD764_MY2022_Rx" SG_ 130 SAPPAngleControlStat5 1;
BA_ "U_CX727_MY2021_Tx" SG_ 130 SAPPAngleControlStat5 1;
BA_ "U_P702_MY2021_Tx" SG_ 130 SAPPAngleControlStat5 1;
BA_ "U_T6_MCA_MY2020_Tx" SG_ 130 SAPPAngleControlStat5 1;
BA_ "U_CD542_MY2021_Tx" SG_ 130 SAPPAngleControlStat5 1;
BA_ "U_U55X_MY2022_Tx" SG_ 130 SAPPAngleControlStat5 1;
BA_ "U_CD764_MY2022_Tx" SG_ 130 SAPPAngleControlStat5 1;
BA_ "U_T6_MCA_MY2020_Rx" SG_ 130 SAPPAngleControlStat4 1;
BA_ "U_CD542_MY2021_Rx" SG_ 130 SAPPAngleControlStat4 1;
BA_ "U_U55X_MY2022_Rx" SG_ 130 SAPPAngleControlStat4 1;
BA_ "U_CD764_MY2022_Rx" SG_ 130 SAPPAngleControlStat4 1;
BA_ "U_CX727_MY2021_Tx" SG_ 130 SAPPAngleControlStat4 1;
BA_ "U_P702_MY2021_Tx" SG_ 130 SAPPAngleControlStat4 1;
BA_ "U_T6_MCA_MY2020_Tx" SG_ 130 SAPPAngleControlStat4 1;
BA_ "U_CD542_MY2021_Tx" SG_ 130 SAPPAngleControlStat4 1;
BA_ "U_U55X_MY2022_Tx" SG_ 130 SAPPAngleControlStat4 1;
BA_ "U_CD764_MY2022_Tx" SG_ 130 SAPPAngleControlStat4 1;
BA_ "U_T6_MCA_MY2020_Rx" SG_ 130 SAPPAngleControlStat3 1;
BA_ "U_CD542_MY2021_Rx" SG_ 130 SAPPAngleControlStat3 1;
BA_ "U_U55X_MY2022_Rx" SG_ 130 SAPPAngleControlStat3 1;
BA_ "U_CD764_MY2022_Rx" SG_ 130 SAPPAngleControlStat3 1;
BA_ "U_CX727_MY2021_Tx" SG_ 130 SAPPAngleControlStat3 1;
BA_ "U_P702_MY2021_Tx" SG_ 130 SAPPAngleControlStat3 1;
BA_ "U_T6_MCA_MY2020_Tx" SG_ 130 SAPPAngleControlStat3 1;
BA_ "U_CD542_MY2021_Tx" SG_ 130 SAPPAngleControlStat3 1;
BA_ "U_U55X_MY2022_Tx" SG_ 130 SAPPAngleControlStat3 1;
BA_ "U_CD764_MY2022_Tx" SG_ 130 SAPPAngleControlStat3 1;
BA_ "U_T6_MCA_MY2020_Rx" SG_ 130 SAPPAngleControlStat2 1;
BA_ "U_CD542_MY2021_Rx" SG_ 130 SAPPAngleControlStat2 1;
BA_ "U_U55X_MY2022_Rx" SG_ 130 SAPPAngleControlStat2 1;
BA_ "U_CD764_MY2022_Rx" SG_ 130 SAPPAngleControlStat2 1;
BA_ "U_CX727_MY2021_Tx" SG_ 130 SAPPAngleControlStat2 1;
BA_ "U_P702_MY2021_Tx" SG_ 130 SAPPAngleControlStat2 1;
BA_ "U_T6_MCA_MY2020_Tx" SG_ 130 SAPPAngleControlStat2 1;
BA_ "U_CD542_MY2021_Tx" SG_ 130 SAPPAngleControlStat2 1;
BA_ "U_U55X_MY2022_Tx" SG_ 130 SAPPAngleControlStat2 1;
BA_ "U_CD764_MY2022_Tx" SG_ 130 SAPPAngleControlStat2 1;
BA_ "U_T6_MCA_MY2020_Rx" SG_ 130 SAPPAngleControlStat1 1;
BA_ "U_CD542_MY2021_Rx" SG_ 130 SAPPAngleControlStat1 1;
BA_ "U_U55X_MY2022_Rx" SG_ 130 SAPPAngleControlStat1 1;
BA_ "U_CD764_MY2022_Rx" SG_ 130 SAPPAngleControlStat1 1;
BA_ "U_CX727_MY2021_Tx" SG_ 130 SAPPAngleControlStat1 1;
BA_ "U_P702_MY2021_Tx" SG_ 130 SAPPAngleControlStat1 1;
BA_ "U_T6_MCA_MY2020_Tx" SG_ 130 SAPPAngleControlStat1 1;
BA_ "U_CD542_MY2021_Tx" SG_ 130 SAPPAngleControlStat1 1;
BA_ "U_U55X_MY2022_Tx" SG_ 130 SAPPAngleControlStat1 1;
BA_ "U_CD764_MY2022_Tx" SG_ 130 SAPPAngleControlStat1 1;
BA_ "U_CX727_MY2021_Rx" SG_ 126 StePw_B_Rq 1;
BA_ "U_P702_MY2021_Rx" SG_ 126 StePw_B_Rq 1;
BA_ "U_T6_MCA_MY2020_Rx" SG_ 126 StePw_B_Rq 1;
BA_ "U_CD542_MY2021_Rx" SG_ 126 StePw_B_Rq 1;
BA_ "U_U55X_MY2022_Rx" SG_ 126 StePw_B_Rq 1;
BA_ "U_CD764_MY2022_Rx" SG_ 126 StePw_B_Rq 1;
BA_ "U_P702_MY2021_Tx" SG_ 126 StePw_B_Rq 1;
BA_ "U_T6_MCA_MY2020_Tx" SG_ 126 StePw_B_Rq 1;
BA_ "U_CD542_MY2021_Tx" SG_ 126 StePw_B_Rq 1;
BA_ "U_U55X_MY2022_Tx" SG_ 126 StePw_B_Rq 1;
BA_ "U_CD764_MY2022_Tx" SG_ 126 StePw_B_Rq 1;
BA_ "GenSigStartValueInteger" SG_ 126 StePinRelInit_An_Sns 65535;
BA_ "ContentDependant" SG_ 126 StePinRelInit_An_Sns 1;
BA_ "GenSigStartValue" SG_ 126 StePinRelInit_An_Sns 65535;
BA_ "U_CX727_MY2021_Rx" SG_ 126 StePinRelInit_An_Sns 1;
BA_ "U_P702_MY2021_Rx" SG_ 126 StePinRelInit_An_Sns 1;
BA_ "U_T6_MCA_MY2020_Rx" SG_ 126 StePinRelInit_An_Sns 1;
BA_ "U_CD542_MY2021_Rx" SG_ 126 StePinRelInit_An_Sns 1;
BA_ "U_U55X_MY2022_Rx" SG_ 126 StePinRelInit_An_Sns 1;
BA_ "U_CD764_MY2022_Rx" SG_ 126 StePinRelInit_An_Sns 1;
BA_ "U_CX727_MY2021_Tx" SG_ 126 StePinRelInit_An_Sns 1;
BA_ "U_P702_MY2021_Tx" SG_ 126 StePinRelInit_An_Sns 1;
BA_ "U_T6_MCA_MY2020_Tx" SG_ 126 StePinRelInit_An_Sns 1;
BA_ "U_CD542_MY2021_Tx" SG_ 126 StePinRelInit_An_Sns 1;
BA_ "U_U55X_MY2022_Tx" SG_ 126 StePinRelInit_An_Sns 1;
BA_ "U_CD764_MY2022_Tx" SG_ 126 StePinRelInit_An_Sns 1;
BA_ "GenSigStartValueInteger" SG_ 126 StePinCompAnEst_D_Qf 1;
BA_ "MetaData" SG_ 126 StePinCompAnEst_D_Qf 1;
BA_ "GenSigStartValue" SG_ 126 StePinCompAnEst_D_Qf 1;
BA_ "U_CX727_MY2021_Rx" SG_ 126 StePinCompAnEst_D_Qf 1;
BA_ "U_P702_MY2021_Rx" SG_ 126 StePinCompAnEst_D_Qf 1;
BA_ "U_T6_MCA_MY2020_Rx" SG_ 126 StePinCompAnEst_D_Qf 1;
BA_ "ECGUsedRxSignal" SG_ 126 StePinCompAnEst_D_Qf 1;
BA_ "U_CD542_MY2021_Rx" SG_ 126 StePinCompAnEst_D_Qf 1;
BA_ "U_U55X_MY2022_Rx" SG_ 126 StePinCompAnEst_D_Qf 1;
BA_ "U_CD764_MY2022_Rx" SG_ 126 StePinCompAnEst_D_Qf 1;
BA_ "U_CX727_MY2021_Tx" SG_ 126 StePinCompAnEst_D_Qf 1;
BA_ "U_P702_MY2021_Tx" SG_ 126 StePinCompAnEst_D_Qf 1;
BA_ "U_T6_MCA_MY2020_Tx" SG_ 126 StePinCompAnEst_D_Qf 1;
BA_ "U_CD542_MY2021_Tx" SG_ 126 StePinCompAnEst_D_Qf 1;
BA_ "U_U55X_MY2022_Tx" SG_ 126 StePinCompAnEst_D_Qf 1;
BA_ "U_CD764_MY2022_Tx" SG_ 126 StePinCompAnEst_D_Qf 1;
BA_ "GenSigStartValueInteger" SG_ 126 StePinComp_An_Est 16000;
BA_ "U_CX727_MY2021_Rx" SG_ 126 StePinComp_An_Est 1;
BA_ "U_P702_MY2021_Rx" SG_ 126 StePinComp_An_Est 1;
BA_ "U_T6_MCA_MY2020_Rx" SG_ 126 StePinComp_An_Est 1;
BA_ "ECGUsedRxSignal" SG_ 126 StePinComp_An_Est 1;
BA_ "U_CD542_MY2021_Rx" SG_ 126 StePinComp_An_Est 1;
BA_ "U_U55X_MY2022_Rx" SG_ 126 StePinComp_An_Est 1;
BA_ "U_CD764_MY2022_Rx" SG_ 126 StePinComp_An_Est 1;
BA_ "U_CX727_MY2021_Tx" SG_ 126 StePinComp_An_Est 1;
BA_ "U_P702_MY2021_Tx" SG_ 126 StePinComp_An_Est 1;
BA_ "U_T6_MCA_MY2020_Tx" SG_ 126 StePinComp_An_Est 1;
BA_ "U_CD542_MY2021_Tx" SG_ 126 StePinComp_An_Est 1;
BA_ "U_U55X_MY2022_Tx" SG_ 126 StePinComp_An_Est 1;
BA_ "U_CD764_MY2022_Tx" SG_ 126 StePinComp_An_Est 1;
BA_ "ContentDependant" SG_ 126 StePinAn_No_Cs 1;
BA_ "MetaData" SG_ 126 StePinAn_No_Cs 1;
BA_ "U_CX727_MY2021_Rx" SG_ 126 StePinAn_No_Cs 1;
BA_ "U_P702_MY2021_Rx" SG_ 126 StePinAn_No_Cs 1;
BA_ "U_T6_MCA_MY2020_Rx" SG_ 126 StePinAn_No_Cs 1;
BA_ "U_CD542_MY2021_Rx" SG_ 126 StePinAn_No_Cs 1;
BA_ "U_U55X_MY2022_Rx" SG_ 126 StePinAn_No_Cs 1;
BA_ "U_CD764_MY2022_Rx" SG_ 126 StePinAn_No_Cs 1;
BA_ "U_CX727_MY2021_Tx" SG_ 126 StePinAn_No_Cs 1;
BA_ "U_P702_MY2021_Tx" SG_ 126 StePinAn_No_Cs 1;
BA_ "U_T6_MCA_MY2020_Tx" SG_ 126 StePinAn_No_Cs 1;
BA_ "U_CD542_MY2021_Tx" SG_ 126 StePinAn_No_Cs 1;
BA_ "U_U55X_MY2022_Tx" SG_ 126 StePinAn_No_Cs 1;
BA_ "U_CD764_MY2022_Tx" SG_ 126 StePinAn_No_Cs 1;
BA_ "MetaData" SG_ 126 StePinAn_No_Cnt 1;
BA_ "U_CX727_MY2021_Rx" SG_ 126 StePinAn_No_Cnt 1;
BA_ "U_P702_MY2021_Rx" SG_ 126 StePinAn_No_Cnt 1;
BA_ "U_T6_MCA_MY2020_Rx" SG_ 126 StePinAn_No_Cnt 1;
BA_ "U_CD542_MY2021_Rx" SG_ 126 StePinAn_No_Cnt 1;
BA_ "U_U55X_MY2022_Rx" SG_ 126 StePinAn_No_Cnt 1;
BA_ "U_CD764_MY2022_Rx" SG_ 126 StePinAn_No_Cnt 1;
BA_ "U_CX727_MY2021_Tx" SG_ 126 StePinAn_No_Cnt 1;
BA_ "U_P702_MY2021_Tx" SG_ 126 StePinAn_No_Cnt 1;
BA_ "U_T6_MCA_MY2020_Tx" SG_ 126 StePinAn_No_Cnt 1;
BA_ "U_CD542_MY2021_Tx" SG_ 126 StePinAn_No_Cnt 1;
BA_ "U_U55X_MY2022_Tx" SG_ 126 StePinAn_No_Cnt 1;
BA_ "U_CD764_MY2022_Tx" SG_ 126 StePinAn_No_Cnt 1;
BA_ "GenSigStartValueInteger" SG_ 1430 ABS_GWOnBoardTester 255;
BA_ "ContentDependant" SG_ 1430 ABS_GWOnBoardTester 1;
BA_ "GenSigStartValue" SG_ 1430 ABS_GWOnBoardTester 255;
BA_ "U_CX727_MY2021_Tx" SG_ 1430 ABS_GWOnBoardTester 1;
BA_ "U_P702_MY2021_Tx" SG_ 1430 ABS_GWOnBoardTester 1;
BA_ "U_T6_MCA_MY2020_Tx" SG_ 1430 ABS_GWOnBoardTester 1;
BA_ "U_CD542_MY2021_Tx" SG_ 1430 ABS_GWOnBoardTester 1;
BA_ "U_U55X_MY2022_Tx" SG_ 1430 ABS_GWOnBoardTester 1;
BA_ "U_CD764_MY2022_Tx" SG_ 1430 ABS_GWOnBoardTester 1;
BA_ "GenSigStartValueInteger" SG_ 1430 ABS_GWNMProxy 255;
BA_ "ContentDependant" SG_ 1430 ABS_GWNMProxy 1;
BA_ "GenSigStartValue" SG_ 1430 ABS_GWNMProxy 255;
BA_ "U_CX727_MY2021_Tx" SG_ 1430 ABS_GWNMProxy 1;
BA_ "U_P702_MY2021_Tx" SG_ 1430 ABS_GWNMProxy 1;
BA_ "U_T6_MCA_MY2020_Tx" SG_ 1430 ABS_GWNMProxy 1;
BA_ "U_CD542_MY2021_Tx" SG_ 1430 ABS_GWNMProxy 1;
BA_ "U_U55X_MY2022_Tx" SG_ 1430 ABS_GWNMProxy 1;
BA_ "U_CD764_MY2022_Tx" SG_ 1430 ABS_GWNMProxy 1;
BA_ "GenSigStartValueInteger" SG_ 1430 ABS_AutoSarNMReserved4 255;
BA_ "ContentDependant" SG_ 1430 ABS_AutoSarNMReserved4 1;
BA_ "GenSigStartValue" SG_ 1430 ABS_AutoSarNMReserved4 255;
BA_ "U_CX727_MY2021_Tx" SG_ 1430 ABS_AutoSarNMReserved4 1;
BA_ "U_P702_MY2021_Tx" SG_ 1430 ABS_AutoSarNMReserved4 1;
BA_ "U_T6_MCA_MY2020_Tx" SG_ 1430 ABS_AutoSarNMReserved4 1;
BA_ "U_CD542_MY2021_Tx" SG_ 1430 ABS_AutoSarNMReserved4 1;
BA_ "U_U55X_MY2022_Tx" SG_ 1430 ABS_AutoSarNMReserved4 1;
BA_ "U_CD764_MY2022_Tx" SG_ 1430 ABS_AutoSarNMReserved4 1;
BA_ "GenSigStartValueInteger" SG_ 1430 ABS_AutoSarNMReserved3 255;
BA_ "ContentDependant" SG_ 1430 ABS_AutoSarNMReserved3 1;
BA_ "GenSigStartValue" SG_ 1430 ABS_AutoSarNMReserved3 255;
BA_ "U_CX727_MY2021_Tx" SG_ 1430 ABS_AutoSarNMReserved3 1;
BA_ "U_P702_MY2021_Tx" SG_ 1430 ABS_AutoSarNMReserved3 1;
BA_ "U_T6_MCA_MY2020_Tx" SG_ 1430 ABS_AutoSarNMReserved3 1;
BA_ "U_CD542_MY2021_Tx" SG_ 1430 ABS_AutoSarNMReserved3 1;
BA_ "U_U55X_MY2022_Tx" SG_ 1430 ABS_AutoSarNMReserved3 1;
BA_ "U_CD764_MY2022_Tx" SG_ 1430 ABS_AutoSarNMReserved3 1;
BA_ "GenSigStartValueInteger" SG_ 1430 ABS_AutoSarNMReserved2 255;
BA_ "ContentDependant" SG_ 1430 ABS_AutoSarNMReserved2 1;
BA_ "GenSigStartValue" SG_ 1430 ABS_AutoSarNMReserved2 255;
BA_ "U_CX727_MY2021_Tx" SG_ 1430 ABS_AutoSarNMReserved2 1;
BA_ "U_P702_MY2021_Tx" SG_ 1430 ABS_AutoSarNMReserved2 1;
BA_ "U_T6_MCA_MY2020_Tx" SG_ 1430 ABS_AutoSarNMReserved2 1;
BA_ "U_CD542_MY2021_Tx" SG_ 1430 ABS_AutoSarNMReserved2 1;
BA_ "U_U55X_MY2022_Tx" SG_ 1430 ABS_AutoSarNMReserved2 1;
BA_ "U_CD764_MY2022_Tx" SG_ 1430 ABS_AutoSarNMReserved2 1;
BA_ "GenSigStartValueInteger" SG_ 1430 ABS_AutoSarNMReserved1 255;
BA_ "ContentDependant" SG_ 1430 ABS_AutoSarNMReserved1 1;
BA_ "GenSigStartValue" SG_ 1430 ABS_AutoSarNMReserved1 255;
BA_ "U_CX727_MY2021_Tx" SG_ 1430 ABS_AutoSarNMReserved1 1;
BA_ "U_P702_MY2021_Tx" SG_ 1430 ABS_AutoSarNMReserved1 1;
BA_ "U_T6_MCA_MY2020_Tx" SG_ 1430 ABS_AutoSarNMReserved1 1;
BA_ "U_CD542_MY2021_Tx" SG_ 1430 ABS_AutoSarNMReserved1 1;
BA_ "U_U55X_MY2022_Tx" SG_ 1430 ABS_AutoSarNMReserved1 1;
BA_ "U_CD764_MY2022_Tx" SG_ 1430 ABS_AutoSarNMReserved1 1;
BA_ "GenSigStartValueInteger" SG_ 1430 ABS_AutoSarNMNodeId 150;
BA_ "ContentDependant" SG_ 1430 ABS_AutoSarNMNodeId 1;
BA_ "GenSigStartValue" SG_ 1430 ABS_AutoSarNMNodeId 150;
BA_ "U_CX727_MY2021_Tx" SG_ 1430 ABS_AutoSarNMNodeId 1;
BA_ "U_P702_MY2021_Tx" SG_ 1430 ABS_AutoSarNMNodeId 1;
BA_ "U_T6_MCA_MY2020_Tx" SG_ 1430 ABS_AutoSarNMNodeId 1;
BA_ "U_CD542_MY2021_Tx" SG_ 1430 ABS_AutoSarNMNodeId 1;
BA_ "U_U55X_MY2022_Tx" SG_ 1430 ABS_AutoSarNMNodeId 1;
BA_ "U_CD764_MY2022_Tx" SG_ 1430 ABS_AutoSarNMNodeId 1;
BA_ "ContentDependant" SG_ 1430 ABS_AutoSarNMControl 1;
BA_ "U_CX727_MY2021_Tx" SG_ 1430 ABS_AutoSarNMControl 1;
BA_ "U_P702_MY2021_Tx" SG_ 1430 ABS_AutoSarNMControl 1;
BA_ "U_T6_MCA_MY2020_Tx" SG_ 1430 ABS_AutoSarNMControl 1;
BA_ "U_CD542_MY2021_Tx" SG_ 1430 ABS_AutoSarNMControl 1;
BA_ "U_U55X_MY2022_Tx" SG_ 1430 ABS_AutoSarNMControl 1;
BA_ "U_CD764_MY2022_Tx" SG_ 1430 ABS_AutoSarNMControl 1;
BA_ "GenSigStartValueInteger" SG_ 1200 HsaTrnAout_Tq_Rq 32768;
BA_ "U_CX727_MY2021_Tx" SG_ 1200 HsaTrnAout_Tq_Rq 1;
BA_ "U_P702_MY2021_Tx" SG_ 1200 HsaTrnAout_Tq_Rq 1;
BA_ "U_T6_MCA_MY2020_Tx" SG_ 1200 HsaTrnAout_Tq_Rq 1;
BA_ "U_CD542_MY2021_Tx" SG_ 1200 HsaTrnAout_Tq_Rq 1;
BA_ "U_U55X_MY2022_Tx" SG_ 1200 HsaTrnAout_Tq_Rq 1;
BA_ "U_CD764_MY2022_Tx" SG_ 1200 HsaTrnAout_Tq_Rq 1;
BA_ "GenSigStartValueInteger" SG_ 1200 BrkBstrVac_P_Actl 127;
BA_ "GenSigStartValue" SG_ 1200 BrkBstrVac_P_Actl 127;
BA_ "U_CX727_MY2021_Rx" SG_ 1200 BrkBstrVac_P_Actl 1;
BA_ "U_P702_MY2021_Rx" SG_ 1200 BrkBstrVac_P_Actl 1;
BA_ "U_T6_MCA_MY2020_Rx" SG_ 1200 BrkBstrVac_P_Actl 1;
BA_ "U_CD542_MY2021_Rx" SG_ 1200 BrkBstrVac_P_Actl 1;
BA_ "U_U55X_MY2022_Rx" SG_ 1200 BrkBstrVac_P_Actl 1;
BA_ "U_CD764_MY2022_Rx" SG_ 1200 BrkBstrVac_P_Actl 1;
BA_ "U_CX727_MY2021_Tx" SG_ 1200 BrkBstrVac_P_Actl 1;
BA_ "U_P702_MY2021_Tx" SG_ 1200 BrkBstrVac_P_Actl 1;
BA_ "U_T6_MCA_MY2020_Tx" SG_ 1200 BrkBstrVac_P_Actl 1;
BA_ "U_CD542_MY2021_Tx" SG_ 1200 BrkBstrVac_P_Actl 1;
BA_ "U_U55X_MY2022_Tx" SG_ 1200 BrkBstrVac_P_Actl 1;
BA_ "U_CD764_MY2022_Tx" SG_ 1200 BrkBstrVac_P_Actl 1;
BA_ "GenSigStartValueInteger" SG_ 1200 YawStabilityIndex 256;
BA_ "U_CX727_MY2021_Rx" SG_ 1200 YawStabilityIndex 1;
BA_ "U_P702_MY2021_Rx" SG_ 1200 YawStabilityIndex 1;
BA_ "U_T6_MCA_MY2020_Rx" SG_ 1200 YawStabilityIndex 1;
BA_ "U_CD542_MY2021_Rx" SG_ 1200 YawStabilityIndex 1;
BA_ "U_U55X_MY2022_Rx" SG_ 1200 YawStabilityIndex 1;
BA_ "U_CD764_MY2022_Rx" SG_ 1200 YawStabilityIndex 1;
BA_ "U_CX727_MY2021_Tx" SG_ 1200 YawStabilityIndex 1;
BA_ "U_P702_MY2021_Tx" SG_ 1200 YawStabilityIndex 1;
BA_ "U_T6_MCA_MY2020_Tx" SG_ 1200 YawStabilityIndex 1;
BA_ "U_CD542_MY2021_Tx" SG_ 1200 YawStabilityIndex 1;
BA_ "U_U55X_MY2022_Tx" SG_ 1200 YawStabilityIndex 1;
BA_ "U_CD764_MY2022_Tx" SG_ 1200 YawStabilityIndex 1;
BA_ "U_CX727_MY2021_Rx" SG_ 1200 BrkTot_Tq_RqDrv 1;
BA_ "U_P702_MY2021_Rx" SG_ 1200 BrkTot_Tq_RqDrv 1;
BA_ "U_T6_MCA_MY2020_Rx" SG_ 1200 BrkTot_Tq_RqDrv 1;
BA_ "U_CD542_MY2021_Rx" SG_ 1200 BrkTot_Tq_RqDrv 1;
BA_ "U_U55X_MY2022_Rx" SG_ 1200 BrkTot_Tq_RqDrv 1;
BA_ "U_CD764_MY2022_Rx" SG_ 1200 BrkTot_Tq_RqDrv 1;
BA_ "U_CX727_MY2021_Tx" SG_ 1200 BrkTot_Tq_RqDrv 1;
BA_ "U_P702_MY2021_Tx" SG_ 1200 BrkTot_Tq_RqDrv 1;
BA_ "U_T6_MCA_MY2020_Tx" SG_ 1200 BrkTot_Tq_RqDrv 1;
BA_ "U_CD542_MY2021_Tx" SG_ 1200 BrkTot_Tq_RqDrv 1;
BA_ "U_U55X_MY2022_Tx" SG_ 1200 BrkTot_Tq_RqDrv 1;
BA_ "U_CD764_MY2022_Tx" SG_ 1200 BrkTot_Tq_RqDrv 1;
BA_ "MetaData" SG_ 1200 BrkTotTqRqDrv_No_Cnt 1;
BA_ "U_CX727_MY2021_Rx" SG_ 1200 BrkTotTqRqDrv_No_Cnt 1;
BA_ "U_P702_MY2021_Rx" SG_ 1200 BrkTotTqRqDrv_No_Cnt 1;
BA_ "U_T6_MCA_MY2020_Rx" SG_ 1200 BrkTotTqRqDrv_No_Cnt 1;
BA_ "U_CD542_MY2021_Rx" SG_ 1200 BrkTotTqRqDrv_No_Cnt 1;
BA_ "U_U55X_MY2022_Rx" SG_ 1200 BrkTotTqRqDrv_No_Cnt 1;
BA_ "U_CD764_MY2022_Rx" SG_ 1200 BrkTotTqRqDrv_No_Cnt 1;
BA_ "U_CX727_MY2021_Tx" SG_ 1200 BrkTotTqRqDrv_No_Cnt 1;
BA_ "U_P702_MY2021_Tx" SG_ 1200 BrkTotTqRqDrv_No_Cnt 1;
BA_ "U_T6_MCA_MY2020_Tx" SG_ 1200 BrkTotTqRqDrv_No_Cnt 1;
BA_ "U_CD542_MY2021_Tx" SG_ 1200 BrkTotTqRqDrv_No_Cnt 1;
BA_ "U_U55X_MY2022_Tx" SG_ 1200 BrkTotTqRqDrv_No_Cnt 1;
BA_ "U_CD764_MY2022_Tx" SG_ 1200 BrkTotTqRqDrv_No_Cnt 1;
BA_ "MetaData" SG_ 1200 BrkTotTqRqDrv_No_Cs 1;
BA_ "U_CX727_MY2021_Rx" SG_ 1200 BrkTotTqRqDrv_No_Cs 1;
BA_ "U_P702_MY2021_Rx" SG_ 1200 BrkTotTqRqDrv_No_Cs 1;
BA_ "U_T6_MCA_MY2020_Rx" SG_ 1200 BrkTotTqRqDrv_No_Cs 1;
BA_ "U_CD542_MY2021_Rx" SG_ 1200 BrkTotTqRqDrv_No_Cs 1;
BA_ "U_U55X_MY2022_Rx" SG_ 1200 BrkTotTqRqDrv_No_Cs 1;
BA_ "U_CD764_MY2022_Rx" SG_ 1200 BrkTotTqRqDrv_No_Cs 1;
BA_ "U_CX727_MY2021_Tx" SG_ 1200 BrkTotTqRqDrv_No_Cs 1;
BA_ "U_P702_MY2021_Tx" SG_ 1200 BrkTotTqRqDrv_No_Cs 1;
BA_ "U_T6_MCA_MY2020_Tx" SG_ 1200 BrkTotTqRqDrv_No_Cs 1;
BA_ "U_CD542_MY2021_Tx" SG_ 1200 BrkTotTqRqDrv_No_Cs 1;
BA_ "U_U55X_MY2022_Tx" SG_ 1200 BrkTotTqRqDrv_No_Cs 1;
BA_ "U_CD764_MY2022_Tx" SG_ 1200 BrkTotTqRqDrv_No_Cs 1;
BA_ "U_T6_MCA_MY2020_Rx" SG_ 1200 BrkHold_D_Stat 1;
BA_ "U_CD542_MY2021_Rx" SG_ 1200 BrkHold_D_Stat 1;
BA_ "U_U55X_MY2022_Rx" SG_ 1200 BrkHold_D_Stat 1;
BA_ "U_CD764_MY2022_Rx" SG_ 1200 BrkHold_D_Stat 1;
BA_ "U_T6_MCA_MY2020_Tx" SG_ 1200 BrkHold_D_Stat 1;
BA_ "U_CD542_MY2021_Tx" SG_ 1200 BrkHold_D_Stat 1;
BA_ "U_U55X_MY2022_Tx" SG_ 1200 BrkHold_D_Stat 1;
BA_ "U_CD764_MY2022_Tx" SG_ 1200 BrkHold_D_Stat 1;
BA_ "GenSigSendType" SG_ 1102 SelDrvMdePos12_D_Stat 3;
BA_ "GenSigStartValueInteger" SG_ 1102 SelDrvMdePos12_D_Stat 31;
BA_ "GenSigStartValue" SG_ 1102 SelDrvMdePos12_D_Stat 31;
BA_ "U_CX727_MY2021_Tx" SG_ 1102 SelDrvMdePos12_D_Stat 1;
BA_ "U_P702_MY2021_Tx" SG_ 1102 SelDrvMdePos12_D_Stat 1;
BA_ "U_T6_MCA_MY2020_Tx" SG_ 1102 SelDrvMdePos12_D_Stat 1;
BA_ "U_CD542_MY2021_Tx" SG_ 1102 SelDrvMdePos12_D_Stat 1;
BA_ "U_U55X_MY2022_Tx" SG_ 1102 SelDrvMdePos12_D_Stat 1;
BA_ "U_CD764_MY2022_Tx" SG_ 1102 SelDrvMdePos12_D_Stat 1;
BA_ "GenSigSendType" SG_ 1102 SelDrvMdePos11_D_Stat 3;
BA_ "GenSigStartValueInteger" SG_ 1102 SelDrvMdePos11_D_Stat 31;
BA_ "GenSigStartValue" SG_ 1102 SelDrvMdePos11_D_Stat 31;
BA_ "U_CX727_MY2021_Tx" SG_ 1102 SelDrvMdePos11_D_Stat 1;
BA_ "U_P702_MY2021_Tx" SG_ 1102 SelDrvMdePos11_D_Stat 1;
BA_ "U_T6_MCA_MY2020_Tx" SG_ 1102 SelDrvMdePos11_D_Stat 1;
BA_ "U_CD542_MY2021_Tx" SG_ 1102 SelDrvMdePos11_D_Stat 1;
BA_ "U_U55X_MY2022_Tx" SG_ 1102 SelDrvMdePos11_D_Stat 1;
BA_ "U_CD764_MY2022_Tx" SG_ 1102 SelDrvMdePos11_D_Stat 1;
BA_ "GenSigSendType" SG_ 1102 SelDrvMdePos10_D_Stat 3;
BA_ "GenSigStartValueInteger" SG_ 1102 SelDrvMdePos10_D_Stat 31;
BA_ "GenSigStartValue" SG_ 1102 SelDrvMdePos10_D_Stat 31;
BA_ "U_CX727_MY2021_Tx" SG_ 1102 SelDrvMdePos10_D_Stat 1;
BA_ "U_P702_MY2021_Tx" SG_ 1102 SelDrvMdePos10_D_Stat 1;
BA_ "U_T6_MCA_MY2020_Tx" SG_ 1102 SelDrvMdePos10_D_Stat 1;
BA_ "U_CD542_MY2021_Tx" SG_ 1102 SelDrvMdePos10_D_Stat 1;
BA_ "U_U55X_MY2022_Tx" SG_ 1102 SelDrvMdePos10_D_Stat 1;
BA_ "U_CD764_MY2022_Tx" SG_ 1102 SelDrvMdePos10_D_Stat 1;
BA_ "GenSigSendType" SG_ 1102 SelDrvMdePos09_D_Stat 3;
BA_ "GenSigStartValueInteger" SG_ 1102 SelDrvMdePos09_D_Stat 31;
BA_ "GenSigStartValue" SG_ 1102 SelDrvMdePos09_D_Stat 31;
BA_ "U_CX727_MY2021_Tx" SG_ 1102 SelDrvMdePos09_D_Stat 1;
BA_ "U_P702_MY2021_Tx" SG_ 1102 SelDrvMdePos09_D_Stat 1;
BA_ "U_T6_MCA_MY2020_Tx" SG_ 1102 SelDrvMdePos09_D_Stat 1;
BA_ "U_CD542_MY2021_Tx" SG_ 1102 SelDrvMdePos09_D_Stat 1;
BA_ "U_U55X_MY2022_Tx" SG_ 1102 SelDrvMdePos09_D_Stat 1;
BA_ "U_CD764_MY2022_Tx" SG_ 1102 SelDrvMdePos09_D_Stat 1;
BA_ "GenSigSendType" SG_ 1102 SelDrvMdePos08_D_Stat 3;
BA_ "GenSigStartValueInteger" SG_ 1102 SelDrvMdePos08_D_Stat 31;
BA_ "GenSigStartValue" SG_ 1102 SelDrvMdePos08_D_Stat 31;
BA_ "U_CX727_MY2021_Tx" SG_ 1102 SelDrvMdePos08_D_Stat 1;
BA_ "U_P702_MY2021_Tx" SG_ 1102 SelDrvMdePos08_D_Stat 1;
BA_ "U_T6_MCA_MY2020_Tx" SG_ 1102 SelDrvMdePos08_D_Stat 1;
BA_ "U_CD542_MY2021_Tx" SG_ 1102 SelDrvMdePos08_D_Stat 1;
BA_ "U_U55X_MY2022_Tx" SG_ 1102 SelDrvMdePos08_D_Stat 1;
BA_ "U_CD764_MY2022_Tx" SG_ 1102 SelDrvMdePos08_D_Stat 1;
BA_ "GenSigSendType" SG_ 1102 SelDrvMdePos07_D_Stat 3;
BA_ "GenSigStartValueInteger" SG_ 1102 SelDrvMdePos07_D_Stat 31;
BA_ "GenSigStartValue" SG_ 1102 SelDrvMdePos07_D_Stat 31;
BA_ "U_CX727_MY2021_Tx" SG_ 1102 SelDrvMdePos07_D_Stat 1;
BA_ "U_P702_MY2021_Tx" SG_ 1102 SelDrvMdePos07_D_Stat 1;
BA_ "U_T6_MCA_MY2020_Tx" SG_ 1102 SelDrvMdePos07_D_Stat 1;
BA_ "U_CD542_MY2021_Tx" SG_ 1102 SelDrvMdePos07_D_Stat 1;
BA_ "U_U55X_MY2022_Tx" SG_ 1102 SelDrvMdePos07_D_Stat 1;
BA_ "U_CD764_MY2022_Tx" SG_ 1102 SelDrvMdePos07_D_Stat 1;
BA_ "GenSigSendType" SG_ 1102 SelDrvMdePos06_D_Stat 3;
BA_ "GenSigStartValueInteger" SG_ 1102 SelDrvMdePos06_D_Stat 31;
BA_ "GenSigStartValue" SG_ 1102 SelDrvMdePos06_D_Stat 31;
BA_ "U_CX727_MY2021_Tx" SG_ 1102 SelDrvMdePos06_D_Stat 1;
BA_ "U_P702_MY2021_Tx" SG_ 1102 SelDrvMdePos06_D_Stat 1;
BA_ "U_T6_MCA_MY2020_Tx" SG_ 1102 SelDrvMdePos06_D_Stat 1;
BA_ "U_CD542_MY2021_Tx" SG_ 1102 SelDrvMdePos06_D_Stat 1;
BA_ "U_U55X_MY2022_Tx" SG_ 1102 SelDrvMdePos06_D_Stat 1;
BA_ "U_CD764_MY2022_Tx" SG_ 1102 SelDrvMdePos06_D_Stat 1;
BA_ "GenSigSendType" SG_ 1102 SelDrvMdePos05_D_Stat 3;
BA_ "GenSigStartValueInteger" SG_ 1102 SelDrvMdePos05_D_Stat 31;
BA_ "GenSigStartValue" SG_ 1102 SelDrvMdePos05_D_Stat 31;
BA_ "U_CX727_MY2021_Tx" SG_ 1102 SelDrvMdePos05_D_Stat 1;
BA_ "U_P702_MY2021_Tx" SG_ 1102 SelDrvMdePos05_D_Stat 1;
BA_ "U_T6_MCA_MY2020_Tx" SG_ 1102 SelDrvMdePos05_D_Stat 1;
BA_ "U_CD542_MY2021_Tx" SG_ 1102 SelDrvMdePos05_D_Stat 1;
BA_ "U_U55X_MY2022_Tx" SG_ 1102 SelDrvMdePos05_D_Stat 1;
BA_ "U_CD764_MY2022_Tx" SG_ 1102 SelDrvMdePos05_D_Stat 1;
BA_ "GenSigSendType" SG_ 1102 SelDrvMdePos04_D_Stat 3;
BA_ "GenSigStartValueInteger" SG_ 1102 SelDrvMdePos04_D_Stat 31;
BA_ "GenSigStartValue" SG_ 1102 SelDrvMdePos04_D_Stat 31;
BA_ "U_CX727_MY2021_Tx" SG_ 1102 SelDrvMdePos04_D_Stat 1;
BA_ "U_P702_MY2021_Tx" SG_ 1102 SelDrvMdePos04_D_Stat 1;
BA_ "U_T6_MCA_MY2020_Tx" SG_ 1102 SelDrvMdePos04_D_Stat 1;
BA_ "U_CD542_MY2021_Tx" SG_ 1102 SelDrvMdePos04_D_Stat 1;
BA_ "U_U55X_MY2022_Tx" SG_ 1102 SelDrvMdePos04_D_Stat 1;
BA_ "U_CD764_MY2022_Tx" SG_ 1102 SelDrvMdePos04_D_Stat 1;
BA_ "GenSigSendType" SG_ 1102 SelDrvMdePos03_D_Stat 3;
BA_ "GenSigStartValueInteger" SG_ 1102 SelDrvMdePos03_D_Stat 31;
BA_ "GenSigStartValue" SG_ 1102 SelDrvMdePos03_D_Stat 31;
BA_ "U_CX727_MY2021_Tx" SG_ 1102 SelDrvMdePos03_D_Stat 1;
BA_ "U_P702_MY2021_Tx" SG_ 1102 SelDrvMdePos03_D_Stat 1;
BA_ "U_T6_MCA_MY2020_Tx" SG_ 1102 SelDrvMdePos03_D_Stat 1;
BA_ "U_CD542_MY2021_Tx" SG_ 1102 SelDrvMdePos03_D_Stat 1;
BA_ "U_U55X_MY2022_Tx" SG_ 1102 SelDrvMdePos03_D_Stat 1;
BA_ "U_CD764_MY2022_Tx" SG_ 1102 SelDrvMdePos03_D_Stat 1;
BA_ "GenSigSendType" SG_ 1102 SelDrvMdePos02_D_Stat 3;
BA_ "GenSigStartValueInteger" SG_ 1102 SelDrvMdePos02_D_Stat 31;
BA_ "GenSigStartValue" SG_ 1102 SelDrvMdePos02_D_Stat 31;
BA_ "U_CX727_MY2021_Tx" SG_ 1102 SelDrvMdePos02_D_Stat 1;
BA_ "U_P702_MY2021_Tx" SG_ 1102 SelDrvMdePos02_D_Stat 1;
BA_ "U_T6_MCA_MY2020_Tx" SG_ 1102 SelDrvMdePos02_D_Stat 1;
BA_ "U_CD542_MY2021_Tx" SG_ 1102 SelDrvMdePos02_D_Stat 1;
BA_ "U_U55X_MY2022_Tx" SG_ 1102 SelDrvMdePos02_D_Stat 1;
BA_ "U_CD764_MY2022_Tx" SG_ 1102 SelDrvMdePos02_D_Stat 1;
BA_ "GenSigSendType" SG_ 1102 SelDrvMdePos01_D_Stat 3;
BA_ "GenSigStartValueInteger" SG_ 1102 SelDrvMdePos01_D_Stat 31;
BA_ "GenSigStartValue" SG_ 1102 SelDrvMdePos01_D_Stat 31;
BA_ "U_CX727_MY2021_Tx" SG_ 1102 SelDrvMdePos01_D_Stat 1;
BA_ "U_P702_MY2021_Tx" SG_ 1102 SelDrvMdePos01_D_Stat 1;
BA_ "U_T6_MCA_MY2020_Tx" SG_ 1102 SelDrvMdePos01_D_Stat 1;
BA_ "U_CD542_MY2021_Tx" SG_ 1102 SelDrvMdePos01_D_Stat 1;
BA_ "U_U55X_MY2022_Tx" SG_ 1102 SelDrvMdePos01_D_Stat 1;
BA_ "U_CD764_MY2022_Tx" SG_ 1102 SelDrvMdePos01_D_Stat 1;
BA_ "GenSigStartValue" SG_ 1056 VehVActlBrk_No_Corr 254;
BA_ "GenSigSendType" SG_ 1056 SelDrvMdePos12_B_Avail 3;
BA_ "U_CX727_MY2021_Tx" SG_ 1056 SelDrvMdePos12_B_Avail 1;
BA_ "U_P702_MY2021_Tx" SG_ 1056 SelDrvMdePos12_B_Avail 1;
BA_ "U_T6_MCA_MY2020_Tx" SG_ 1056 SelDrvMdePos12_B_Avail 1;
BA_ "U_CD542_MY2021_Tx" SG_ 1056 SelDrvMdePos12_B_Avail 1;
BA_ "U_U55X_MY2022_Tx" SG_ 1056 SelDrvMdePos12_B_Avail 1;
BA_ "U_CD764_MY2022_Tx" SG_ 1056 SelDrvMdePos12_B_Avail 1;
BA_ "GenSigSendType" SG_ 1056 SelDrvMdePos11_B_Avail 3;
BA_ "U_CX727_MY2021_Tx" SG_ 1056 SelDrvMdePos11_B_Avail 1;
BA_ "U_P702_MY2021_Tx" SG_ 1056 SelDrvMdePos11_B_Avail 1;
BA_ "U_T6_MCA_MY2020_Tx" SG_ 1056 SelDrvMdePos11_B_Avail 1;
BA_ "U_CD542_MY2021_Tx" SG_ 1056 SelDrvMdePos11_B_Avail 1;
BA_ "U_U55X_MY2022_Tx" SG_ 1056 SelDrvMdePos11_B_Avail 1;
BA_ "U_CD764_MY2022_Tx" SG_ 1056 SelDrvMdePos11_B_Avail 1;
BA_ "GenSigSendType" SG_ 1056 SelDrvMdePos10_B_Avail 3;
BA_ "U_CX727_MY2021_Tx" SG_ 1056 SelDrvMdePos10_B_Avail 1;
BA_ "U_P702_MY2021_Tx" SG_ 1056 SelDrvMdePos10_B_Avail 1;
BA_ "U_T6_MCA_MY2020_Tx" SG_ 1056 SelDrvMdePos10_B_Avail 1;
BA_ "U_CD542_MY2021_Tx" SG_ 1056 SelDrvMdePos10_B_Avail 1;
BA_ "U_U55X_MY2022_Tx" SG_ 1056 SelDrvMdePos10_B_Avail 1;
BA_ "U_CD764_MY2022_Tx" SG_ 1056 SelDrvMdePos10_B_Avail 1;
BA_ "GenSigSendType" SG_ 1056 SelDrvMdePos09_B_Avail 3;
BA_ "U_CX727_MY2021_Tx" SG_ 1056 SelDrvMdePos09_B_Avail 1;
BA_ "U_P702_MY2021_Tx" SG_ 1056 SelDrvMdePos09_B_Avail 1;
BA_ "U_T6_MCA_MY2020_Tx" SG_ 1056 SelDrvMdePos09_B_Avail 1;
BA_ "U_CD542_MY2021_Tx" SG_ 1056 SelDrvMdePos09_B_Avail 1;
BA_ "U_U55X_MY2022_Tx" SG_ 1056 SelDrvMdePos09_B_Avail 1;
BA_ "U_CD764_MY2022_Tx" SG_ 1056 SelDrvMdePos09_B_Avail 1;
BA_ "GenSigSendType" SG_ 1056 SelDrvMdePos08_B_Avail 3;
BA_ "U_CX727_MY2021_Tx" SG_ 1056 SelDrvMdePos08_B_Avail 1;
BA_ "U_P702_MY2021_Tx" SG_ 1056 SelDrvMdePos08_B_Avail 1;
BA_ "U_T6_MCA_MY2020_Tx" SG_ 1056 SelDrvMdePos08_B_Avail 1;
BA_ "U_CD542_MY2021_Tx" SG_ 1056 SelDrvMdePos08_B_Avail 1;
BA_ "U_U55X_MY2022_Tx" SG_ 1056 SelDrvMdePos08_B_Avail 1;
BA_ "U_CD764_MY2022_Tx" SG_ 1056 SelDrvMdePos08_B_Avail 1;
BA_ "GenSigSendType" SG_ 1056 SelDrvMdePos07_B_Avail 3;
BA_ "U_CX727_MY2021_Tx" SG_ 1056 SelDrvMdePos07_B_Avail 1;
BA_ "U_P702_MY2021_Tx" SG_ 1056 SelDrvMdePos07_B_Avail 1;
BA_ "U_T6_MCA_MY2020_Tx" SG_ 1056 SelDrvMdePos07_B_Avail 1;
BA_ "U_CD542_MY2021_Tx" SG_ 1056 SelDrvMdePos07_B_Avail 1;
BA_ "U_U55X_MY2022_Tx" SG_ 1056 SelDrvMdePos07_B_Avail 1;
BA_ "U_CD764_MY2022_Tx" SG_ 1056 SelDrvMdePos07_B_Avail 1;
BA_ "GenSigSendType" SG_ 1056 SelDrvMdePos06_B_Avail 3;
BA_ "U_CX727_MY2021_Tx" SG_ 1056 SelDrvMdePos06_B_Avail 1;
BA_ "U_P702_MY2021_Tx" SG_ 1056 SelDrvMdePos06_B_Avail 1;
BA_ "U_T6_MCA_MY2020_Tx" SG_ 1056 SelDrvMdePos06_B_Avail 1;
BA_ "U_CD542_MY2021_Tx" SG_ 1056 SelDrvMdePos06_B_Avail 1;
BA_ "U_U55X_MY2022_Tx" SG_ 1056 SelDrvMdePos06_B_Avail 1;
BA_ "U_CD764_MY2022_Tx" SG_ 1056 SelDrvMdePos06_B_Avail 1;
BA_ "GenSigSendType" SG_ 1056 SelDrvMdePos05_B_Avail 3;
BA_ "U_CX727_MY2021_Tx" SG_ 1056 SelDrvMdePos05_B_Avail 1;
BA_ "U_P702_MY2021_Tx" SG_ 1056 SelDrvMdePos05_B_Avail 1;
BA_ "U_T6_MCA_MY2020_Tx" SG_ 1056 SelDrvMdePos05_B_Avail 1;
BA_ "U_CD542_MY2021_Tx" SG_ 1056 SelDrvMdePos05_B_Avail 1;
BA_ "U_U55X_MY2022_Tx" SG_ 1056 SelDrvMdePos05_B_Avail 1;
BA_ "U_CD764_MY2022_Tx" SG_ 1056 SelDrvMdePos05_B_Avail 1;
BA_ "GenSigSendType" SG_ 1056 SelDrvMdePos04_B_Avail 3;
BA_ "U_CX727_MY2021_Tx" SG_ 1056 SelDrvMdePos04_B_Avail 1;
BA_ "U_P702_MY2021_Tx" SG_ 1056 SelDrvMdePos04_B_Avail 1;
BA_ "U_T6_MCA_MY2020_Tx" SG_ 1056 SelDrvMdePos04_B_Avail 1;
BA_ "U_CD542_MY2021_Tx" SG_ 1056 SelDrvMdePos04_B_Avail 1;
BA_ "U_U55X_MY2022_Tx" SG_ 1056 SelDrvMdePos04_B_Avail 1;
BA_ "U_CD764_MY2022_Tx" SG_ 1056 SelDrvMdePos04_B_Avail 1;
BA_ "GenSigSendType" SG_ 1056 SelDrvMdePos03_B_Avail 3;
BA_ "U_CX727_MY2021_Tx" SG_ 1056 SelDrvMdePos03_B_Avail 1;
BA_ "U_P702_MY2021_Tx" SG_ 1056 SelDrvMdePos03_B_Avail 1;
BA_ "U_T6_MCA_MY2020_Tx" SG_ 1056 SelDrvMdePos03_B_Avail 1;
BA_ "U_CD542_MY2021_Tx" SG_ 1056 SelDrvMdePos03_B_Avail 1;
BA_ "U_U55X_MY2022_Tx" SG_ 1056 SelDrvMdePos03_B_Avail 1;
BA_ "U_CD764_MY2022_Tx" SG_ 1056 SelDrvMdePos03_B_Avail 1;
BA_ "GenSigSendType" SG_ 1056 SelDrvMdePos02_B_Avail 3;
BA_ "U_CX727_MY2021_Tx" SG_ 1056 SelDrvMdePos02_B_Avail 1;
BA_ "U_P702_MY2021_Tx" SG_ 1056 SelDrvMdePos02_B_Avail 1;
BA_ "U_T6_MCA_MY2020_Tx" SG_ 1056 SelDrvMdePos02_B_Avail 1;
BA_ "U_CD542_MY2021_Tx" SG_ 1056 SelDrvMdePos02_B_Avail 1;
BA_ "U_U55X_MY2022_Tx" SG_ 1056 SelDrvMdePos02_B_Avail 1;
BA_ "U_CD764_MY2022_Tx" SG_ 1056 SelDrvMdePos02_B_Avail 1;
BA_ "GenSigSendType" SG_ 1056 SelDrvMdePos01_B_Avail 3;
BA_ "U_CX727_MY2021_Tx" SG_ 1056 SelDrvMdePos01_B_Avail 1;
BA_ "U_P702_MY2021_Tx" SG_ 1056 SelDrvMdePos01_B_Avail 1;
BA_ "U_T6_MCA_MY2020_Tx" SG_ 1056 SelDrvMdePos01_B_Avail 1;
BA_ "U_CD542_MY2021_Tx" SG_ 1056 SelDrvMdePos01_B_Avail 1;
BA_ "U_U55X_MY2022_Tx" SG_ 1056 SelDrvMdePos01_B_Avail 1;
BA_ "U_CD764_MY2022_Tx" SG_ 1056 SelDrvMdePos01_B_Avail 1;
BA_ "GenSigSendType" SG_ 1056 ActvDrvMde_D2_Stat 3;
BA_ "GenSigStartValueInteger" SG_ 1056 ActvDrvMde_D2_Stat 31;
BA_ "GenSigStartValue" SG_ 1056 ActvDrvMde_D2_Stat 31;
BA_ "U_T6_MCA_MY2020_Rx" SG_ 1056 ActvDrvMde_D2_Stat 1;
BA_ "ECGUsedRxSignal" SG_ 1056 ActvDrvMde_D2_Stat 1;
BA_ "U_CD542_MY2021_Rx" SG_ 1056 ActvDrvMde_D2_Stat 1;
BA_ "U_U55X_MY2022_Rx" SG_ 1056 ActvDrvMde_D2_Stat 1;
BA_ "U_CD764_MY2022_Rx" SG_ 1056 ActvDrvMde_D2_Stat 1;
BA_ "U_CX727_MY2021_Tx" SG_ 1056 ActvDrvMde_D2_Stat 1;
BA_ "U_P702_MY2021_Tx" SG_ 1056 ActvDrvMde_D2_Stat 1;
BA_ "U_T6_MCA_MY2020_Tx" SG_ 1056 ActvDrvMde_D2_Stat 1;
BA_ "U_CD542_MY2021_Tx" SG_ 1056 ActvDrvMde_D2_Stat 1;
BA_ "U_U55X_MY2022_Tx" SG_ 1056 ActvDrvMde_D2_Stat 1;
BA_ "U_CD764_MY2022_Tx" SG_ 1056 ActvDrvMde_D2_Stat 1;
BA_ "GenSigSendType" SG_ 1056 SelDrvMde_D2_Rq 3;
BA_ "GenSigStartValueInteger" SG_ 1056 SelDrvMde_D2_Rq 31;
BA_ "GenSigStartValue" SG_ 1056 SelDrvMde_D2_Rq 31;
BA_ "U_CX727_MY2021_Tx" SG_ 1056 SelDrvMde_D2_Rq 1;
BA_ "U_P702_MY2021_Tx" SG_ 1056 SelDrvMde_D2_Rq 1;
BA_ "U_T6_MCA_MY2020_Tx" SG_ 1056 SelDrvMde_D2_Rq 1;
BA_ "U_CD542_MY2021_Tx" SG_ 1056 SelDrvMde_D2_Rq 1;
BA_ "U_U55X_MY2022_Tx" SG_ 1056 SelDrvMde_D2_Rq 1;
BA_ "U_CD764_MY2022_Tx" SG_ 1056 SelDrvMde_D2_Rq 1;
BA_ "GenSigSendType" SG_ 1056 SelDrvMdePt_D_Rq 3;
BA_ "U_CX727_MY2021_Rx" SG_ 1056 SelDrvMdePt_D_Rq 1;
BA_ "U_P702_MY2021_Rx" SG_ 1056 SelDrvMdePt_D_Rq 1;
BA_ "U_T6_MCA_MY2020_Rx" SG_ 1056 SelDrvMdePt_D_Rq 1;
BA_ "U_CD542_MY2021_Rx" SG_ 1056 SelDrvMdePt_D_Rq 1;
BA_ "U_U55X_MY2022_Rx" SG_ 1056 SelDrvMdePt_D_Rq 1;
BA_ "U_CD764_MY2022_Rx" SG_ 1056 SelDrvMdePt_D_Rq 1;
BA_ "U_CX727_MY2021_Tx" SG_ 1056 SelDrvMdePt_D_Rq 1;
BA_ "U_P702_MY2021_Tx" SG_ 1056 SelDrvMdePt_D_Rq 1;
BA_ "U_T6_MCA_MY2020_Tx" SG_ 1056 SelDrvMdePt_D_Rq 1;
BA_ "U_CD542_MY2021_Tx" SG_ 1056 SelDrvMdePt_D_Rq 1;
BA_ "U_U55X_MY2022_Tx" SG_ 1056 SelDrvMdePt_D_Rq 1;
BA_ "U_CD764_MY2022_Tx" SG_ 1056 SelDrvMdePt_D_Rq 1;
BA_ "GenSigSendType" SG_ 1056 SelDrvMdeMsgTxt_D_Rq 3;
BA_ "U_CX727_MY2021_Tx" SG_ 1056 SelDrvMdeMsgTxt_D_Rq 1;
BA_ "U_P702_MY2021_Tx" SG_ 1056 SelDrvMdeMsgTxt_D_Rq 1;
BA_ "U_T6_MCA_MY2020_Tx" SG_ 1056 SelDrvMdeMsgTxt_D_Rq 1;
BA_ "U_CD542_MY2021_Tx" SG_ 1056 SelDrvMdeMsgTxt_D_Rq 1;
BA_ "U_U55X_MY2022_Tx" SG_ 1056 SelDrvMdeMsgTxt_D_Rq 1;
BA_ "U_CD764_MY2022_Tx" SG_ 1056 SelDrvMdeMsgTxt_D_Rq 1;
BA_ "GenSigSendType" SG_ 1056 SelDrvMde_D_Stat 3;
BA_ "U_CX727_MY2021_Tx" SG_ 1056 SelDrvMde_D_Stat 1;
BA_ "U_P702_MY2021_Tx" SG_ 1056 SelDrvMde_D_Stat 1;
BA_ "U_T6_MCA_MY2020_Tx" SG_ 1056 SelDrvMde_D_Stat 1;
BA_ "U_CD542_MY2021_Tx" SG_ 1056 SelDrvMde_D_Stat 1;
BA_ "U_U55X_MY2022_Tx" SG_ 1056 SelDrvMde_D_Stat 1;
BA_ "U_CD764_MY2022_Tx" SG_ 1056 SelDrvMde_D_Stat 1;
BA_ "GenSigSendType" SG_ 1056 AwdMde_D_RqBrk 3;
BA_ "GenSigStartValueInteger" SG_ 1056 AwdMde_D_RqBrk 5;
BA_ "GenSigStartValue" SG_ 1056 AwdMde_D_RqBrk 5;
BA_ "U_CX727_MY2021_Tx" SG_ 1056 AwdMde_D_RqBrk 1;
BA_ "U_P702_MY2021_Tx" SG_ 1056 AwdMde_D_RqBrk 1;
BA_ "U_T6_MCA_MY2020_Tx" SG_ 1056 AwdMde_D_RqBrk 1;
BA_ "U_U55X_MY2022_Tx" SG_ 1056 AwdMde_D_RqBrk 1;
BA_ "GenSigSendType" SG_ 1056 SelDrvMdeMsgTxt2_D_Rq 3;
BA_ "U_T6_MCA_MY2020_Tx" SG_ 1056 SelDrvMdeMsgTxt2_D_Rq 1;
BA_ "U_CD542_MY2021_Tx" SG_ 1056 SelDrvMdeMsgTxt2_D_Rq 1;
BA_ "U_U55X_MY2022_Tx" SG_ 1056 SelDrvMdeMsgTxt2_D_Rq 1;
BA_ "U_CD764_MY2022_Tx" SG_ 1056 SelDrvMdeMsgTxt2_D_Rq 1;
BA_ "GenSigSendType" SG_ 1056 SelDrvMdeHmi03_D_Rq 3;
BA_ "U_T6_MCA_MY2020_Tx" SG_ 1056 SelDrvMdeHmi03_D_Rq 1;
BA_ "U_CD542_MY2021_Tx" SG_ 1056 SelDrvMdeHmi03_D_Rq 1;
BA_ "U_U55X_MY2022_Tx" SG_ 1056 SelDrvMdeHmi03_D_Rq 1;
BA_ "U_CD764_MY2022_Tx" SG_ 1056 SelDrvMdeHmi03_D_Rq 1;
BA_ "GenSigSendType" SG_ 1054 RbaBrk_D_Stat 3;
BA_ "U_T6_MCA_MY2020_Rx" SG_ 1054 RbaBrk_D_Stat 1;
BA_ "U_CD542_MY2021_Rx" SG_ 1054 RbaBrk_D_Stat 1;
BA_ "U_U55X_MY2022_Rx" SG_ 1054 RbaBrk_D_Stat 1;
BA_ "U_CD764_MY2022_Rx" SG_ 1054 RbaBrk_D_Stat 1;
BA_ "U_CX727_MY2021_Tx" SG_ 1054 RbaBrk_D_Stat 1;
BA_ "U_P702_MY2021_Tx" SG_ 1054 RbaBrk_D_Stat 1;
BA_ "U_T6_MCA_MY2020_Tx" SG_ 1054 RbaBrk_D_Stat 1;
BA_ "U_CD542_MY2021_Tx" SG_ 1054 RbaBrk_D_Stat 1;
BA_ "U_U55X_MY2022_Tx" SG_ 1054 RbaBrk_D_Stat 1;
BA_ "U_CD764_MY2022_Tx" SG_ 1054 RbaBrk_D_Stat 1;
BA_ "GenSigSendType" SG_ 1054 SelDrvMdeChassis2_D_Rq 3;
BA_ "U_CX727_MY2021_Rx" SG_ 1054 SelDrvMdeChassis2_D_Rq 1;
BA_ "U_P702_MY2021_Rx" SG_ 1054 SelDrvMdeChassis2_D_Rq 1;
BA_ "U_T6_MCA_MY2020_Rx" SG_ 1054 SelDrvMdeChassis2_D_Rq 1;
BA_ "U_CD542_MY2021_Rx" SG_ 1054 SelDrvMdeChassis2_D_Rq 1;
BA_ "U_U55X_MY2022_Rx" SG_ 1054 SelDrvMdeChassis2_D_Rq 1;
BA_ "U_CD764_MY2022_Rx" SG_ 1054 SelDrvMdeChassis2_D_Rq 1;
BA_ "U_P702_MY2021_Tx" SG_ 1054 SelDrvMdeChassis2_D_Rq 1;
BA_ "U_T6_MCA_MY2020_Tx" SG_ 1054 SelDrvMdeChassis2_D_Rq 1;
BA_ "U_CD542_MY2021_Tx" SG_ 1054 SelDrvMdeChassis2_D_Rq 1;
BA_ "U_U55X_MY2022_Tx" SG_ 1054 SelDrvMdeChassis2_D_Rq 1;
BA_ "U_CD764_MY2022_Tx" SG_ 1054 SelDrvMdeChassis2_D_Rq 1;
BA_ "GenSigSendType" SG_ 1054 BrkPadMsgTxt_D_Rq 3;
BA_ "ECGUsedRxSignal" SG_ 1054 BrkPadMsgTxt_D_Rq 1;
BA_ "U_CD542_MY2021_Rx" SG_ 1054 BrkPadMsgTxt_D_Rq 1;
BA_ "U_U55X_MY2022_Rx" SG_ 1054 BrkPadMsgTxt_D_Rq 1;
BA_ "U_CD764_MY2022_Rx" SG_ 1054 BrkPadMsgTxt_D_Rq 1;
BA_ "U_CX727_MY2021_Tx" SG_ 1054 BrkPadMsgTxt_D_Rq 1;
BA_ "GenSigSendType" SG_ 1054 BrkBstrVac_D_Stat 3;
BA_ "U_P702_MY2021_Rx" SG_ 1054 BrkBstrVac_D_Stat 1;
BA_ "U_T6_MCA_MY2020_Rx" SG_ 1054 BrkBstrVac_D_Stat 1;
BA_ "U_CD542_MY2021_Rx" SG_ 1054 BrkBstrVac_D_Stat 1;
BA_ "U_U55X_MY2022_Rx" SG_ 1054 BrkBstrVac_D_Stat 1;
BA_ "U_CD764_MY2022_Rx" SG_ 1054 BrkBstrVac_D_Stat 1;
BA_ "U_CX727_MY2021_Tx" SG_ 1054 BrkBstrVac_D_Stat 1;
BA_ "U_P702_MY2021_Tx" SG_ 1054 BrkBstrVac_D_Stat 1;
BA_ "U_T6_MCA_MY2020_Tx" SG_ 1054 BrkBstrVac_D_Stat 1;
BA_ "U_CD542_MY2021_Tx" SG_ 1054 BrkBstrVac_D_Stat 1;
BA_ "U_U55X_MY2022_Tx" SG_ 1054 BrkBstrVac_D_Stat 1;
BA_ "U_CD764_MY2022_Tx" SG_ 1054 BrkBstrVac_D_Stat 1;
BA_ "GenSigSendType" SG_ 1054 DrvSlipCtlOffLamp_D_Rq 3;
BA_ "U_CX727_MY2021_Tx" SG_ 1054 DrvSlipCtlOffLamp_D_Rq 1;
BA_ "U_P702_MY2021_Tx" SG_ 1054 DrvSlipCtlOffLamp_D_Rq 1;
BA_ "U_T6_MCA_MY2020_Tx" SG_ 1054 DrvSlipCtlOffLamp_D_Rq 1;
BA_ "U_CD542_MY2021_Tx" SG_ 1054 DrvSlipCtlOffLamp_D_Rq 1;
BA_ "U_U55X_MY2022_Tx" SG_ 1054 DrvSlipCtlOffLamp_D_Rq 1;
BA_ "U_CD764_MY2022_Tx" SG_ 1054 DrvSlipCtlOffLamp_D_Rq 1;
BA_ "GenSigSendType" SG_ 1054 DrvSlipCtlMdeMsg_D_Rq 3;
BA_ "U_T6_MCA_MY2020_Rx" SG_ 1054 DrvSlipCtlMdeMsg_D_Rq 1;
BA_ "ECGUsedRxSignal" SG_ 1054 DrvSlipCtlMdeMsg_D_Rq 1;
BA_ "U_CD542_MY2021_Rx" SG_ 1054 DrvSlipCtlMdeMsg_D_Rq 1;
BA_ "U_U55X_MY2022_Rx" SG_ 1054 DrvSlipCtlMdeMsg_D_Rq 1;
BA_ "U_CD764_MY2022_Rx" SG_ 1054 DrvSlipCtlMdeMsg_D_Rq 1;
BA_ "U_CX727_MY2021_Tx" SG_ 1054 DrvSlipCtlMdeMsg_D_Rq 1;
BA_ "U_P702_MY2021_Tx" SG_ 1054 DrvSlipCtlMdeMsg_D_Rq 1;
BA_ "U_T6_MCA_MY2020_Tx" SG_ 1054 DrvSlipCtlMdeMsg_D_Rq 1;
BA_ "U_CD542_MY2021_Tx" SG_ 1054 DrvSlipCtlMdeMsg_D_Rq 1;
BA_ "U_U55X_MY2022_Tx" SG_ 1054 DrvSlipCtlMdeMsg_D_Rq 1;
BA_ "U_CD764_MY2022_Tx" SG_ 1054 DrvSlipCtlMdeMsg_D_Rq 1;
BA_ "GenSigSendType" SG_ 1054 AutoHoldMsgTxt_D_Rq 3;
BA_ "U_CX727_MY2021_Tx" SG_ 1054 AutoHoldMsgTxt_D_Rq 1;
BA_ "U_P702_MY2021_Tx" SG_ 1054 AutoHoldMsgTxt_D_Rq 1;
BA_ "U_T6_MCA_MY2020_Tx" SG_ 1054 AutoHoldMsgTxt_D_Rq 1;
BA_ "U_CD542_MY2021_Tx" SG_ 1054 AutoHoldMsgTxt_D_Rq 1;
BA_ "U_U55X_MY2022_Tx" SG_ 1054 AutoHoldMsgTxt_D_Rq 1;
BA_ "U_CD764_MY2022_Tx" SG_ 1054 AutoHoldMsgTxt_D_Rq 1;
BA_ "GenSigSendType" SG_ 1054 CtaBrk_D_Stat 3;
BA_ "U_T6_MCA_MY2020_Rx" SG_ 1054 CtaBrk_D_Stat 1;
BA_ "U_CD542_MY2021_Rx" SG_ 1054 CtaBrk_D_Stat 1;
BA_ "U_U55X_MY2022_Rx" SG_ 1054 CtaBrk_D_Stat 1;
BA_ "U_CD764_MY2022_Rx" SG_ 1054 CtaBrk_D_Stat 1;
BA_ "U_CX727_MY2021_Tx" SG_ 1054 CtaBrk_D_Stat 1;
BA_ "U_P702_MY2021_Tx" SG_ 1054 CtaBrk_D_Stat 1;
BA_ "U_T6_MCA_MY2020_Tx" SG_ 1054 CtaBrk_D_Stat 1;
BA_ "U_CD542_MY2021_Tx" SG_ 1054 CtaBrk_D_Stat 1;
BA_ "U_U55X_MY2022_Tx" SG_ 1054 CtaBrk_D_Stat 1;
BA_ "U_CD764_MY2022_Tx" SG_ 1054 CtaBrk_D_Stat 1;
BA_ "GenSigSendType" SG_ 1054 SelDrvMdeAwd_D_Rq 3;
BA_ "GenSigStartValueInteger" SG_ 1054 SelDrvMdeAwd_D_Rq 31;
BA_ "GenSigStartValue" SG_ 1054 SelDrvMdeAwd_D_Rq 31;
BA_ "U_P702_MY2021_Rx" SG_ 1054 SelDrvMdeAwd_D_Rq 1;
BA_ "U_T6_MCA_MY2020_Rx" SG_ 1054 SelDrvMdeAwd_D_Rq 1;
BA_ "U_U55X_MY2022_Rx" SG_ 1054 SelDrvMdeAwd_D_Rq 1;
BA_ "U_P702_MY2021_Tx" SG_ 1054 SelDrvMdeAwd_D_Rq 1;
BA_ "U_T6_MCA_MY2020_Tx" SG_ 1054 SelDrvMdeAwd_D_Rq 1;
BA_ "U_CD542_MY2021_Tx" SG_ 1054 SelDrvMdeAwd_D_Rq 1;
BA_ "U_U55X_MY2022_Tx" SG_ 1054 SelDrvMdeAwd_D_Rq 1;
BA_ "U_CD764_MY2022_Tx" SG_ 1054 SelDrvMdeAwd_D_Rq 1;
BA_ "GenSigSendType" SG_ 1054 AutoHoldSwMde_B_Ind 3;
BA_ "ContentDependant" SG_ 1054 AutoHoldSwMde_B_Ind 1;
BA_ "U_CX727_MY2021_Tx" SG_ 1054 AutoHoldSwMde_B_Ind 1;
BA_ "U_P702_MY2021_Tx" SG_ 1054 AutoHoldSwMde_B_Ind 1;
BA_ "U_T6_MCA_MY2020_Tx" SG_ 1054 AutoHoldSwMde_B_Ind 1;
BA_ "U_CD542_MY2021_Tx" SG_ 1054 AutoHoldSwMde_B_Ind 1;
BA_ "U_U55X_MY2022_Tx" SG_ 1054 AutoHoldSwMde_B_Ind 1;
BA_ "U_CD764_MY2022_Tx" SG_ 1054 AutoHoldSwMde_B_Ind 1;
BA_ "GenSigSendType" SG_ 1054 AutoHoldMde_D_Ind 3;
BA_ "U_CX727_MY2021_Tx" SG_ 1054 AutoHoldMde_D_Ind 1;
BA_ "U_P702_MY2021_Tx" SG_ 1054 AutoHoldMde_D_Ind 1;
BA_ "U_T6_MCA_MY2020_Tx" SG_ 1054 AutoHoldMde_D_Ind 1;
BA_ "U_CD542_MY2021_Tx" SG_ 1054 AutoHoldMde_D_Ind 1;
BA_ "U_U55X_MY2022_Tx" SG_ 1054 AutoHoldMde_D_Ind 1;
BA_ "U_CD764_MY2022_Tx" SG_ 1054 AutoHoldMde_D_Ind 1;
BA_ "GenSigSendType" SG_ 1054 SelDrvMdeChassis_D_Rq 3;
BA_ "U_T6_MCA_MY2020_Rx" SG_ 1054 SelDrvMdeChassis_D_Rq 1;
BA_ "U_U55X_MY2022_Rx" SG_ 1054 SelDrvMdeChassis_D_Rq 1;
BA_ "U_CX727_MY2021_Tx" SG_ 1054 SelDrvMdeChassis_D_Rq 1;
BA_ "U_P702_MY2021_Tx" SG_ 1054 SelDrvMdeChassis_D_Rq 1;
BA_ "U_T6_MCA_MY2020_Tx" SG_ 1054 SelDrvMdeChassis_D_Rq 1;
BA_ "U_CD542_MY2021_Tx" SG_ 1054 SelDrvMdeChassis_D_Rq 1;
BA_ "U_U55X_MY2022_Tx" SG_ 1054 SelDrvMdeChassis_D_Rq 1;
BA_ "U_CD764_MY2022_Tx" SG_ 1054 SelDrvMdeChassis_D_Rq 1;
BA_ "GenSigSendType" SG_ 1054 ApaBrk_D_Stat 3;
BA_ "U_CX727_MY2021_Rx" SG_ 1054 ApaBrk_D_Stat 1;
BA_ "U_P702_MY2021_Rx" SG_ 1054 ApaBrk_D_Stat 1;
BA_ "U_T6_MCA_MY2020_Rx" SG_ 1054 ApaBrk_D_Stat 1;
BA_ "U_CD542_MY2021_Rx" SG_ 1054 ApaBrk_D_Stat 1;
BA_ "U_U55X_MY2022_Rx" SG_ 1054 ApaBrk_D_Stat 1;
BA_ "U_CD764_MY2022_Rx" SG_ 1054 ApaBrk_D_Stat 1;
BA_ "U_CX727_MY2021_Tx" SG_ 1054 ApaBrk_D_Stat 1;
BA_ "U_P702_MY2021_Tx" SG_ 1054 ApaBrk_D_Stat 1;
BA_ "U_T6_MCA_MY2020_Tx" SG_ 1054 ApaBrk_D_Stat 1;
BA_ "U_CD542_MY2021_Tx" SG_ 1054 ApaBrk_D_Stat 1;
BA_ "U_U55X_MY2022_Tx" SG_ 1054 ApaBrk_D_Stat 1;
BA_ "U_CD764_MY2022_Tx" SG_ 1054 ApaBrk_D_Stat 1;
BA_ "GenSigSendType" SG_ 1054 FrontDiffElckrOpen_B_Rq 3;
BA_ "U_T6_MCA_MY2020_Rx" SG_ 1054 FrontDiffElckrOpen_B_Rq 1;
BA_ "U_T6_MCA_MY2020_Tx" SG_ 1054 FrontDiffElckrOpen_B_Rq 1;
BA_ "GenSigStartValueInteger" SG_ 1046 HsaMde_D_Mem 1;
BA_ "GenSigStartValue" SG_ 1046 HsaMde_D_Mem 1;
BA_ "U_CX727_MY2021_Tx" SG_ 1046 HsaMde_D_Mem 1;
BA_ "U_P702_MY2021_Tx" SG_ 1046 HsaMde_D_Mem 1;
BA_ "U_T6_MCA_MY2020_Tx" SG_ 1046 HsaMde_D_Mem 1;
BA_ "U_CD542_MY2021_Tx" SG_ 1046 HsaMde_D_Mem 1;
BA_ "U_U55X_MY2022_Tx" SG_ 1046 HsaMde_D_Mem 1;
BA_ "U_CD764_MY2022_Tx" SG_ 1046 HsaMde_D_Mem 1;
BA_ "U_P702_MY2021_Rx" SG_ 1046 BrkBstrVac_B_Rq 1;
BA_ "U_T6_MCA_MY2020_Rx" SG_ 1046 BrkBstrVac_B_Rq 1;
BA_ "U_CD542_MY2021_Rx" SG_ 1046 BrkBstrVac_B_Rq 1;
BA_ "U_U55X_MY2022_Rx" SG_ 1046 BrkBstrVac_B_Rq 1;
BA_ "U_CD764_MY2022_Rx" SG_ 1046 BrkBstrVac_B_Rq 1;
BA_ "U_CX727_MY2021_Tx" SG_ 1046 BrkBstrVac_B_Rq 1;
BA_ "U_P702_MY2021_Tx" SG_ 1046 BrkBstrVac_B_Rq 1;
BA_ "U_T6_MCA_MY2020_Tx" SG_ 1046 BrkBstrVac_B_Rq 1;
BA_ "U_CD542_MY2021_Tx" SG_ 1046 BrkBstrVac_B_Rq 1;
BA_ "U_U55X_MY2022_Tx" SG_ 1046 BrkBstrVac_B_Rq 1;
BA_ "U_CD764_MY2022_Tx" SG_ 1046 BrkBstrVac_B_Rq 1;
BA_ "U_T6_MCA_MY2020_Rx" SG_ 1046 TRLR_SWAY_EVNT_IN_PROG 1;
BA_ "ECGUsedRxSignal" SG_ 1046 TRLR_SWAY_EVNT_IN_PROG 1;
BA_ "U_CD542_MY2021_Rx" SG_ 1046 TRLR_SWAY_EVNT_IN_PROG 1;
BA_ "U_CD764_MY2022_Rx" SG_ 1046 TRLR_SWAY_EVNT_IN_PROG 1;
BA_ "U_CX727_MY2021_Tx" SG_ 1046 TRLR_SWAY_EVNT_IN_PROG 1;
BA_ "U_P702_MY2021_Tx" SG_ 1046 TRLR_SWAY_EVNT_IN_PROG 1;
BA_ "U_T6_MCA_MY2020_Tx" SG_ 1046 TRLR_SWAY_EVNT_IN_PROG 1;
BA_ "U_CD542_MY2021_Tx" SG_ 1046 TRLR_SWAY_EVNT_IN_PROG 1;
BA_ "U_U55X_MY2022_Tx" SG_ 1046 TRLR_SWAY_EVNT_IN_PROG 1;
BA_ "U_CD764_MY2022_Tx" SG_ 1046 TRLR_SWAY_EVNT_IN_PROG 1;
BA_ "U_CX727_MY2021_Tx" SG_ 1046 TRLR_SWAY_CONFIG_STAT 1;
BA_ "U_P702_MY2021_Tx" SG_ 1046 TRLR_SWAY_CONFIG_STAT 1;
BA_ "U_T6_MCA_MY2020_Tx" SG_ 1046 TRLR_SWAY_CONFIG_STAT 1;
BA_ "U_CD542_MY2021_Tx" SG_ 1046 TRLR_SWAY_CONFIG_STAT 1;
BA_ "U_U55X_MY2022_Tx" SG_ 1046 TRLR_SWAY_CONFIG_STAT 1;
BA_ "U_CD764_MY2022_Tx" SG_ 1046 TRLR_SWAY_CONFIG_STAT 1;
BA_ "ContentDependant" SG_ 1046 TCMode 1;
BA_ "U_CX727_MY2021_Rx" SG_ 1046 TCMode 1;
BA_ "U_P702_MY2021_Rx" SG_ 1046 TCMode 1;
BA_ "U_T6_MCA_MY2020_Rx" SG_ 1046 TCMode 1;
BA_ "ECGUsedRxSignal" SG_ 1046 TCMode 1;
BA_ "U_CD542_MY2021_Rx" SG_ 1046 TCMode 1;
BA_ "U_U55X_MY2022_Rx" SG_ 1046 TCMode 1;
BA_ "U_CD764_MY2022_Rx" SG_ 1046 TCMode 1;
BA_ "U_CX727_MY2021_Tx" SG_ 1046 TCMode 1;
BA_ "U_P702_MY2021_Tx" SG_ 1046 TCMode 1;
BA_ "U_T6_MCA_MY2020_Tx" SG_ 1046 TCMode 1;
BA_ "U_CD542_MY2021_Tx" SG_ 1046 TCMode 1;
BA_ "U_U55X_MY2022_Tx" SG_ 1046 TCMode 1;
BA_ "U_CD764_MY2022_Tx" SG_ 1046 TCMode 1;
BA_ "U_CX727_MY2021_Rx" SG_ 1046 DrvSlipCtlLamp_D_Rq 1;
BA_ "U_P702_MY2021_Rx" SG_ 1046 DrvSlipCtlLamp_D_Rq 1;
BA_ "U_T6_MCA_MY2020_Rx" SG_ 1046 DrvSlipCtlLamp_D_Rq 1;
BA_ "U_CD542_MY2021_Rx" SG_ 1046 DrvSlipCtlLamp_D_Rq 1;
BA_ "U_U55X_MY2022_Rx" SG_ 1046 DrvSlipCtlLamp_D_Rq 1;
BA_ "U_CD764_MY2022_Rx" SG_ 1046 DrvSlipCtlLamp_D_Rq 1;
BA_ "U_CX727_MY2021_Tx" SG_ 1046 DrvSlipCtlLamp_D_Rq 1;
BA_ "U_P702_MY2021_Tx" SG_ 1046 DrvSlipCtlLamp_D_Rq 1;
BA_ "U_T6_MCA_MY2020_Tx" SG_ 1046 DrvSlipCtlLamp_D_Rq 1;
BA_ "U_CD542_MY2021_Tx" SG_ 1046 DrvSlipCtlLamp_D_Rq 1;
BA_ "U_U55X_MY2022_Tx" SG_ 1046 DrvSlipCtlLamp_D_Rq 1;
BA_ "U_CD764_MY2022_Tx" SG_ 1046 DrvSlipCtlLamp_D_Rq 1;
BA_ "U_CX727_MY2021_Rx" SG_ 1046 Abs_B_Falt 1;
BA_ "U_P702_MY2021_Rx" SG_ 1046 Abs_B_Falt 1;
BA_ "U_T6_MCA_MY2020_Rx" SG_ 1046 Abs_B_Falt 1;
BA_ "ECGUsedRxSignal" SG_ 1046 Abs_B_Falt 1;
BA_ "U_CD542_MY2021_Rx" SG_ 1046 Abs_B_Falt 1;
BA_ "U_U55X_MY2022_Rx" SG_ 1046 Abs_B_Falt 1;
BA_ "U_CD764_MY2022_Rx" SG_ 1046 Abs_B_Falt 1;
BA_ "U_CX727_MY2021_Tx" SG_ 1046 Abs_B_Falt 1;
BA_ "U_P702_MY2021_Tx" SG_ 1046 Abs_B_Falt 1;
BA_ "U_T6_MCA_MY2020_Tx" SG_ 1046 Abs_B_Falt 1;
BA_ "U_CD542_MY2021_Tx" SG_ 1046 Abs_B_Falt 1;
BA_ "U_U55X_MY2022_Tx" SG_ 1046 Abs_B_Falt 1;
BA_ "U_CD764_MY2022_Tx" SG_ 1046 Abs_B_Falt 1;
BA_ "U_CX727_MY2021_Rx" SG_ 1046 DrvSlipCtlMde_D_Ind 1;
BA_ "U_P702_MY2021_Rx" SG_ 1046 DrvSlipCtlMde_D_Ind 1;
BA_ "U_T6_MCA_MY2020_Rx" SG_ 1046 DrvSlipCtlMde_D_Ind 1;
BA_ "ECGUsedRxSignal" SG_ 1046 DrvSlipCtlMde_D_Ind 1;
BA_ "U_CD542_MY2021_Rx" SG_ 1046 DrvSlipCtlMde_D_Ind 1;
BA_ "U_U55X_MY2022_Rx" SG_ 1046 DrvSlipCtlMde_D_Ind 1;
BA_ "U_CD764_MY2022_Rx" SG_ 1046 DrvSlipCtlMde_D_Ind 1;
BA_ "U_CX727_MY2021_Tx" SG_ 1046 DrvSlipCtlMde_D_Ind 1;
BA_ "U_P702_MY2021_Tx" SG_ 1046 DrvSlipCtlMde_D_Ind 1;
BA_ "U_T6_MCA_MY2020_Tx" SG_ 1046 DrvSlipCtlMde_D_Ind 1;
BA_ "U_CD542_MY2021_Tx" SG_ 1046 DrvSlipCtlMde_D_Ind 1;
BA_ "U_U55X_MY2022_Tx" SG_ 1046 DrvSlipCtlMde_D_Ind 1;
BA_ "U_CD764_MY2022_Tx" SG_ 1046 DrvSlipCtlMde_D_Ind 1;
BA_ "U_P702_MY2021_Rx" SG_ 1046 DrvAntiLckLamp_D_Rq 1;
BA_ "U_T6_MCA_MY2020_Rx" SG_ 1046 DrvAntiLckLamp_D_Rq 1;
BA_ "U_CD542_MY2021_Rx" SG_ 1046 DrvAntiLckLamp_D_Rq 1;
BA_ "U_U55X_MY2022_Rx" SG_ 1046 DrvAntiLckLamp_D_Rq 1;
BA_ "U_CD764_MY2022_Rx" SG_ 1046 DrvAntiLckLamp_D_Rq 1;
BA_ "U_CX727_MY2021_Tx" SG_ 1046 DrvAntiLckLamp_D_Rq 1;
BA_ "U_P702_MY2021_Tx" SG_ 1046 DrvAntiLckLamp_D_Rq 1;
BA_ "U_T6_MCA_MY2020_Tx" SG_ 1046 DrvAntiLckLamp_D_Rq 1;
BA_ "U_CD542_MY2021_Tx" SG_ 1046 DrvAntiLckLamp_D_Rq 1;
BA_ "U_U55X_MY2022_Tx" SG_ 1046 DrvAntiLckLamp_D_Rq 1;
BA_ "U_CD764_MY2022_Tx" SG_ 1046 DrvAntiLckLamp_D_Rq 1;
BA_ "MetaData" SG_ 1046 BpedMove_No_Cnt 1;
BA_ "U_CX727_MY2021_Rx" SG_ 1046 BpedMove_No_Cnt 1;
BA_ "U_P702_MY2021_Rx" SG_ 1046 BpedMove_No_Cnt 1;
BA_ "U_CD542_MY2021_Rx" SG_ 1046 BpedMove_No_Cnt 1;
BA_ "U_CX727_MY2021_Tx" SG_ 1046 BpedMove_No_Cnt 1;
BA_ "U_P702_MY2021_Tx" SG_ 1046 BpedMove_No_Cnt 1;
BA_ "U_T6_MCA_MY2020_Tx" SG_ 1046 BpedMove_No_Cnt 1;
BA_ "U_CD542_MY2021_Tx" SG_ 1046 BpedMove_No_Cnt 1;
BA_ "U_U55X_MY2022_Tx" SG_ 1046 BpedMove_No_Cnt 1;
BA_ "U_CD764_MY2022_Tx" SG_ 1046 BpedMove_No_Cnt 1;
BA_ "GenSigStartValueInteger" SG_ 1046 StabCtlBrk_B_Avail 1;
BA_ "GenSigStartValue" SG_ 1046 StabCtlBrk_B_Avail 1;
BA_ "U_T6_MCA_MY2020_Rx" SG_ 1046 StabCtlBrk_B_Avail 1;
BA_ "U_U55X_MY2022_Rx" SG_ 1046 StabCtlBrk_B_Avail 1;
BA_ "U_CX727_MY2021_Tx" SG_ 1046 StabCtlBrk_B_Avail 1;
BA_ "U_P702_MY2021_Tx" SG_ 1046 StabCtlBrk_B_Avail 1;
BA_ "U_T6_MCA_MY2020_Tx" SG_ 1046 StabCtlBrk_B_Avail 1;
BA_ "U_CD542_MY2021_Tx" SG_ 1046 StabCtlBrk_B_Avail 1;
BA_ "U_U55X_MY2022_Tx" SG_ 1046 StabCtlBrk_B_Avail 1;
BA_ "U_CD764_MY2022_Tx" SG_ 1046 StabCtlBrk_B_Avail 1;
BA_ "GenSigStartValueInteger" SG_ 1046 BpedMove_D_Actl 3;
BA_ "GenSigStartValue" SG_ 1046 BpedMove_D_Actl 3;
BA_ "U_CX727_MY2021_Rx" SG_ 1046 BpedMove_D_Actl 1;
BA_ "U_P702_MY2021_Rx" SG_ 1046 BpedMove_D_Actl 1;
BA_ "U_T6_MCA_MY2020_Rx" SG_ 1046 BpedMove_D_Actl 1;
BA_ "U_CD542_MY2021_Rx" SG_ 1046 BpedMove_D_Actl 1;
BA_ "U_CX727_MY2021_Tx" SG_ 1046 BpedMove_D_Actl 1;
BA_ "U_P702_MY2021_Tx" SG_ 1046 BpedMove_D_Actl 1;
BA_ "U_T6_MCA_MY2020_Tx" SG_ 1046 BpedMove_D_Actl 1;
BA_ "U_CD542_MY2021_Tx" SG_ 1046 BpedMove_D_Actl 1;
BA_ "U_U55X_MY2022_Tx" SG_ 1046 BpedMove_D_Actl 1;
BA_ "U_CD764_MY2022_Tx" SG_ 1046 BpedMove_D_Actl 1;
BA_ "U_CX727_MY2021_Tx" SG_ 1046 ChimeBrk_B_Rq 1;
BA_ "U_P702_MY2021_Tx" SG_ 1046 ChimeBrk_B_Rq 1;
BA_ "U_T6_MCA_MY2020_Tx" SG_ 1046 ChimeBrk_B_Rq 1;
BA_ "U_CD542_MY2021_Tx" SG_ 1046 ChimeBrk_B_Rq 1;
BA_ "U_U55X_MY2022_Tx" SG_ 1046 ChimeBrk_B_Rq 1;
BA_ "U_CD764_MY2022_Tx" SG_ 1046 ChimeBrk_B_Rq 1;
BA_ "U_CX727_MY2021_Tx" SG_ 1046 BrkLamp_B_Rq 1;
BA_ "U_P702_MY2021_Tx" SG_ 1046 BrkLamp_B_Rq 1;
BA_ "U_T6_MCA_MY2020_Tx" SG_ 1046 BrkLamp_B_Rq 1;
BA_ "U_CD542_MY2021_Tx" SG_ 1046 BrkLamp_B_Rq 1;
BA_ "U_U55X_MY2022_Tx" SG_ 1046 BrkLamp_B_Rq 1;
BA_ "U_CD764_MY2022_Tx" SG_ 1046 BrkLamp_B_Rq 1;
BA_ "MetaData" SG_ 1046 BpedDiffLckTq_No_Cs 1;
BA_ "U_CX727_MY2021_Tx" SG_ 1046 BpedDiffLckTq_No_Cs 1;
BA_ "U_CD542_MY2021_Tx" SG_ 1046 BpedDiffLckTq_No_Cs 1;
BA_ "U_CD764_MY2022_Tx" SG_ 1046 BpedDiffLckTq_No_Cs 1;
BA_ "U_T6_MCA_MY2020_Rx" SG_ 1046 RearDiffElckrOpen_B_Rq 1;
BA_ "U_P702_MY2021_Tx" SG_ 1046 RearDiffElckrOpen_B_Rq 1;
BA_ "U_T6_MCA_MY2020_Tx" SG_ 1046 RearDiffElckrOpen_B_Rq 1;
BA_ "U_U55X_MY2022_Tx" SG_ 1046 RearDiffElckrOpen_B_Rq 1;
BA_ "GenSigStartValueInteger" SG_ 1045 VehStab_D_Stat 14;
BA_ "GenSigStartValue" SG_ 1045 VehStab_D_Stat 14;
BA_ "U_CX727_MY2021_Rx" SG_ 1045 VehStab_D_Stat 1;
BA_ "U_P702_MY2021_Rx" SG_ 1045 VehStab_D_Stat 1;
BA_ "U_T6_MCA_MY2020_Rx" SG_ 1045 VehStab_D_Stat 1;
BA_ "U_CD542_MY2021_Rx" SG_ 1045 VehStab_D_Stat 1;
BA_ "U_U55X_MY2022_Rx" SG_ 1045 VehStab_D_Stat 1;
BA_ "U_CD764_MY2022_Rx" SG_ 1045 VehStab_D_Stat 1;
BA_ "U_CX727_MY2021_Tx" SG_ 1045 VehStab_D_Stat 1;
BA_ "U_P702_MY2021_Tx" SG_ 1045 VehStab_D_Stat 1;
BA_ "U_T6_MCA_MY2020_Tx" SG_ 1045 VehStab_D_Stat 1;
BA_ "U_CD542_MY2021_Tx" SG_ 1045 VehStab_D_Stat 1;
BA_ "U_U55X_MY2022_Tx" SG_ 1045 VehStab_D_Stat 1;
BA_ "U_CD764_MY2022_Tx" SG_ 1045 VehStab_D_Stat 1;
BA_ "U_CX727_MY2021_Tx" SG_ 1045 BrkFluidLvl_D_Stat 1;
BA_ "U_P702_MY2021_Tx" SG_ 1045 BrkFluidLvl_D_Stat 1;
BA_ "U_T6_MCA_MY2020_Tx" SG_ 1045 BrkFluidLvl_D_Stat 1;
BA_ "U_CD542_MY2021_Tx" SG_ 1045 BrkFluidLvl_D_Stat 1;
BA_ "U_U55X_MY2022_Tx" SG_ 1045 BrkFluidLvl_D_Stat 1;
BA_ "U_CD764_MY2022_Tx" SG_ 1045 BrkFluidLvl_D_Stat 1;
BA_ "GenSigStartValueInteger" SG_ 1045 VehYawNonLin_W_Rq 4094;
BA_ "GenSigStartValue" SG_ 1045 VehYawNonLin_W_Rq 4094;
BA_ "U_CX727_MY2021_Rx" SG_ 1045 VehYawNonLin_W_Rq 1;
BA_ "U_P702_MY2021_Rx" SG_ 1045 VehYawNonLin_W_Rq 1;
BA_ "U_T6_MCA_MY2020_Rx" SG_ 1045 VehYawNonLin_W_Rq 1;
BA_ "U_U55X_MY2022_Rx" SG_ 1045 VehYawNonLin_W_Rq 1;
BA_ "U_CX727_MY2021_Tx" SG_ 1045 VehYawNonLin_W_Rq 1;
BA_ "U_P702_MY2021_Tx" SG_ 1045 VehYawNonLin_W_Rq 1;
BA_ "U_T6_MCA_MY2020_Tx" SG_ 1045 VehYawNonLin_W_Rq 1;
BA_ "U_CD542_MY2021_Tx" SG_ 1045 VehYawNonLin_W_Rq 1;
BA_ "U_U55X_MY2022_Tx" SG_ 1045 VehYawNonLin_W_Rq 1;
BA_ "U_CD764_MY2022_Tx" SG_ 1045 VehYawNonLin_W_Rq 1;
BA_ "GenSigStartValueInteger" SG_ 1045 VehYawLin_W_Rq 4094;
BA_ "GenSigStartValue" SG_ 1045 VehYawLin_W_Rq 4094;
BA_ "U_CX727_MY2021_Rx" SG_ 1045 VehYawLin_W_Rq 1;
BA_ "U_P702_MY2021_Rx" SG_ 1045 VehYawLin_W_Rq 1;
BA_ "U_T6_MCA_MY2020_Rx" SG_ 1045 VehYawLin_W_Rq 1;
BA_ "U_U55X_MY2022_Rx" SG_ 1045 VehYawLin_W_Rq 1;
BA_ "U_CX727_MY2021_Tx" SG_ 1045 VehYawLin_W_Rq 1;
BA_ "U_P702_MY2021_Tx" SG_ 1045 VehYawLin_W_Rq 1;
BA_ "U_T6_MCA_MY2020_Tx" SG_ 1045 VehYawLin_W_Rq 1;
BA_ "U_CD542_MY2021_Tx" SG_ 1045 VehYawLin_W_Rq 1;
BA_ "U_U55X_MY2022_Tx" SG_ 1045 VehYawLin_W_Rq 1;
BA_ "U_CD764_MY2022_Tx" SG_ 1045 VehYawLin_W_Rq 1;
BA_ "MetaData" SG_ 1045 VehVActlBrk_No_Cs 1;
BA_ "U_CX727_MY2021_Rx" SG_ 1045 VehVActlBrk_No_Cs 1;
BA_ "U_P702_MY2021_Rx" SG_ 1045 VehVActlBrk_No_Cs 1;
BA_ "U_T6_MCA_MY2020_Rx" SG_ 1045 VehVActlBrk_No_Cs 1;
BA_ "U_CD542_MY2021_Rx" SG_ 1045 VehVActlBrk_No_Cs 1;
BA_ "U_U55X_MY2022_Rx" SG_ 1045 VehVActlBrk_No_Cs 1;
BA_ "U_CD764_MY2022_Rx" SG_ 1045 VehVActlBrk_No_Cs 1;
BA_ "U_CX727_MY2021_Tx" SG_ 1045 VehVActlBrk_No_Cs 1;
BA_ "U_P702_MY2021_Tx" SG_ 1045 VehVActlBrk_No_Cs 1;
BA_ "U_T6_MCA_MY2020_Tx" SG_ 1045 VehVActlBrk_No_Cs 1;
BA_ "U_CD542_MY2021_Tx" SG_ 1045 VehVActlBrk_No_Cs 1;
BA_ "U_U55X_MY2022_Tx" SG_ 1045 VehVActlBrk_No_Cs 1;
BA_ "U_CD764_MY2022_Tx" SG_ 1045 VehVActlBrk_No_Cs 1;
BA_ "U_CX727_MY2021_Rx" SG_ 1045 Veh_V_ActlBrk 1;
BA_ "U_P702_MY2021_Rx" SG_ 1045 Veh_V_ActlBrk 1;
BA_ "U_T6_MCA_MY2020_Rx" SG_ 1045 Veh_V_ActlBrk 1;
BA_ "U_CD542_MY2021_Rx" SG_ 1045 Veh_V_ActlBrk 1;
BA_ "U_U55X_MY2022_Rx" SG_ 1045 Veh_V_ActlBrk 1;
BA_ "U_CD764_MY2022_Rx" SG_ 1045 Veh_V_ActlBrk 1;
BA_ "U_CX727_MY2021_Tx" SG_ 1045 Veh_V_ActlBrk 1;
BA_ "U_P702_MY2021_Tx" SG_ 1045 Veh_V_ActlBrk 1;
BA_ "U_T6_MCA_MY2020_Tx" SG_ 1045 Veh_V_ActlBrk 1;
BA_ "U_CD542_MY2021_Tx" SG_ 1045 Veh_V_ActlBrk 1;
BA_ "U_U55X_MY2022_Tx" SG_ 1045 Veh_V_ActlBrk 1;
BA_ "U_CD764_MY2022_Tx" SG_ 1045 Veh_V_ActlBrk 1;
BA_ "MetaData" SG_ 1045 VehVActlBrk_No_Cnt 1;
BA_ "U_CX727_MY2021_Rx" SG_ 1045 VehVActlBrk_No_Cnt 1;
BA_ "U_P702_MY2021_Rx" SG_ 1045 VehVActlBrk_No_Cnt 1;
BA_ "U_T6_MCA_MY2020_Rx" SG_ 1045 VehVActlBrk_No_Cnt 1;
BA_ "U_CD542_MY2021_Rx" SG_ 1045 VehVActlBrk_No_Cnt 1;
BA_ "U_U55X_MY2022_Rx" SG_ 1045 VehVActlBrk_No_Cnt 1;
BA_ "U_CD764_MY2022_Rx" SG_ 1045 VehVActlBrk_No_Cnt 1;
BA_ "U_CX727_MY2021_Tx" SG_ 1045 VehVActlBrk_No_Cnt 1;
BA_ "U_P702_MY2021_Tx" SG_ 1045 VehVActlBrk_No_Cnt 1;
BA_ "U_T6_MCA_MY2020_Tx" SG_ 1045 VehVActlBrk_No_Cnt 1;
BA_ "U_CD542_MY2021_Tx" SG_ 1045 VehVActlBrk_No_Cnt 1;
BA_ "U_U55X_MY2022_Tx" SG_ 1045 VehVActlBrk_No_Cnt 1;
BA_ "U_CD764_MY2022_Tx" SG_ 1045 VehVActlBrk_No_Cnt 1;
BA_ "MetaData" SG_ 1045 VehVActlBrk_D_Qf 1;
BA_ "U_CX727_MY2021_Rx" SG_ 1045 VehVActlBrk_D_Qf 1;
BA_ "U_P702_MY2021_Rx" SG_ 1045 VehVActlBrk_D_Qf 1;
BA_ "U_T6_MCA_MY2020_Rx" SG_ 1045 VehVActlBrk_D_Qf 1;
BA_ "U_CD542_MY2021_Rx" SG_ 1045 VehVActlBrk_D_Qf 1;
BA_ "U_U55X_MY2022_Rx" SG_ 1045 VehVActlBrk_D_Qf 1;
BA_ "U_CD764_MY2022_Rx" SG_ 1045 VehVActlBrk_D_Qf 1;
BA_ "U_CX727_MY2021_Tx" SG_ 1045 VehVActlBrk_D_Qf 1;
BA_ "U_P702_MY2021_Tx" SG_ 1045 VehVActlBrk_D_Qf 1;
BA_ "U_T6_MCA_MY2020_Tx" SG_ 1045 VehVActlBrk_D_Qf 1;
BA_ "U_CD542_MY2021_Tx" SG_ 1045 VehVActlBrk_D_Qf 1;
BA_ "U_U55X_MY2022_Tx" SG_ 1045 VehVActlBrk_D_Qf 1;
BA_ "U_CD764_MY2022_Tx" SG_ 1045 VehVActlBrk_D_Qf 1;
BA_ "U_CDX706_MY2023_Tx" SG_ 1044 ApaBrkErr_D_Stat 1;
BA_ "U_CDX706_MY2023_Rx" SG_ 1044 ApaBrkErr_D_Stat 1;
BA_ "GenSigStartValue" SG_ 1044 ApaBrkErr_D_Stat 2;
BA_ "U_CDX706_MY2023_Tx" SG_ 1044 ApaBrkErrDStat_No_Cs 1;
BA_ "U_CDX706_MY2023_Rx" SG_ 1044 ApaBrkErrDStat_No_Cs 1;
BA_ "MetaData" SG_ 1044 ApaBrkErrDStat_No_Cs 1;
BA_ "U_CDX706_MY2023_Tx" SG_ 1044 ApaBrkErrDStat_No_Cnt 1;
BA_ "U_CDX706_MY2023_Rx" SG_ 1044 ApaBrkErrDStat_No_Cnt 1;
BA_ "MetaData" SG_ 1044 ApaBrkErrDStat_No_Cnt 1;
BA_ "GenSigStartValueInteger" SG_ 1044 StePinOffst_An_Est 65534;
BA_ "ContentDependant" SG_ 1044 StePinOffst_An_Est 1;
BA_ "GenSigStartValue" SG_ 1044 StePinOffst_An_Est 65533;
BA_ "U_CX727_MY2021_Rx" SG_ 1044 StePinOffst_An_Est 1;
BA_ "U_P702_MY2021_Rx" SG_ 1044 StePinOffst_An_Est 1;
BA_ "U_T6_MCA_MY2020_Rx" SG_ 1044 StePinOffst_An_Est 1;
BA_ "U_CD542_MY2021_Rx" SG_ 1044 StePinOffst_An_Est 1;
BA_ "U_U55X_MY2022_Rx" SG_ 1044 StePinOffst_An_Est 1;
BA_ "U_CD764_MY2022_Rx" SG_ 1044 StePinOffst_An_Est 1;
BA_ "U_CX727_MY2021_Tx" SG_ 1044 StePinOffst_An_Est 1;
BA_ "U_P702_MY2021_Tx" SG_ 1044 StePinOffst_An_Est 1;
BA_ "U_T6_MCA_MY2020_Tx" SG_ 1044 StePinOffst_An_Est 1;
BA_ "U_CD542_MY2021_Tx" SG_ 1044 StePinOffst_An_Est 1;
BA_ "U_U55X_MY2022_Tx" SG_ 1044 StePinOffst_An_Est 1;
BA_ "U_CD764_MY2022_Tx" SG_ 1044 StePinOffst_An_Est 1;
BA_ "ContentDependant" SG_ 1044 StePinOffst_No_Cs 1;
BA_ "MetaData" SG_ 1044 StePinOffst_No_Cs 1;
BA_ "U_CX727_MY2021_Rx" SG_ 1044 StePinOffst_No_Cs 1;
BA_ "U_P702_MY2021_Rx" SG_ 1044 StePinOffst_No_Cs 1;
BA_ "U_T6_MCA_MY2020_Rx" SG_ 1044 StePinOffst_No_Cs 1;
BA_ "U_CD542_MY2021_Rx" SG_ 1044 StePinOffst_No_Cs 1;
BA_ "U_U55X_MY2022_Rx" SG_ 1044 StePinOffst_No_Cs 1;
BA_ "U_CD764_MY2022_Rx" SG_ 1044 StePinOffst_No_Cs 1;
BA_ "U_CX727_MY2021_Tx" SG_ 1044 StePinOffst_No_Cs 1;
BA_ "U_P702_MY2021_Tx" SG_ 1044 StePinOffst_No_Cs 1;
BA_ "U_T6_MCA_MY2020_Tx" SG_ 1044 StePinOffst_No_Cs 1;
BA_ "U_CD542_MY2021_Tx" SG_ 1044 StePinOffst_No_Cs 1;
BA_ "U_U55X_MY2022_Tx" SG_ 1044 StePinOffst_No_Cs 1;
BA_ "U_CD764_MY2022_Tx" SG_ 1044 StePinOffst_No_Cs 1;
BA_ "MetaData" SG_ 1044 StePinOffst_No_Cnt 1;
BA_ "U_CX727_MY2021_Rx" SG_ 1044 StePinOffst_No_Cnt 1;
BA_ "U_P702_MY2021_Rx" SG_ 1044 StePinOffst_No_Cnt 1;
BA_ "U_T6_MCA_MY2020_Rx" SG_ 1044 StePinOffst_No_Cnt 1;
BA_ "U_CD542_MY2021_Rx" SG_ 1044 StePinOffst_No_Cnt 1;
BA_ "U_U55X_MY2022_Rx" SG_ 1044 StePinOffst_No_Cnt 1;
BA_ "U_CD764_MY2022_Rx" SG_ 1044 StePinOffst_No_Cnt 1;
BA_ "U_CX727_MY2021_Tx" SG_ 1044 StePinOffst_No_Cnt 1;
BA_ "U_P702_MY2021_Tx" SG_ 1044 StePinOffst_No_Cnt 1;
BA_ "U_T6_MCA_MY2020_Tx" SG_ 1044 StePinOffst_No_Cnt 1;
BA_ "U_CD542_MY2021_Tx" SG_ 1044 StePinOffst_No_Cnt 1;
BA_ "U_U55X_MY2022_Tx" SG_ 1044 StePinOffst_No_Cnt 1;
BA_ "U_CD764_MY2022_Tx" SG_ 1044 StePinOffst_No_Cnt 1;
BA_ "U_CX727_MY2021_Rx" SG_ 1044 StePinOffst_D_Stat 1;
BA_ "U_P702_MY2021_Rx" SG_ 1044 StePinOffst_D_Stat 1;
BA_ "U_T6_MCA_MY2020_Rx" SG_ 1044 StePinOffst_D_Stat 1;
BA_ "U_CD542_MY2021_Rx" SG_ 1044 StePinOffst_D_Stat 1;
BA_ "U_U55X_MY2022_Rx" SG_ 1044 StePinOffst_D_Stat 1;
BA_ "U_CD764_MY2022_Rx" SG_ 1044 StePinOffst_D_Stat 1;
BA_ "U_CX727_MY2021_Tx" SG_ 1044 StePinOffst_D_Stat 1;
BA_ "U_P702_MY2021_Tx" SG_ 1044 StePinOffst_D_Stat 1;
BA_ "U_T6_MCA_MY2020_Tx" SG_ 1044 StePinOffst_D_Stat 1;
BA_ "U_CD542_MY2021_Tx" SG_ 1044 StePinOffst_D_Stat 1;
BA_ "U_U55X_MY2022_Tx" SG_ 1044 StePinOffst_D_Stat 1;
BA_ "U_CD764_MY2022_Tx" SG_ 1044 StePinOffst_D_Stat 1;
BA_ "GenSigStartValueInteger" SG_ 1042 VehRol_An_Dsply 64;
BA_ "U_P702_MY2021_Tx" SG_ 1042 VehRol_An_Dsply 1;
BA_ "U_T6_MCA_MY2020_Tx" SG_ 1042 VehRol_An_Dsply 1;
BA_ "U_U55X_MY2022_Tx" SG_ 1042 VehRol_An_Dsply 1;
BA_ "GenSigStartValueInteger" SG_ 1042 VehPtch_An_Dsply 64;
BA_ "U_P702_MY2021_Rx" SG_ 1042 VehPtch_An_Dsply 1;
BA_ "U_U55X_MY2022_Rx" SG_ 1042 VehPtch_An_Dsply 1;
BA_ "U_P702_MY2021_Tx" SG_ 1042 VehPtch_An_Dsply 1;
BA_ "U_T6_MCA_MY2020_Tx" SG_ 1042 VehPtch_An_Dsply 1;
BA_ "U_U55X_MY2022_Tx" SG_ 1042 VehPtch_An_Dsply 1;
VAL_ 985 LongCtrlBrk_D_Rq 3 "NotUsed" 2 "LowDecel" 1 "HighDecel" 0 "NoRequest" ;
VAL_ 985 AdbDrvSide_B_Stat 1 "Left_Hand_Traffic" 0 "Right_Hand_Traffic" ;
VAL_ 985 LcwaMsgTxt_D_Stat 3 "SodXFaulty" 2 "SodXBlocked" 1 "TrailerConnected" 0 "NoMessage" ;
VAL_ 985 AdbDividedRoad_B_Stat 1 "Yes" 0 "No" ;
VAL_ 985 IsaVLimUnit_D_Rq 3 "NoDataExists" 2 "Mph" 1 "Kph" 0 "Null" ;
VAL_ 985 SblmYieldScnr_B_Stat 1 "Yes" 0 "No" ;
VAL_ 985 SblmStopScnr_B_Stat 1 "Yes" 0 "No" ;
VAL_ 985 IsaVLim_D_Rq 252 "NotUsed_2" 250 "LimitSpeed_250" 240 "LimitSpeed_240" 230 "LimitSpeed_230" 220 "LimitSpeed_220" 210 "LimitSpeed_210" 200 "LimitSpeed_200" 190 "LimitSpeed_190" 150 "LimitSpeed_150" 140 "LimitSpeed_140" 130 "LimitSpeed_130" 120 "LimitSpeed_120" 110 "LimitSpeed_110" 100 "LimitSpeed_100" 90 "LimitSpeed_90" 80 "LimitSpeed_80" 70 "LimitSpeed_70" 60 "LimitSpeed_60" 50 "LimitSpeed_50" 40 "LimitSpeed_40" 30 "LimitSpeed_30" 20 "LimtSpeed_20" 251 "NotUsed_1" 255 "Faulty" 254 "NoDataExists" 253 "NotUsed_3" 180 "LimitSpeed_180" 179 "LimitSpeed_179" 178 "LimitSpeed_178" 177 "LimitSpeed_177" 176 "LimitSpeed_176" 175 "LimitSpeed_175" 174 "LimitSpeed_174" 173 "LimitSpeed_173" 172 "LimitSpeed_172" 171 "LimitSpeed_171" 170 "LimitSpeed_170" 169 "LimitSpeed_169" 168 "LimitSpeed_168" 167 "LimitSpeed_167" 166 "LimitSpeed_166" 165 "LimitSpeed_165" 164 "LimitSpeed_164" 163 "LimitSpeed_163" 162 "LimitSpeed_162" 161 "LimitSpeed_161" 160 "LimitSpeed_160" 15 "LimitSpeed_15" 14 "LimitSpeed_14" 13 "LimitSpeed_13" 12 "LimitSpeed_12" 11 "LimitSpeed_11" 10 "LimitSpeed_10" 9 "LimitSpeed_9" 8 "LimitSpeed_8" 7 "LimitSpeed_7" 6 "LimitSpeed_6" 5 "LimitSpeed_5" 4 "LimitSpeed_4" 3 "LimitSpeed_3" 2 "LimitSpeed_2" 1 "LimitSpeed_1" 0 "LimitSpeed_0" ;
VAL_ 985 IaccVLimUnit_D_Rq 3 "NoDataExists" 2 "Mph" 1 "Kph" 0 "Null" ;
VAL_ 985 IaccVLim_D_Rq 252 "NotUsed_2" 250 "LimitSpeed_250" 240 "LimitSpeed_240" 230 "LimitSpeed_230" 220 "LimitSpeed_220" 210 "LimitSpeed_210" 200 "LimitSpeed_200" 190 "LimitSpeed_190" 150 "LimitSpeed_150" 140 "LimitSpeed_140" 130 "LimitSpeed_130" 120 "LimitSpeed_120" 110 "LimitSpeed_110" 100 "LimitSpeed_100" 90 "LimitSpeed_90" 80 "LimitSpeed_80" 70 "LimitSpeed_70" 60 "LimitSpeed_60" 50 "LimitSpeed_50" 40 "LimitSpeed_40" 30 "LimitSpeed_30" 20 "LimtSpeed_20" 251 "NotUsed_1" 255 "Faulty" 254 "NoDataExists" 253 "NotUsed_3" 180 "LimitSpeed_180" 179 "LimitSpeed_179" 178 "LimitSpeed_178" 177 "LimitSpeed_177" 176 "LimitSpeed_176" 175 "LimitSpeed_175" 174 "LimitSpeed_174" 173 "LimitSpeed_173" 172 "LimitSpeed_172" 171 "LimitSpeed_171" 170 "LimitSpeed_170" 169 "LimitSpeed_169" 168 "LimitSpeed_168" 167 "LimitSpeed_167" 166 "LimitSpeed_166" 165 "LimitSpeed_165" 164 "LimitSpeed_164" 163 "LimitSpeed_163" 162 "LimitSpeed_162" 161 "LimitSpeed_161" 160 "LimitSpeed_160" 15 "LimitSpeed_15" 14 "LimitSpeed_14" 13 "LimitSpeed_13" 12 "LimitSpeed_12" 11 "LimitSpeed_11" 10 "LimitSpeed_10" 9 "LimitSpeed_9" 8 "LimitSpeed_8" 7 "LimitSpeed_7" 6 "LimitSpeed_6" 5 "LimitSpeed_5" 4 "LimitSpeed_4" 3 "LimitSpeed_3" 2 "LimitSpeed_2" 1 "LimitSpeed_1" 0 "LimitSpeed_0" ;
VAL_ 985 DasAlrtInfo_D_Dsply 3 "NotUsed" 2 "On" 1 "Off" 0 "Null" ;
VAL_ 985 SblmRndAbtScnr_B_Stat 1 "Yes" 0 "No" ;
VAL_ 985 PwSustnAdas_B_Rq 1 "Active" 0 "Inactive" ;
VAL_ 985 ClrExitAsstMsgTxt_D_Rq 15 "NotUsed_8" 14 "NotUsed_7" 13 "NotUsed_6" 12 "NotUsed_5" 11 "NotUsed_4" 10 "NotUsed_3" 9 "NotUsed_2" 8 "NotUsed_1" 7 "SystemFault" 6 "ChildLockMaintained" 5 "WarningRight" 4 "WarningLeft" 3 "InformationRight" 2 "InformationLeft" 1 "Shutdown" 0 "NoMessage" ;
VAL_ 985 ClrExitAsstChime_D_Rq 7 "NotUsed_4" 6 "NotUsed_3" 5 "NotUsed_2" 4 "NotUsed_1" 3 "WarningChimeFront" 2 "WarningChimeRear" 1 "InformationChime" 0 "Off" ;
VAL_ 985 LongCtrlEnbl_D_Rq 7 "Faulty" 6 "NotUsed_3" 5 "NotUsed_2" 4 "NotUsed_1" 3 "RemoteParking" 2 "Autohitch" 1 "AutomaticParking" 0 "None" ;
VAL_ 985 SblmPedCrossScnr_B_Stat 1 "Yes" 0 "No" ;
VAL_ 985 TsrRegionTxt_D_Stat 31 "Faulty" 30 "NotUsed_8" 29 "NotUsed_7" 28 "NotUsed_6" 27 "NotUsed_5" 26 "NotUsed_4" 25 "NotUsed_3" 24 "NotUsed_2" 23 "NotUsed_1" 22 "Region_22" 21 "Region_21" 20 "Region_20" 19 "Region_19" 18 "Region_18" 17 "Region_17" 16 "Region_16" 15 "Region_15" 14 "Region_14" 13 "Region_13" 12 "Region_12" 11 "Region_11" 10 "Region_10" 9 "Region_09" 8 "Region_08" 7 "Region_07" 6 "Region_06" 5 "Region_05" 4 "Region_04" 3 "Region_03" 2 "Region_02" 1 "Region_01" 0 "NotDetermined" ;
VAL_ 985 LdwChime_B_Rq 1 "On" 0 "Off" ;
VAL_ 985 ClrExitAsst_D_Stat 3 "NotUsed" 2 "Enabled" 1 "Disabled" 0 "Null" ;
VAL_ 984 DasWarn_D_Dsply 3 "Undefined" 2 "Warning_Level_2" 1 "Warning_Level_1" 0 "No_Warning" ;
VAL_ 984 DasStats_D_Dsply 3 "Available" 2 "Unavailable_Other" 1 "Feedback_due_to_Speed" 0 "Off" ;
VAL_ 984 DasAlrtLvl_D_Dsply 5 "Alertness_Level_5" 4 "Alertness_Level_4" 3 "Alertness_Level_3" 2 "Alertness_Level_2" 1 "Alertness_Level_1" 0 "Undefined" ;
VAL_ 984 CamraStats_D_Dsply 3 "FrtCam_TempUnavailOther" 2 "FrtCam_TempUnavailVisibile" 1 "Front_Camera_Service_Reqd" 0 "Front_Camera_OK" ;
VAL_ 984 CamraDefog_B_Req 1 "On" 0 "Off" ;
VAL_ 984 LaHandsOff_D_Dsply 3 "Suppressed" 2 "Level2" 1 "Level1" 0 "HandsOn" ;
VAL_ 984 LaDenyStats_B_Dsply 1 "Unavailable" 0 "Available" ;
VAL_ 984 AhbcRampingV_D_Rq 3 "Slow" 2 "Medium" 1 "Fast" 0 "Immediately" ;
VAL_ 984 PersIndexIpma_D_Actl 7 "Unused_3" 6 "Unused_2" 5 "Unused_1" 4 "Vehicle" 3 "PERS_4" 2 "PERS_3" 1 "PERS_2" 0 "PERS_1" ;
VAL_ 984 AhbFeat_D_Stat 3 "ADB" 2 "GFHB" 1 "AHBC" 0 "None" ;
VAL_ 984 DsmcMsgTxt_D_Dsply 3 "Blockage" 2 "DriverNotSeen" 1 "Fault" 0 "NoMessage" ;
VAL_ 984 AhbHiBeam_D_Rq 3 "NotUsed" 2 "HighBeamRecommended" 1 "LowBeamRecommended" 0 "DeactivatedUnavailable" ;
VAL_ 984 LaActvStats_D2_Dsply 31 "Unused7" 30 "LA_Off" 29 "ECE_OFF_RTT" 28 "Unused4" 27 "Unused3" 26 "Unused2" 25 "Unused1" 24 "InerveneLeft_InterveneRght" 23 "WarnLeft_InterveneRight" 22 "SuppressLeft_InterveneRght" 21 "AvailLeft_InterveneRhtt" 20 "NoLeft_InterveneRight" 19 "InterveneLeft_WarnRight" 18 "WarnLeft_WarnRight" 17 "SuppressLeft_WarnRight" 16 "AvailableLeft_WarnRight" 15 "NoLeft_WarnRight" 14 "InterveneLeft_SuppressRght" 13 "WarnLeft_SuppressRight" 12 "SuppressLeft_SuppressRight" 11 "AvailLeft_SuppressRight" 10 "NoLeft_SuppressRight" 9 "InterveneLeft_AvailRight" 8 "WarnLeft_AvailRight" 7 "SuppressLeft_AvailRight" 6 "AvailableLeft_AvailRight" 5 "NoLeft_AvailableRight" 4 "InterveneLeft_NoRight" 3 "WarnLeft_NoRight" 2 "SuppressLeft_NoRight" 1 "AvailableLeft_NoRight" 0 "NoLeft_NoRight" ;
VAL_ 983 CmbbObjRelLong_V_Actl 1023 "Faulty" 1022 "NoDataExists" ;
VAL_ 983 CmbbObjRelLat_V_Actl 511 "Faulty" 510 "NoDataExists" ;
VAL_ 983 CmbbObjDistLong_L_Actl 1023 "Faulty" 1022 "NoDataExists" ;
VAL_ 983 CmbbObjDistLat_L_Actl 511 "Faulty" 510 "NoDataExists" ;
VAL_ 983 CmbbObjConfdnc_D_Stat 3 "High" 2 "Medium" 1 "Low" 0 "NotDetermined" ;
VAL_ 983 CmbbObjColl_T_Actl 127 "Faulty" 126 "NoDataExists" ;
VAL_ 983 CmbbObjClass_D_Stat 15 "NotUsed_9" 14 "NotUsed_8" 13 "NotUsed_7" 12 "NotUsed_6" 11 "NotUsed_5" 10 "NotUsed_4" 9 "NotUsed_3" 8 "NotUsed_2" 7 "NotUsed_1" 6 "Unclassified_Vehicle" 5 "Bicycle" 4 "Pedestrian" 3 "Truck" 2 "Motorcycle" 1 "Vehicle" 0 "Undetermined" ;
VAL_ 983 EsaEnbl_D2_Rq 3 "NotConfigured" 2 "Enabled" 1 "Pending" 0 "Disabled" ;
VAL_ 976 SuspClkSync_No_Actl 255 "Faulty" 254 "NoDataExists" ;
VAL_ 976 SrpSigValid_B_Stat 1 "True" 0 "False" ;
VAL_ 976 SrpHghtRight_L_Actl 511 "Faulty" 510 "NoDataExists" ;
VAL_ 976 SrpHghtLeft_L_Actl 511 "Faulty" 510 "NoDataExists" ;
VAL_ 976 SrpEventRight_D_Stat 3 "Faulty" 2 "Bump" 1 "Pothole" 0 "NoEvent" ;
VAL_ 976 SrpEventLeft_D_Stat 3 "Faulty" 2 "Bump" 1 "Pothole" 0 "NoEvent" ;
VAL_ 976 SrpDistRight_L_Actl 511 "Faulty" 510 "NoDataExists" ;
VAL_ 976 SrpDistLeft_L_Actl 511 "Faulty" 510 "NoDataExists" ;
VAL_ 973 PersCtaSplitView_D_Stat 3 "EnabledFull" 2 "Enabled_180SwitchOnly" 1 "Disabled" 0 "Null" ;
VAL_ 973 TsrVl2PrmntMsgTxt_D_Rq 3 "NotUsed" 2 "ShowPermanentlyWithSupp" 1 "ShowPermanentlyWithoutSupp" 0 "DoNotShowSignPermanent" ;
VAL_ 973 TsrVl1PrmntMsgTxt_D_Rq 3 "NotUsed" 2 "ShowPermanentlyWithSupp" 1 "ShowPermanentlyWithoutSupp" 0 "DoNotShowSignPermanent" ;
VAL_ 973 TsrVl2RstrcMsgTxt2_D_Rq 7 "NotUsed" 6 "Time" 5 "Trailer" 4 "Snow" 3 "RainWet" 2 "NoRecognizableRestrictn" 1 "NoSpeedLimitRestrictn" 0 "Null" ;
VAL_ 973 TsrVl1RstrcMsgTxt2_D_Rq 7 "NotUsed" 6 "Time" 5 "Trailer" 4 "Snow" 3 "RainWet" 2 "NoRecognizableRestrictn" 1 "NoSpeedLimitRestrictn" 0 "Null" ;
VAL_ 973 TsrOvtkMsgTxt2_D_Rq 15 "NotUsed5" 14 "NotUsed4" 13 "NotUsed3" 12 "NotUsed2" 11 "NotUsed1" 10 "LimForTrucksCancelled" 9 "LimForTrucksWoQlfdRstrc" 8 "LimForTrucksWithoutRstrc" 7 "LimAllCancelled" 6 "LimAllWithRstrcTime" 5 "LimAllWithRstrcTrailer" 4 "LimAllWithRstrcSnow" 3 "LimAllWithRstrcRain" 2 "LimAllWithoutQlfdRstrc" 1 "LimAllWithoutRestriction" 0 "OvertakingAllowed" ;
VAL_ 973 WwaWarn_B_Rq 1 "On" 0 "Off" ;
VAL_ 973 TsrVlUnitMsgTxt_D_Rq 3 "NoDataExists" 2 "Mph" 1 "Kph" 0 "Null" ;
VAL_ 973 TsrVLim2MsgTxt_D_Rq 255 "NoLimit" 254 "NotUsed2" 253 "NotUsed1" 252 "NotToBeDisplayed" 251 "LimitCancelled" 31 "1F_FA_Message31_250" 30 "Message30" 29 "Message29" 28 "Message28" 27 "Message27" 26 "Message26" 25 "Message25" 24 "Message24" 23 "Message23" 22 "Message22" 21 "Message21" 20 "Message20" 19 "Message19" 18 "Message18" 17 "Message17" 16 "Message16" 15 "Message15" 14 "Message14" 13 "Message13" 12 "Message12" 11 "Message11" 10 "Message10" 9 "Message9" 8 "Message8" 7 "Message7" 6 "Message6" 5 "Message5" 4 "Message4" 3 "Message3" 2 "Message2" 1 "Message1" 0 "Null" ;
VAL_ 973 TsrVLim1MsgTxt_D_Rq 255 "NoLimit" 254 "NotUsed2" 253 "NotUsed1" 252 "NotToBeDisplayed" 251 "LimitCancelled" 31 "1F_FA_Message31_250" 30 "Message30" 29 "Message29" 28 "Message28" 27 "Message27" 26 "Message26" 25 "Message25" 24 "Message24" 23 "Message23" 22 "Message22" 21 "Message21" 20 "Message20" 19 "Message19" 18 "Message18" 17 "Message17" 16 "Message16" 15 "Message15" 14 "Message14" 13 "Message13" 12 "Message12" 11 "Message11" 10 "Message10" 9 "Message9" 8 "Message8" 7 "Message7" 6 "Message6" 5 "Message5" 4 "Message4" 3 "Message3" 2 "Message2" 1 "Message1" 0 "Null" ;
VAL_ 973 TsrVl2StatMsgTxt_D_Rq 3 "LimitOutdated" 2 "LimitReiable" 1 "LimitChanged" 0 "Null" ;
VAL_ 973 TsrVl2RstrcMsgTxt_D_Rq 3 "NotUsed" 2 "NoRecognizableRestriction" 1 "NoSpeedLimitRestriction" 0 "Null" ;
VAL_ 973 TsrVl1StatMsgTxt_D_Rq 3 "LimitOutdated" 2 "LimitReiable" 1 "LimitChanged" 0 "Null" ;
VAL_ 973 TsrVl1RstrcMsgTxt_D_Rq 3 "NotUsed" 2 "NoRecognizableRestriction" 1 "NoSpeedLimitRestriction" 0 "Null" ;
VAL_ 973 TsrStatMsgTxt_D_Rq 7 "NotUsed" 6 "NoDataExists" 5 "TSR_Error" 4 "Available_NavigationOnly" 3 "Available_CameraOnly" 2 "Available_FusionMode" 1 "TSR_Off" 0 "Null" ;
VAL_ 973 TsrOvtkStatMsgTxt_D_Rq 3 "LimitOutdated" 2 "LimitReiable" 1 "LimitChanged" 0 "Null" ;
VAL_ 973 TsrOvtkMsgTxt_D_Rq 7 "LimForTrucksCancelled" 6 "LimForTrucksWoQlfdRstrc" 5 "LimForTrucksWithoutRstrc" 4 "LimAllCancelled" 3 "LimAllWithoutQlfdRstrc" 2 "LimAllWithoutRestriction" 1 "OvertakingAllowed" 0 "Null" ;
VAL_ 973 TsrOswWarnMsgTxt_D_Rq 3 "NotUsed" 2 "True" 1 "False" 0 "Null" ;
VAL_ 973 TsrMsgTxt_D_Rq 15 "NotUsed6" 14 "NotUsed5" 13 "NotUsed4" 12 "NotUsed3" 11 "NotUsed2" 10 "NotUsed1" 9 "RecgnzdSignNotUsblForDsply" 8 "LimitedSystemPerformance" 7 "OffRoad" 6 "RegionNotSupported" 5 "CountryNotSupported" 4 "WrngNavDatIncompDatCarrier" 3 "NoNavDataAvailable" 2 "NoNavAvailableSwitchedOff" 1 "NoInformationAllOK" 0 "Null" ;
VAL_ 973 LaSysOffStat_D_Dsply 3 "Level_3" 2 "Level_2" 1 "Level_1" 0 "Level_0" ;
VAL_ 970 TurnLght_D_RqTja 0 "Off" 1 "Left" 2 "Right" 3 "NotUsed" ;
VAL_ 970 LkaDrvOvrrd_D_Rq 3 "Level_3" 2 "Level_2" 1 "Level_1" 0 "Level_0" ;
VAL_ 970 LkaActvStats_D2_Req 7 "NotUsed" 6 "LkaIncrIntervRight" 5 "LkaSupprRight" 4 "LkaStandIntervRight" 3 "LkaSupprLeft" 2 "LkaStandIntervLeft" 1 "LkaIncrIntervLeft" 0 "LkaNoInterv" ;
VAL_ 970 LaRefAng_No_Req 4095 "Fault" ;
VAL_ 970 LaRampType_B_Req 1 "Quick" 0 "Smooth" ;
VAL_ 970 LaCurvature_No_Calc 4095 "Fault" ;
VAL_ 970 LdwActvStats_D_Req 7 "LDW_Suppress_Right_Left" 6 "Not_Used2" 5 "LDW_Suppress_Right" 4 "LDW_Warning_Right" 3 "LDW_Suppress_Left" 2 "LDW_Warning_Left" 1 "LDW_DemoVibration" 0 "LDW_Idle" ;
VAL_ 970 LdwActvIntns_D_Req 3 "High" 2 "Medium" 1 "Low" 0 "None" ;
VAL_ 394 AccTrgDist2_D_Dsply 15 "DIST_ACTIVE_13_Farthest" 14 "DIST_ACTIVE_12" 13 "DIST_ACTIVE_11" 12 "DIST_ACTIVE_10" 11 "DIST_ACTIVE_9" 10 "DIST_ACTIVE_8" 9 "DIST_ACTIVE_7" 8 "DIST_ACTIVE_6" 7 "DIST_ACTIVE_5" 6 "DIST_ACTIVE_4" 5 "DIST_ACTIVE_3" 4 "DIST_ACTIVE_2" 3 "DIST_ACTIVE_1_Closest" 2 "DIST_ACTIVE_No_Target" 1 "DIST_STANDBY" 0 "DIST_OFF" ;
VAL_ 394 AccStopRes_B_Dsply 1 "Yes" 0 "No" ;
VAL_ 394 TjaWarn_D_Rq 7 "HardTakeOverEyesOff" 6 "SoftTakeOverEyesOff" 5 "HaLaneDeptWarningLeft" 4 "HaLaneDeptWarningRight" 3 "HardTakeOverLevel2" 2 "HardTakeOverLevel1" 1 "TrafficJamAssistCancel" 0 "NoWarning" ;
VAL_ 394 Tja_D_Stat 7 "ExtendedActive" 6 "ActiveWarningRight" 5 "ActiveWarningLeft" 4 "ActiveInterventionRight" 3 "ActiveInterventionLeft" 2 "Active" 1 "Standby" 0 "Off" ;
VAL_ 394 TjaMsgTxt_D_Dsply 7 "Disclaimer" 6 "SmartOffering" 5 "HaSelected" 4 "HaUnavailable" 3 "TurnOnAdaptCruiseControl" 2 "TrafficJamAssistSelected" 1 "TrafficJamAssistUnavailabl" 0 "NoMessage" ;
VAL_ 394 IaccLamp_D_Rq 3 "NotUsed_2" 2 "NotUsed_1" 1 "DisplayIaccIcon" 0 "DoNotDisplayIaccIcon" ;
VAL_ 394 AccMsgTxt_D2_Rq 15 "Brakes_Warm" 14 "NCC_Enabled_Warning" 13 "IACC_TJA_Selected" 12 "ACC_TJA_Selected" 11 "IACC_Selected" 10 "Press_Brake_To_Hold" 9 "Only_Following_In_Low_Spd" 8 "TJA_Unavailable" 7 "Shift_Down" 6 "IACC_Unavailable" 5 "ACC_Selected" 4 "ACC_Overridden" 3 "Brake_Capacity_Warning" 2 "ACC_Cancelled" 1 "ACC_Unavailable" 0 "No_Text" ;
VAL_ 394 FcwDeny_B_Dsply 1 "Yes" 0 "No" ;
VAL_ 394 FcwMemStat_B_Actl 1 "On" 0 "Off" ;
VAL_ 394 AccTGap_B_Dsply 1 "Yes" 0 "No" ;
VAL_ 394 CadsAlignIncplt_B_Actl 1 "Yes" 0 "No" ;
VAL_ 394 AccFllwMde_B_Dsply 1 "Yes" 0 "No" ;
VAL_ 394 CadsRadrBlck_B_Actl 1 "Yes" 0 "No" ;
VAL_ 394 CmbbPostEvnt_B_Dsply 1 "Yes" 0 "No" ;
VAL_ 394 AccStopMde_B_Dsply 1 "Yes" 0 "No" ;
VAL_ 394 FcwMemSens_D_Actl 3 "FCW_Sensitivity_3" 2 "FCW_Sensitivity_2" 1 "FCW_Sensitivity_1" 0 "Not_Used" ;
VAL_ 394 FcwMsgTxt_D_Rq 7 "Undefined_3" 6 "Undefined_2" 5 "Low_Visibility" 4 "Unavailable_DueTo_LowSpeed" 3 "Available" 2 "Unavailable" 1 "Off" 0 "No_Text" ;
VAL_ 394 AccWarn_D_Dsply 3 "BrakeReleaseWarn_In_StopMd" 2 "Brake_Capacity_Warning" 1 "Cancel_Warning" 0 "No_Warning" ;
VAL_ 394 FcwVisblWarn_B_Rq 1 "On" 0 "Off" ;
VAL_ 394 FcwAudioWarn_B_Rq 1 "On" 0 "Off" ;
VAL_ 394 AccTGap_D_Dsply 7 "Undefined_2" 6 "Undefined_1" 5 "Time_Gap_5" 4 "Time_Gap_4" 3 "Time_Gap_3" 2 "Time_Gap_2" 1 "Time_Gap_1" 0 "Not_Used" ;
VAL_ 394 AccMemEnbl_B_RqDrv 1 "Adaptive_Cruise" 0 "Normal_Cruise" ;
VAL_ 394 AccStopStat_D_Dsply 3 "PressResume" 2 "Stopped" 1 "ResumeReady" 0 "NoDisplay" ;
VAL_ 391 HudBlk3_B_Rq 1 "Yes" 0 "No" ;
VAL_ 391 HudBlk2_B_Rq 1 "Yes" 0 "No" ;
VAL_ 391 HudBlk1_B_Rq 1 "Yes" 0 "No" ;
VAL_ 391 HudFlashRate_D_Actl 3 "Unused" 2 "Flash_4Hz_50Prct_DutyCycle" 1 "On" 0 "Off" ;
VAL_ 391 CmbbBrkPrchg_D_Rq 3 "Undefined" 2 "Level_2_PreCharge_Request" 1 "Level_1_PreCharge_Request" 0 "No_PreCharge_Request" ;
VAL_ 391 CmbbBrkDecel_B_Rq 1 "Yes" 0 "No" ;
VAL_ 391 CmbbBaSens_D_Rq 3 "Level_3" 2 "Level_2" 1 "Level_1" 0 "Normal" ;
VAL_ 390 AccBrkPrkEl_B_Rq 1 "Yes" 0 "No" ;
VAL_ 390 Cmbb_B_Enbl 1 "Yes" 0 "No" ;
VAL_ 390 CmbbOvrrd_B_RqDrv 1 "Yes" 0 "No" ;
VAL_ 390 CmbbDeny_B_Actl 1 "Yes" 0 "No" ;
VAL_ 390 CmbbEngTqMn_B_Rq 1 "Yes" 0 "No" ;
VAL_ 390 AccDeny_B_Rq 1 "Yes" 0 "No" ;
VAL_ 390 AccResumEnbl_B_Rq 1 "Yes" 0 "No" ;
VAL_ 390 AccCancl_B_Rq 1 "Yes" 0 "No" ;
VAL_ 390 AccBrkPrchg_B_Rq 1 "Yes" 0 "No" ;
VAL_ 390 AccBrkDecel_B_Rq 1 "Active" 0 "Inactive" ;
VAL_ 390 AccStopStat_B_Rq 1 "Yes" 0 "No" ;
VAL_ 390 AccAutoResum_D_Rq 3 "NotUsed" 2 "Active" 1 "Pending" 0 "Off" ;
VAL_ 390 AccBrkPulse_B_Rq 1 "True" 0 "False" ;
VAL_ 611 AwdSys_D_Stat 3 "Faulty" 2 "NotUsed" 1 "_4x4_L_H_Active" 0 "_4x4_L_H_Inactive" ;
VAL_ 611 AwdRnge_D_Actl 7 "Unknown" 6 "High_Range_2wd" 5 "High_Range_Auto" 4 "High_Range_Locked" 3 "Neutral" 2 "Low_Range_2wd" 1 "Low_Range_Auto" 0 "Low_Range_Locked" ;
VAL_ 611 AwdLoLamp_D_RqDsply 3 "Not_Used" 2 "Flash" 1 "On" 0 "Off" ;
VAL_ 611 AwdHiLamp_D_RqDsply 3 "Not_Used" 2 "Flash" 1 "On" 0 "Off" ;
VAL_ 611 AwdAutoLamp_D_RqDsply 3 "Not_Used" 2 "Flash" 1 "On" 0 "Off" ;
VAL_ 611 Awd2wdLamp_D_RqDsply 3 "Not_Used" 2 "Flash" 1 "On" 0 "Off" ;
VAL_ 611 AwdTerrMdeChng_D_Rdy 7 "Fault" 6 "Undefined_2" 5 "Undefined_1" 4 "ModeUnavailDrInputRqd" 3 "SpOpModes_NotSupported" 2 "ModeUnavailDynamicCond" 1 "Module_In_Initialization" 0 "Mode_Change_Available" ;
VAL_ 611 AwdTerrMde_D_Actl 7 "Fail_Safe_Default" 6 "Dynamic_Mode" 5 "Rock_Crawl_Mode" 4 "Mud_Ruts_Mode" 3 "Sand_Mode" 2 "Undefined" 1 "Low_Mu_Mode" 0 "Special_Operating_Mode_Off" ;
VAL_ 611 AwdStat_D_RqDsply 31 "Rear_Diff_Lock_Not_Avail" 30 "_4wd_Lock_Required" 29 "Cfg_Perf_Redc_See_Manual" 28 "To_Engage_4x4_Release_Aped" 27 "To_Engage_4x4_Slow_To_3MPH" 26 "Shift_To_Neutral" 25 "Lkr_Mode_Unavail_TMS" 24 " _4x4_Mode_Unavail_TMS" 23 "Out_of_4Low_Crawl" 22 "AWD_PTU_Oil_Changed" 21 "Change_AWD_PTU_Oil" 20 "Neutral_Tow_Disabled" 19 "Neutral_Tow_Enabled" 18 "AWD_OFF" 17 "_4x4_Off_Road_Speed" 16 "_4x4_Extreme_Off_Road_Mode" 15 "_4x4_Exiting_Off_Road" 14 "_4x4_Off_Road_Mode" 10 "_4x4_Locked_Temporarily" 9 "Shift_In_Progress" 13 "Blocked_Shift_Assist" 12 "_4x4_Auto_Restored" 11 "_4x4_Disabled_Temporarily" 7 "Out_of_4Low__Neutral" 6 "Out_of_4Low__Brake" 5 "Out_of_4Low__Speed" 4 "Into_4Low__Clutch" 3 "Into_4Low__Neutral" 2 "Into_4Low__Brake" 1 "Into_4Low__Speed" 0 "Normal__No_Message" 8 "Out_of_4Low__Clutch" ;
VAL_ 611 AwdLck_D_Stat 9 "Undefined" 8 "Under_External_Torque_Ctrl" 7 "Torque_Limited_by_Cmd" 6 "Fully_Locked_by_Cmd" 5 "Disabled" 4 "Warning" 3 "Fault" 2 "Inactive" 1 "Completely_Opened_by_Cmd" 0 "OK" ;
VAL_ 611 AwdSrvcRqd_B_Rq 1 "On" 0 "Off" ;
VAL_ 611 AwdLck_Tq_Rq 4095 "Fault" 4094 "Unknown" ;
VAL_ 1047 EsaOn_B_Stat 1 "On" 0 "Off" ;
VAL_ 1047 SelDrvMdeSte_D_Stat 0 "NotAvailable" 1 "Available" 2 "TemporarilyNotAvailable" 3 "Faulty" ;
VAL_ 972 TjaHandsOnCnfdnc_B_Est 1 "High_Confidence" 0 "Low_Confidence" ;
VAL_ 972 LaHandsOff_B_Actl 1 "Hands_Off" 0 "Hands_On" ;
VAL_ 972 LaActDeny_B_Actl 1 "LA_Denied" 0 "LA_Not_Denied" ;
VAL_ 972 LatCtlSte_D_Stat 7 "NotUsed3" 6 "NotUsed2" 5 "NotUsed1" 4 "Denied" 3 "RampOut" 2 "ContLatControlInProgress" 1 "Available" 0 "Unavailable" ;
VAL_ 972 LatCtlLim_D_Stat 3 "LimitWithDriverActive" 2 "LimitReached" 1 "LimitClose" 0 "LimitNotReached" ;
VAL_ 972 LatCtlCpblty_D_Stat 3 "Faulty" 2 "ExtendedModeAvailable" 1 "LimitedModeAvailable" 0 "NoModeAvailable" ;
VAL_ 972 LaActAvail_D2_Actl 3 "Intervention_Available" 2 "NoIntervention_Available" 1 "Intervention_NotAvailable" 0 "NoIntervention_NotAvailabl" ;
VAL_ 130 SteMdule_D_Stat 7 "NotUsed" 6 "EPAS_Failure3" 5 "EPAS_Failure2" 4 "System_Failure" 3 "EPAS_Shutdown" 2 "Normal_Op_Full_Assist" 1 "Normal_Op_Limited_Assist" 0 "EPAS_Initialization" ;
VAL_ 130 SteMdule_U_Meas 255 "Invalid" ;
VAL_ 130 SteMdule_I_Est 4095 "Invalid" ;
VAL_ 130 EPAS_Failure 3 "SERVICE_POWER_STEERING_NOW" 2 "SERVICE_POWER_STEERING" 1 "POWER_STRG_ASSIST_FAULT" 0 "EPAS_OK_NO_MESSAGE" ;
VAL_ 130 SteeringColumnTorque 255 "Invalid" 254 "Unknown" ;
VAL_ 130 SAPPAngleControlStat6 1 "RequestedAngleNotReached" 0 "RequestedAngleCanBeReached" ;
VAL_ 130 SAPPAngleControlStat5 1 "StrgColTorqueExceed_EAROn" 0 "ExternalSigContentOKforEAC" ;
VAL_ 130 SAPPAngleControlStat4 1 "SpeedLimitExceededEAROn" 0 "ExternalSigContentOKforEAC" ;
VAL_ 130 SAPPAngleControlStat3 1 "EARactiveNoReverseEngage" 0 "ExternalSigContentOKforEAC" ;
VAL_ 130 SAPPAngleControlStat2 1 "Rel_ExtSteeringAngleReqx" 0 "NoRel_ExtSteeringAngleReqx" ;
VAL_ 130 SAPPAngleControlStat1 3 "Fault" 2 "Active" 1 "Open" 0 "Closed" ;
VAL_ 126 StePw_B_Rq 1 "Yes" 0 "No" ;
VAL_ 126 StePinRelInit_An_Sns 65535 "Faulty" 65534 "NoDataExists" ;
VAL_ 126 StePinCompAnEst_D_Qf 3 "OK" 2 "Degraded" 1 "No_Data_Exists" 0 "Faulty" ;
VAL_ 1200 HsaTrnAout_Tq_Rq 65535 "Fault" 65534 "Unknown" ;
VAL_ 1200 BrkBstrVac_P_Actl 127 "Invalid" ;
VAL_ 1200 YawStabilityIndex 511 "Fault" 510 "NoDataExists" ;
VAL_ 1200 BrkTot_Tq_RqDrv 8191 "Fault" ;
VAL_ 1200 BrkHold_D_Stat 7 "NotUsed_3" 6 "NotUsed_2" 5 "NotUsed_1" 4 "HeldSecondary" 3 "HeldSecure" 2 "Held" 1 "Inactive" 0 "Off" ;
VAL_ 1102 SelDrvMdePos12_D_Stat 31 "Faulty" 30 "SelDrvMde31" 29 "SelDrvMde30" 28 "SelDrvMde29" 27 "SelDrvMde28" 26 "SelDrvMde27" 25 "SelDrvMde26" 24 "SelDrvMde25" 23 "SelDrvMde24" 22 "SelDrvMde23" 21 "SelDrvMde22" 20 "SelDrvMde21" 19 "SelDrvMde20" 18 "SelDrvMde19" 17 "SelDrvMde18" 16 "SelDrvMde17" 15 "SelDrvMde16" 14 "SelDrvMde15" 13 "SelDrvMde14" 12 "SelDrvMde13" 11 "SelDrvMde12" 10 "SelDrvMde11" 9 "SelDrvMde10" 8 "SelDrvMde09" 7 "SelDrvMde08" 6 "SelDrvMde07" 5 "SelDrvMde06" 4 "SelDrvMde05" 3 "SelDrvMde04" 2 "SelDrvMde03" 1 "SelDrvMde02" 0 "SelDrvMde01" ;
VAL_ 1102 SelDrvMdePos11_D_Stat 31 "Faulty" 30 "SelDrvMde31" 29 "SelDrvMde30" 28 "SelDrvMde29" 27 "SelDrvMde28" 26 "SelDrvMde27" 25 "SelDrvMde26" 24 "SelDrvMde25" 23 "SelDrvMde24" 22 "SelDrvMde23" 21 "SelDrvMde22" 20 "SelDrvMde21" 19 "SelDrvMde20" 18 "SelDrvMde19" 17 "SelDrvMde18" 16 "SelDrvMde17" 15 "SelDrvMde16" 14 "SelDrvMde15" 13 "SelDrvMde14" 12 "SelDrvMde13" 11 "SelDrvMde12" 10 "SelDrvMde11" 9 "SelDrvMde10" 8 "SelDrvMde09" 7 "SelDrvMde08" 6 "SelDrvMde07" 5 "SelDrvMde06" 4 "SelDrvMde05" 3 "SelDrvMde04" 2 "SelDrvMde03" 1 "SelDrvMde02" 0 "SelDrvMde01" ;
VAL_ 1102 SelDrvMdePos10_D_Stat 31 "Faulty" 30 "SelDrvMde31" 29 "SelDrvMde30" 28 "SelDrvMde29" 27 "SelDrvMde28" 26 "SelDrvMde27" 25 "SelDrvMde26" 24 "SelDrvMde25" 23 "SelDrvMde24" 22 "SelDrvMde23" 21 "SelDrvMde22" 20 "SelDrvMde21" 19 "SelDrvMde20" 18 "SelDrvMde19" 17 "SelDrvMde18" 16 "SelDrvMde17" 15 "SelDrvMde16" 14 "SelDrvMde15" 13 "SelDrvMde14" 12 "SelDrvMde13" 11 "SelDrvMde12" 10 "SelDrvMde11" 9 "SelDrvMde10" 8 "SelDrvMde09" 7 "SelDrvMde08" 6 "SelDrvMde07" 5 "SelDrvMde06" 4 "SelDrvMde05" 3 "SelDrvMde04" 2 "SelDrvMde03" 1 "SelDrvMde02" 0 "SelDrvMde01" ;
VAL_ 1102 SelDrvMdePos09_D_Stat 31 "Faulty" 30 "SelDrvMde31" 29 "SelDrvMde30" 28 "SelDrvMde29" 27 "SelDrvMde28" 26 "SelDrvMde27" 25 "SelDrvMde26" 24 "SelDrvMde25" 23 "SelDrvMde24" 22 "SelDrvMde23" 21 "SelDrvMde22" 20 "SelDrvMde21" 19 "SelDrvMde20" 18 "SelDrvMde19" 17 "SelDrvMde18" 16 "SelDrvMde17" 15 "SelDrvMde16" 14 "SelDrvMde15" 13 "SelDrvMde14" 12 "SelDrvMde13" 11 "SelDrvMde12" 10 "SelDrvMde11" 9 "SelDrvMde10" 8 "SelDrvMde09" 7 "SelDrvMde08" 6 "SelDrvMde07" 5 "SelDrvMde06" 4 "SelDrvMde05" 3 "SelDrvMde04" 2 "SelDrvMde03" 1 "SelDrvMde02" 0 "SelDrvMde01" ;
VAL_ 1102 SelDrvMdePos08_D_Stat 31 "Faulty" 30 "SelDrvMde31" 29 "SelDrvMde30" 28 "SelDrvMde29" 27 "SelDrvMde28" 26 "SelDrvMde27" 25 "SelDrvMde26" 24 "SelDrvMde25" 23 "SelDrvMde24" 22 "SelDrvMde23" 21 "SelDrvMde22" 20 "SelDrvMde21" 19 "SelDrvMde20" 18 "SelDrvMde19" 17 "SelDrvMde18" 16 "SelDrvMde17" 15 "SelDrvMde16" 14 "SelDrvMde15" 13 "SelDrvMde14" 12 "SelDrvMde13" 11 "SelDrvMde12" 10 "SelDrvMde11" 9 "SelDrvMde10" 8 "SelDrvMde09" 7 "SelDrvMde08" 6 "SelDrvMde07" 5 "SelDrvMde06" 4 "SelDrvMde05" 3 "SelDrvMde04" 2 "SelDrvMde03" 1 "SelDrvMde02" 0 "SelDrvMde01" ;
VAL_ 1102 SelDrvMdePos07_D_Stat 31 "Faulty" 30 "SelDrvMde31" 29 "SelDrvMde30" 28 "SelDrvMde29" 27 "SelDrvMde28" 26 "SelDrvMde27" 25 "SelDrvMde26" 24 "SelDrvMde25" 23 "SelDrvMde24" 22 "SelDrvMde23" 21 "SelDrvMde22" 20 "SelDrvMde21" 19 "SelDrvMde20" 18 "SelDrvMde19" 17 "SelDrvMde18" 16 "SelDrvMde17" 15 "SelDrvMde16" 14 "SelDrvMde15" 13 "SelDrvMde14" 12 "SelDrvMde13" 11 "SelDrvMde12" 10 "SelDrvMde11" 9 "SelDrvMde10" 8 "SelDrvMde09" 7 "SelDrvMde08" 6 "SelDrvMde07" 5 "SelDrvMde06" 4 "SelDrvMde05" 3 "SelDrvMde04" 2 "SelDrvMde03" 1 "SelDrvMde02" 0 "SelDrvMde01" ;
VAL_ 1102 SelDrvMdePos06_D_Stat 31 "Faulty" 30 "SelDrvMde31" 29 "SelDrvMde30" 28 "SelDrvMde29" 27 "SelDrvMde28" 26 "SelDrvMde27" 25 "SelDrvMde26" 24 "SelDrvMde25" 23 "SelDrvMde24" 22 "SelDrvMde23" 21 "SelDrvMde22" 20 "SelDrvMde21" 19 "SelDrvMde20" 18 "SelDrvMde19" 17 "SelDrvMde18" 16 "SelDrvMde17" 15 "SelDrvMde16" 14 "SelDrvMde15" 13 "SelDrvMde14" 12 "SelDrvMde13" 11 "SelDrvMde12" 10 "SelDrvMde11" 9 "SelDrvMde10" 8 "SelDrvMde09" 7 "SelDrvMde08" 6 "SelDrvMde07" 5 "SelDrvMde06" 4 "SelDrvMde05" 3 "SelDrvMde04" 2 "SelDrvMde03" 1 "SelDrvMde02" 0 "SelDrvMde01" ;
VAL_ 1102 SelDrvMdePos05_D_Stat 31 "Faulty" 30 "SelDrvMde31" 29 "SelDrvMde30" 28 "SelDrvMde29" 27 "SelDrvMde28" 26 "SelDrvMde27" 25 "SelDrvMde26" 24 "SelDrvMde25" 23 "SelDrvMde24" 22 "SelDrvMde23" 21 "SelDrvMde22" 20 "SelDrvMde21" 19 "SelDrvMde20" 18 "SelDrvMde19" 17 "SelDrvMde18" 16 "SelDrvMde17" 15 "SelDrvMde16" 14 "SelDrvMde15" 13 "SelDrvMde14" 12 "SelDrvMde13" 11 "SelDrvMde12" 10 "SelDrvMde11" 9 "SelDrvMde10" 8 "SelDrvMde09" 7 "SelDrvMde08" 6 "SelDrvMde07" 5 "SelDrvMde06" 4 "SelDrvMde05" 3 "SelDrvMde04" 2 "SelDrvMde03" 1 "SelDrvMde02" 0 "SelDrvMde01" ;
VAL_ 1102 SelDrvMdePos04_D_Stat 31 "Faulty" 30 "SelDrvMde31" 29 "SelDrvMde30" 28 "SelDrvMde29" 27 "SelDrvMde28" 26 "SelDrvMde27" 25 "SelDrvMde26" 24 "SelDrvMde25" 23 "SelDrvMde24" 22 "SelDrvMde23" 21 "SelDrvMde22" 20 "SelDrvMde21" 19 "SelDrvMde20" 18 "SelDrvMde19" 17 "SelDrvMde18" 16 "SelDrvMde17" 15 "SelDrvMde16" 14 "SelDrvMde15" 13 "SelDrvMde14" 12 "SelDrvMde13" 11 "SelDrvMde12" 10 "SelDrvMde11" 9 "SelDrvMde10" 8 "SelDrvMde09" 7 "SelDrvMde08" 6 "SelDrvMde07" 5 "SelDrvMde06" 4 "SelDrvMde05" 3 "SelDrvMde04" 2 "SelDrvMde03" 1 "SelDrvMde02" 0 "SelDrvMde01" ;
VAL_ 1102 SelDrvMdePos03_D_Stat 31 "Faulty" 30 "SelDrvMde31" 29 "SelDrvMde30" 28 "SelDrvMde29" 27 "SelDrvMde28" 26 "SelDrvMde27" 25 "SelDrvMde26" 24 "SelDrvMde25" 23 "SelDrvMde24" 22 "SelDrvMde23" 21 "SelDrvMde22" 20 "SelDrvMde21" 19 "SelDrvMde20" 18 "SelDrvMde19" 17 "SelDrvMde18" 16 "SelDrvMde17" 15 "SelDrvMde16" 14 "SelDrvMde15" 13 "SelDrvMde14" 12 "SelDrvMde13" 11 "SelDrvMde12" 10 "SelDrvMde11" 9 "SelDrvMde10" 8 "SelDrvMde09" 7 "SelDrvMde08" 6 "SelDrvMde07" 5 "SelDrvMde06" 4 "SelDrvMde05" 3 "SelDrvMde04" 2 "SelDrvMde03" 1 "SelDrvMde02" 0 "SelDrvMde01" ;
VAL_ 1102 SelDrvMdePos02_D_Stat 31 "Faulty" 30 "SelDrvMde31" 29 "SelDrvMde30" 28 "SelDrvMde29" 27 "SelDrvMde28" 26 "SelDrvMde27" 25 "SelDrvMde26" 24 "SelDrvMde25" 23 "SelDrvMde24" 22 "SelDrvMde23" 21 "SelDrvMde22" 20 "SelDrvMde21" 19 "SelDrvMde20" 18 "SelDrvMde19" 17 "SelDrvMde18" 16 "SelDrvMde17" 15 "SelDrvMde16" 14 "SelDrvMde15" 13 "SelDrvMde14" 12 "SelDrvMde13" 11 "SelDrvMde12" 10 "SelDrvMde11" 9 "SelDrvMde10" 8 "SelDrvMde09" 7 "SelDrvMde08" 6 "SelDrvMde07" 5 "SelDrvMde06" 4 "SelDrvMde05" 3 "SelDrvMde04" 2 "SelDrvMde03" 1 "SelDrvMde02" 0 "SelDrvMde01" ;
VAL_ 1102 SelDrvMdePos01_D_Stat 31 "Faulty" 30 "SelDrvMde31" 29 "SelDrvMde30" 28 "SelDrvMde29" 27 "SelDrvMde28" 26 "SelDrvMde27" 25 "SelDrvMde26" 24 "SelDrvMde25" 23 "SelDrvMde24" 22 "SelDrvMde23" 21 "SelDrvMde22" 20 "SelDrvMde21" 19 "SelDrvMde20" 18 "SelDrvMde19" 17 "SelDrvMde18" 16 "SelDrvMde17" 15 "SelDrvMde16" 14 "SelDrvMde15" 13 "SelDrvMde14" 12 "SelDrvMde13" 11 "SelDrvMde12" 10 "SelDrvMde11" 9 "SelDrvMde10" 8 "SelDrvMde09" 7 "SelDrvMde08" 6 "SelDrvMde07" 5 "SelDrvMde06" 4 "SelDrvMde05" 3 "SelDrvMde04" 2 "SelDrvMde03" 1 "SelDrvMde02" 0 "SelDrvMde01" ;
VAL_ 1056 VehVActlBrk_No_Corr 255 "Faulty" 254 "NoDataExists" ;
VAL_ 1056 SelDrvMdePos12_B_Avail 1 "Available" 0 "NotAvailable" ;
VAL_ 1056 SelDrvMdePos11_B_Avail 1 "Available" 0 "NotAvailable" ;
VAL_ 1056 SelDrvMdePos10_B_Avail 1 "Available" 0 "NotAvailable" ;
VAL_ 1056 SelDrvMdePos09_B_Avail 1 "Available" 0 "NotAvailable" ;
VAL_ 1056 SelDrvMdePos08_B_Avail 1 "Available" 0 "NotAvailable" ;
VAL_ 1056 SelDrvMdePos07_B_Avail 1 "Available" 0 "NotAvailable" ;
VAL_ 1056 SelDrvMdePos06_B_Avail 1 "Available" 0 "NotAvailable" ;
VAL_ 1056 SelDrvMdePos05_B_Avail 1 "Available" 0 "NotAvailable" ;
VAL_ 1056 SelDrvMdePos04_B_Avail 1 "Available" 0 "NotAvailable" ;
VAL_ 1056 SelDrvMdePos03_B_Avail 1 "Available" 0 "NotAvailable" ;
VAL_ 1056 SelDrvMdePos02_B_Avail 1 "Available" 0 "NotAvailable" ;
VAL_ 1056 SelDrvMdePos01_B_Avail 1 "Available" 0 "NotAvailable" ;
VAL_ 1056 ActvDrvMde_D2_Stat 31 "Faulty" 30 "SelDrvMde31" 29 "SelDrvMde30" 28 "SelDrvMde29" 27 "SelDrvMde28" 26 "SelDrvMde27" 25 "SelDrvMde26" 24 "SelDrvMde25" 23 "SelDrvMde24" 22 "SelDrvMde23" 21 "SelDrvMde22" 20 "SelDrvMde21" 19 "SelDrvMde20" 18 "SelDrvMde19" 17 "SelDrvMde18" 16 "SelDrvMde17" 15 "SelDrvMde16" 14 "SelDrvMde15" 13 "SelDrvMde14" 12 "SelDrvMde13" 11 "SelDrvMde12" 10 "SelDrvMde11" 9 "SelDrvMde10" 8 "SelDrvMde09" 7 "SelDrvMde08" 6 "SelDrvMde07" 5 "SelDrvMde06" 4 "SelDrvMde05" 3 "SelDrvMde04" 2 "SelDrvMde03" 1 "SelDrvMde02" 0 "SelDrvMde01" ;
VAL_ 1056 SelDrvMde_D2_Rq 31 "Faulty" 30 "SelDrvMde31" 29 "SelDrvMde30" 28 "SelDrvMde29" 27 "SelDrvMde28" 26 "SelDrvMde27" 25 "SelDrvMde26" 24 "SelDrvMde25" 23 "SelDrvMde24" 22 "SelDrvMde23" 21 "SelDrvMde22" 20 "SelDrvMde21" 19 "SelDrvMde20" 18 "SelDrvMde19" 17 "SelDrvMde18" 16 "SelDrvMde17" 15 "SelDrvMde16" 14 "SelDrvMde15" 13 "SelDrvMde14" 12 "SelDrvMde13" 11 "SelDrvMde12" 10 "SelDrvMde11" 9 "SelDrvMde10" 8 "SelDrvMde09" 7 "SelDrvMde08" 6 "SelDrvMde07" 5 "SelDrvMde06" 4 "SelDrvMde05" 3 "SelDrvMde04" 2 "SelDrvMde03" 1 "SelDrvMde02" 0 "SelDrvMde01" ;
VAL_ 1056 SelDrvMdePt_D_Rq 31 "Faulty" 30 "NotUsed15" 29 "NotUsed14" 28 "NotUsed13" 27 "NotUsed12" 26 "NotUsed11" 25 "NotUsed10" 24 "NotUsed9" 23 "NotUsed8" 22 "NotUsed7" 21 "CustomMode" 20 "TrackMode" 19 "OnePedalDrive" 18 "EvLaterChargerMode" 17 "EvNowMode" 16 "DragMode" 15 "HighSpeedDesertMode_Baja" 14 "SportAdaptiveMode" 13 "NotAvailable_13" 12 "NotAvailable_12" 11 "NotAvailable_11" 10 "NotAvailable_10" 9 "RockCrawlMode" 8 "MudRutsMode" 7 "SandMode" 6 "EconomyMode" 5 "GrassGravelSnow" 4 "NotAvailable_04" 3 "TowHaulMode" 2 "NotAvailable_02" 1 "SportMode" 0 "NormalMode" ;
VAL_ 1056 SelDrvMdeMsgTxt_D_Rq 15 "Message15" 14 "Message14" 13 "Message13" 12 "Message12" 11 "Message11" 10 "Message10" 9 "Message9" 8 "Message8" 7 "Message7" 6 "Message6" 5 "Message5" 4 "Message4" 3 "Message3" 2 "Message2" 1 "Message1" 0 "NoMessage" ;
VAL_ 1056 SelDrvMde_D_Stat 3 "NotUsed" 2 "DriveModeChangeRequest" 1 "DriveModeChangeSelection" 0 "NoDriveModeChangeRequest" ;
VAL_ 1056 AwdMde_D_RqBrk 7 "Faulty" 6 "NotUsed2" 5 "NoRequest" 4 "Neutral" 3 "FourByFourLow" 2 "FourByFourHigh" 1 "FourByFourAuto" 0 "FourByTwo" ;
VAL_ 1056 SelDrvMdeMsgTxt2_D_Rq 15 "Message15" 14 "Message14" 13 "Message13" 12 "Message12" 11 "Message11" 10 "Message10" 9 "Message9" 8 "Message8" 7 "Message7" 6 "Message6" 5 "Message5" 4 "Message4" 3 "Message3" 2 "Message2" 1 "Message1" 0 "NoMessage" ;
VAL_ 1056 SelDrvMdeHmi03_D_Rq 31 "Faulty" 30 "SelDrvMde31" 29 "SelDrvMde30" 28 "SelDrvMde29" 27 "SelDrvMde28" 26 "SelDrvMde27" 25 "SelDrvMde26" 24 "SelDrvMde25" 23 "SelDrvMde24" 22 "SelDrvMde23" 21 "SelDrvMde22" 20 "SelDrvMde21" 19 "SelDrvMde20" 18 "SelDrvMde19" 17 "SelDrvMde18" 16 "SelDrvMde17" 15 "SelDrvMde16" 14 "SelDrvMde15" 13 "SelDrvMde14" 12 "SelDrvMde13" 11 "SelDrvMde12" 10 "SelDrvMde11" 9 "SelDrvMde10" 8 "SelDrvMde09" 7 "SelDrvMde08" 6 "SelDrvMde07" 5 "SelDrvMde06" 4 "SelDrvMde05" 3 "SelDrvMde04" 2 "SelDrvMde03" 1 "SelDrvMde02" 0 "SelDrvMde01" ;
VAL_ 1054 RbaBrk_D_Stat 3 "Denied" 2 "Active" 1 "Open" 0 "Closed" ;
VAL_ 1054 SelDrvMdeChassis2_D_Rq 31 "Faulty" 30 "NotUsed17" 29 "NotUsed16" 28 "NotUsed15" 27 "NotUsed14" 26 "NotUsed13" 25 "NotUsed12" 24 "NotUsed11" 23 "NotUsed10" 22 "NotUsed9" 21 "NotUsed8" 20 "NotUsed7" 19 "NotUsed6" 18 "NotUsed5" 17 "NotUsed4" 16 "OnePedalDrive" 15 "DragMode" 14 "RoughRoadMode" 13 "TrackMode" 12 "HighSpeedDesertMode" 11 "TowHaulMode" 10 "RockCrawlMode" 9 "SandMode" 8 "MudAndRutsMode" 7 "LowMuMode" 6 "ComfortAdaptiveMode" 5 "ComfortMode" 4 "SportAdaptiveMode" 3 "SportMode" 2 "EconomyMode" 1 "NormalAdaptiveMode" 0 "NormalMode" ;
VAL_ 1054 BrkPadMsgTxt_D_Rq 3 "Faulty" 2 "PadsOk" 1 "ReplacePads" 0 "Null" ;
VAL_ 1054 BrkBstrVac_D_Stat 3 "NotUsed" 2 "BoosterVacEstimator" 1 "BoosterVacSensor" 0 "NoBoosterVacuumMonitor" ;
VAL_ 1054 DrvSlipCtlOffLamp_D_Rq 3 "Fast_Flash" 2 "Slow_Flash" 1 "On" 0 "Off" ;
VAL_ 1054 DrvSlipCtlMdeMsg_D_Rq 31 "Message31" 30 "Message30" 29 "Message29" 28 "Message28" 27 "Message27" 26 "Message26" 25 "Message25" 24 "Message24" 23 "Message23" 22 "Message22" 21 "Message21" 20 "Message20" 19 "Message19" 18 "Message18" 17 "Message17" 16 "Message16" 15 "Message15" 14 "Message14" 13 "Message13" 12 "Message12" 11 "Message11" 10 "Message10" 9 "Message9" 8 "Message8" 7 "Message7" 6 "Message6" 5 "Message5" 4 "Message4" 3 "Message3" 2 "Message2" 1 "Message1" 0 "NoMessage" ;
VAL_ 1054 AutoHoldMsgTxt_D_Rq 15 "Message15" 14 "Message14" 13 "Message13" 12 "Message12" 11 "Message11" 10 "Message10" 9 "Message9" 8 "Message8" 7 "Message7" 6 "Message6" 5 "Message5" 4 "Message4" 3 "Message3" 2 "Message2" 1 "Message1" 0 "NoMessage" ;
VAL_ 1054 CtaBrk_D_Stat 3 "Denied" 2 "Active" 1 "Open" 0 "Closed" ;
VAL_ 1054 SelDrvMdeAwd_D_Rq 31 "Faulty" 30 "NotUsed_17" 29 "NotUsed_16" 28 "NotUsed_15" 27 "NotUsed_14" 26 "NotUsed_13" 25 "NotUsed_12" 24 "NotUsed_11" 23 "NotUsed_10" 22 "NotUsed_9" 21 "NotUsed_8" 20 "CustomMode" 19 "OnePedalDrive" 18 "DragMode" 17 "EvLaterChargeMode" 16 "EvNowMode" 15 "TrackMode" 14 "RoughRoadMode" 13 "NotAvailable" 12 "HighSpeedDesertMode_Baja" 11 "SportAdaptiveMode" 10 "RockCrawlMode" 9 "MudRutsMode" 8 "SandMode" 7 "EconomyMode" 6 "GrassGravelSnow" 5 "TowHaulMode" 4 "SportMode" 3 "Normal_4L" 2 "Normal_4A" 1 "Normal_2H" 0 "NormalMode" ;
VAL_ 1054 AutoHoldSwMde_B_Ind 1 "On" 0 "Off" ;
VAL_ 1054 AutoHoldMde_D_Ind 3 "Indication_3" 2 "Indication_2" 1 "Indication_1" 0 "Off" ;
VAL_ 1054 SelDrvMdeChassis_D_Rq 31 "Faulty" 30 "NotUsed17" 29 "NotUsed16" 28 "NotUsed15" 27 "NotUsed14" 26 "NotUsed13" 25 "NotUsed12" 24 "NotUsed11" 23 "NotUsed10" 22 "NotUsed9" 21 "NotUsed8" 20 "NotUsed7" 19 "NotUsed6" 18 "NotUsed5" 17 "NotUsed4" 16 "OnePedalDrive" 15 "DragMode" 14 "RoughRoadMode" 13 "TrackMode" 12 "HighSpeedDesertMode" 11 "TowHaulMode" 10 "RockCrawlMode" 9 "SandMode" 8 "MudAndRutsMode" 7 "LowMuMode" 6 "ComfortAdaptiveMode" 5 "ComfortMode" 4 "SportAdaptiveMode" 3 "SportMode" 2 "EconomyMode" 1 "NormalAdaptiveMode" 0 "NormalMode" ;
VAL_ 1054 ApaBrk_D_Stat 3 "Denied" 2 "Active" 1 "Open" 0 "Closed" ;
VAL_ 1054 FrontDiffElckrOpen_B_Rq 1 "Yes" 0 "No" ;
VAL_ 1046 HsaMde_D_Mem 3 "Undefined" 2 "Manual" 1 "Automatic" 0 "Off" ;
VAL_ 1046 BrkBstrVac_B_Rq 1 "Yes" 0 "No" ;
VAL_ 1046 TRLR_SWAY_EVNT_IN_PROG 1 "Yes" 0 "No" ;
VAL_ 1046 TRLR_SWAY_CONFIG_STAT 1 "On" 0 "Off" ;
VAL_ 1046 TCMode 1 "Active" 0 "Inactive" ;
VAL_ 1046 DrvSlipCtlLamp_D_Rq 3 "Fast_Flash" 2 "Slow_Flash" 1 "On" 0 "Off" ;
VAL_ 1046 Abs_B_Falt 1 "Yes" 0 "No" ;
VAL_ 1046 DrvSlipCtlMde_D_Ind 3 "App_Specific_Off_Mode_3" 2 "App_Specific_Off_Mode_2" 1 "App_Specific_Off_Mode_1" 0 "Default_Mode" ;
VAL_ 1046 DrvAntiLckLamp_D_Rq 3 "Fast_Flash" 2 "Slow_Flash" 1 "On" 0 "Off" ;
VAL_ 1046 StabCtlBrk_B_Avail 1 "Yes" 0 "No" ;
VAL_ 1046 BpedMove_D_Actl 3 "Unknown" 2 "DriverApplyingBrakePedal" 1 "NoAutonomousBrkPdlMovement" 0 "AutonomousBrkPedalMove" ;
VAL_ 1046 ChimeBrk_B_Rq 1 "Yes" 0 "No" ;
VAL_ 1046 BrkLamp_B_Rq 1 "Yes" 0 "No" ;
VAL_ 1046 RearDiffElckrOpen_B_Rq 1 "Yes" 0 "No" ;
VAL_ 1045 VehStab_D_Stat 15 "Faulty" 14 "No_Data_Exists" 13 "NotUsed6" 12 "NotUsed5" 11 "NotUsed4" 10 "NotUsed3" 9 "NotUsed2" 8 "Combined_OS_and_US" 7 "High_SSRA_no_OS" 6 "Straight" 5 "Post_Oversteer" 4 "Post_Transition" 3 "Countersteer" 2 "Understeer" 1 "Oversteer" 0 "Linear" ;
VAL_ 1045 BrkFluidLvl_D_Stat 3 "Invalid" 2 "Unknown" 1 "Low" 0 "OK" ;
VAL_ 1045 VehYawNonLin_W_Rq 4095 "Fault" 4094 "Unknown" ;
VAL_ 1045 VehYawLin_W_Rq 4095 "Fault" 4094 "Unknown" ;
VAL_ 1045 VehVActlBrk_D_Qf 3 "OK" 2 "Not_Within_Specifications" 1 "No_Data_Exists" 0 "Faulty" ;
VAL_ 1044 ApaBrkErr_D_Stat 3 "Faulty" 2 "NoDataExists" 1 "Yes" 0 "No" ;
VAL_ 1044 StePinOffst_An_Est 65535 "Faulty" 65534 "NoDataExists" ;
VAL_ 1044 StePinOffst_D_Stat 3 "FineOffset" 2 "CoarseOffset" 1 "StoredOffset" 0 "OffsetNotCalculated" ;
VAL_ 1042 VehRol_An_Dsply 127 "Faulty" 126 "NoDataExists" ;
VAL_ 1042 VehPtch_An_Dsply 127 "Faulty" 126 "NoDataExists" ;
